VERSION "HNNBNNNYNNNNNNNNNNNNNNNNNNNNNNNNNNNNNNNNNN/4/%%%/4/'%**4NNN///"

NS_ :

BS_:

BU_: ecu_pri3_1 ecu_pri3_2 ecu_sec1_1 ecu_pri1_1 ecu_sec1_2 unused_8 unused_2 ecu_sec3_2 ecu_sec3_1 unused_1 unused_4 unused_9 unused_3 ecu_pri3_3 unused_6 unused_5 unused_7 measure

BO_ 3221225472 VECTOR__INDEPENDENT_SIG_MSG: 0 Vector__XXX
 SG_ signal5166 : 0|64@1+ (1,0) [0|1] "" Vector__XXX
 SG_ signal12359 : 0|64@1+ (1,0) [0|1] "" Vector__XXX
 SG_ signal12444 : 0|64@1+ (1,0) [0|1] "" Vector__XXX

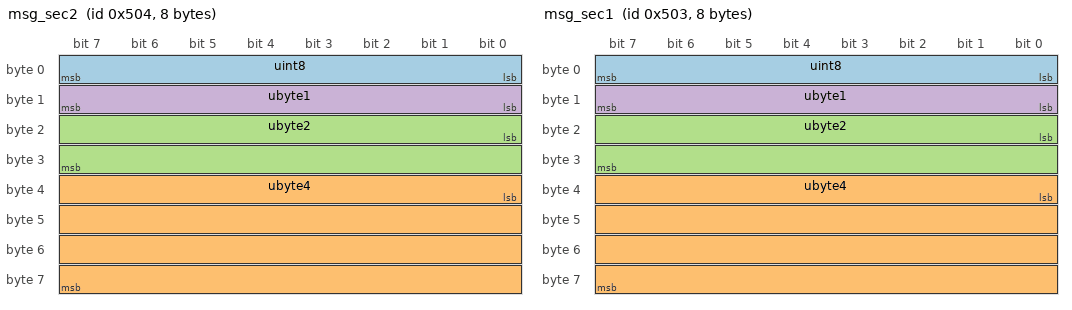
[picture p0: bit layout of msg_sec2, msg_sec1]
BO_ 1284 msg_sec2: 8 ecu_sec3_1
 SG_ uint8 : 0|8@1+ (1,0) [0|0] ""  unused_9,unused_8,unused_7,unused_6,unused_5,unused_4,unused_3,unused_2,unused_1,measure
 SG_ ubyte4 : 32|32@1+ (1,0) [0|0] ""  unused_9,unused_8,unused_7,unused_6,unused_5,unused_4,unused_3,unused_2,unused_1,measure
 SG_ ubyte2 : 16|16@1+ (1,0) [0|0] ""  unused_9,unused_8,unused_7,unused_6,unused_5,unused_4,unused_3,unused_2,unused_1,measure
 SG_ ubyte1 : 8|8@1+ (1,0) [0|0] ""  unused_9,unused_8,unused_7,unused_6,unused_5,unused_4,unused_3,unused_2,unused_1,measure

BO_ 1283 msg_sec1: 8 ecu_sec1_1
 SG_ uint8 : 0|8@1+ (1,0) [0|0] ""  unused_9,unused_8,unused_7,unused_6,unused_5,unused_4,unused_3,unused_2,unused_1,measure
 SG_ ubyte4 : 32|32@1+ (1,0) [0|0] ""  unused_9,unused_8,unused_7,unused_6,unused_5,unused_4,unused_3,unused_2,unused_1,measure
 SG_ ubyte2 : 16|16@1+ (1,0) [0|0] ""  unused_9,unused_8,unused_7,unused_6,unused_5,unused_4,unused_3,unused_2,unused_1,measure
 SG_ ubyte1 : 8|8@1+ (1,0) [0|0] ""  unused_9,unused_8,unused_7,unused_6,unused_5,unused_4,unused_3,unused_2,unused_1,measure

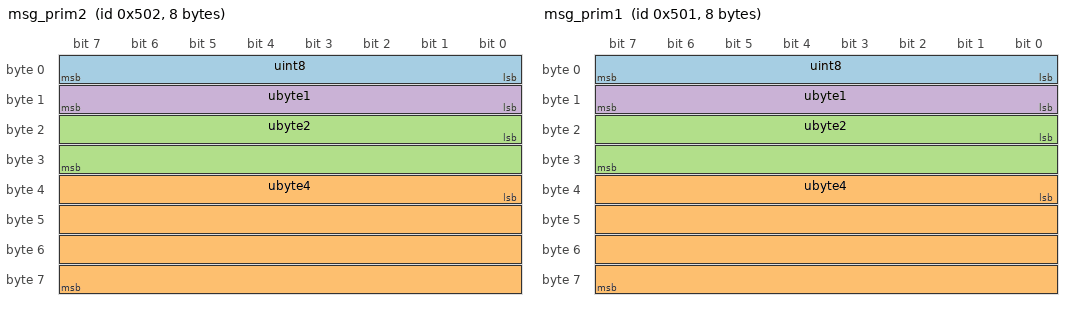
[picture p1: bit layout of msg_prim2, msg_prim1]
BO_ 1282 msg_prim2: 8 ecu_pri3_1
 SG_ uint8 : 0|8@1+ (1,0) [0|0] ""  unused_9,unused_8,unused_7,unused_6,unused_5,unused_4,unused_3,unused_2,unused_1,measure
 SG_ ubyte4 : 32|32@1+ (1,0) [0|0] ""  unused_9,unused_8,unused_7,unused_6,unused_5,unused_4,unused_3,unused_2,unused_1,measure
 SG_ ubyte2 : 16|16@1+ (1,0) [0|0] ""  unused_9,unused_8,unused_7,unused_6,unused_5,unused_4,unused_3,unused_2,unused_1,measure
 SG_ ubyte1 : 8|8@1+ (1,0) [0|0] ""  unused_9,unused_8,unused_7,unused_6,unused_5,unused_4,unused_3,unused_2,unused_1,measure

BO_ 1281 msg_prim1: 8 ecu_pri1_1
 SG_ uint8 : 0|8@1+ (1,0) [0|0] ""  unused_9,unused_8,unused_7,unused_6,unused_5,unused_4,unused_3,unused_2,unused_1,measure
 SG_ ubyte4 : 32|32@1+ (1,0) [0|0] ""  unused_9,unused_8,unused_7,unused_6,unused_5,unused_4,unused_3,unused_2,unused_1,measure
 SG_ ubyte2 : 16|16@1+ (1,0) [0|0] ""  unused_9,unused_8,unused_7,unused_6,unused_5,unused_4,unused_3,unused_2,unused_1,measure
 SG_ ubyte1 : 8|8@1+ (1,0) [0|0] ""  unused_9,unused_8,unused_7,unused_6,unused_5,unused_4,unused_3,unused_2,unused_1,measure

BO_ 64 msg_1027: 8 ecu_pri3_1
 SG_ signal1032 : 0|8@1+ (1,0) [0|255] ""  ecu_pri3_2,ecu_pri1_1,ecu_sec3_1,unused_1,unused_4,measure
 SG_ signal1027_BZ : 8|4@1+ (1,0) [0|15] ""  ecu_pri3_2,ecu_pri1_1,ecu_sec3_1,unused_1,unused_4,measure
 SG_ signal1062 : 16|1@1+ (1,0) [0|1] ""  ecu_pri1_1,measure
 SG_ signal1073 : 17|1@1+ (1,0) [0|1] ""  ecu_pri1_1,measure
 SG_ signal1084 : 18|1@1+ (1,0) [0|1] ""  ecu_pri1_1,measure
 SG_ signal1095 : 19|1@1+ (1,0) [0|1] ""  ecu_pri1_1,measure
 SG_ signal1106 : 20|1@1+ (1,0) [0|1] ""  ecu_pri1_1,measure
 SG_ signal1117 : 21|3@1+ (1,0) [0|7] ""  ecu_pri1_1,ecu_sec3_1,unused_1,unused_4,unused_6,measure
 SG_ signal1132 : 24|1@1+ (1,0) [0|1] ""  ecu_pri1_1,measure
 SG_ signal1143 : 25|1@1+ (1,0) [0|1] ""  ecu_pri1_1,measure
 SG_ signal1154 : 26|1@1+ (1,0) [0|1] ""  ecu_pri1_1,measure
 SG_ signal1165 : 27|1@1+ (1,0) [0|1] ""  ecu_pri1_1,measure
 SG_ signal1176 : 28|1@1+ (1,0) [0|1] ""  ecu_pri1_1,measure
 SG_ signal1187 : 29|1@1+ (1,0) [0|1] ""  ecu_pri1_1,ecu_sec3_1,unused_1,unused_4,unused_6,measure
 SG_ signal1202 : 30|2@1+ (1,0) [0|3] ""  ecu_pri1_1,measure
 SG_ signal1213 : 32|1@1+ (1,0) [0|1] ""  ecu_pri3_2,ecu_pri1_1,measure
 SG_ signal1225 : 33|1@1+ (1,0) [0|1] ""  ecu_pri1_1,measure
 SG_ signal1236 : 34|2@1+ (1,0) [0|3] ""  ecu_pri1_1,measure
 SG_ signal1247 : 40|8@1+ (1,0) [0|255] ""  ecu_pri1_1,measure
 SG_ signal1258 : 48|8@1+ (1,0) [0|255] ""  ecu_pri1_1,measure
 SG_ signal1269 : 56|7@1+ (1,0) [0|127] ""  ecu_pri1_1,measure
 SG_ signal1280 : 63|1@1+ (1,0) [0|1] ""  ecu_pri1_1,measure

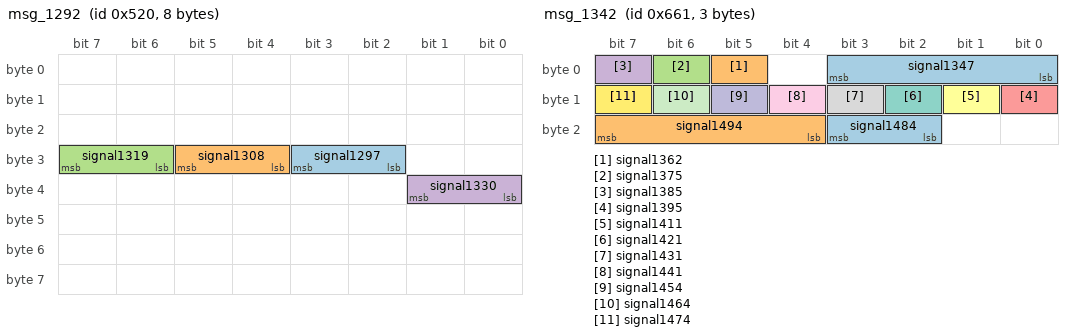
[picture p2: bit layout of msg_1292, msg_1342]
BO_ 1312 msg_1292: 8 ecu_pri3_1
 SG_ signal1297 : 26|2@1+ (1,0) [0|3] ""  ecu_pri1_1,measure
 SG_ signal1308 : 28|2@1+ (1,0) [0|3] ""  ecu_pri1_1,measure
 SG_ signal1319 : 30|2@1+ (1,0) [0|3] ""  ecu_pri1_1,measure
 SG_ signal1330 : 32|2@1+ (1,0) [0|3] ""  ecu_pri1_1,measure

BO_ 1633 msg_1342: 3 ecu_pri1_1
 SG_ signal1347 : 0|4@1+ (1,0) [0|15] ""  ecu_sec1_2,unused_8,ecu_sec3_1,unused_1,unused_4,measure
 SG_ signal1362 : 5|1@1+ (1,0) [0|1] ""  ecu_sec3_1,unused_1,unused_4,measure
 SG_ signal1375 : 6|1@1+ (1,0) [0|1] ""  unused_7,measure
 SG_ signal1385 : 7|1@1+ (1,0) [0|1] ""  unused_7,measure
 SG_ signal1395 : 8|1@1+ (1,0) [0|1] ""  ecu_sec1_2,unused_8,unused_2,ecu_sec3_1,unused_1,unused_4,measure
 SG_ signal1411 : 9|1@1+ (1,0) [0|1] ""  unused_7,measure
 SG_ signal1421 : 10|1@1+ (1,0) [0|1] ""  unused_7,measure
 SG_ signal1431 : 11|1@1+ (1,0) [0|1] ""  unused_7,measure
 SG_ signal1441 : 12|1@1+ (1,0) [0|1] ""  ecu_sec3_1,unused_1,unused_4,measure
 SG_ signal1454 : 13|1@1+ (1,0) [0|1] ""  unused_7,measure
 SG_ signal1464 : 14|1@1+ (1,0) [0|1] ""  unused_7,measure
 SG_ signal1474 : 15|1@1+ (1,0) [0|1] ""  unused_7,measure
 SG_ signal1484 : 18|2@1+ (1,0) [0|3] ""  unused_7,measure
 SG_ signal1494 : 20|4@1+ (1,0) [0|15] ""  unused_7,measure

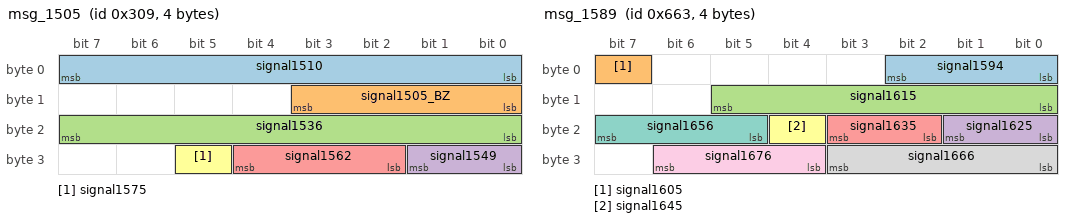
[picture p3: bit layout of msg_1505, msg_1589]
BO_ 777 msg_1505: 4 ecu_pri1_1
 SG_ signal1510 : 0|8@1+ (1,0) [0|255] ""  ecu_sec3_1,unused_1,unused_4,measure
 SG_ signal1505_BZ : 8|4@1+ (1,0) [0|15] ""  ecu_sec3_1,unused_1,unused_4,measure
 SG_ signal1536 : 16|8@1+ (50,0) [0|12700] "W"  ecu_sec3_1,unused_1,unused_4,measure
 SG_ signal1549 : 24|2@1+ (1,0) [0|3] ""  ecu_sec3_1,unused_1,unused_4,measure
 SG_ signal1562 : 26|3@1+ (1,0) [0|7] ""  ecu_sec3_1,unused_1,unused_4,measure
 SG_ signal1575 : 29|1@1+ (1,0) [0|1] ""  ecu_sec3_1,unused_1,unused_4,measure

BO_ 1635 msg_1589: 4 ecu_pri1_1
 SG_ signal1594 : 0|3@1+ (1,0) [0|7] ""  unused_6,measure
 SG_ signal1605 : 7|1@1+ (1,0) [0|1] ""  unused_7,measure
 SG_ signal1615 : 8|6@1+ (50,-1000) [-1000|1000] "W"  unused_7,measure
 SG_ signal1625 : 16|2@1+ (1,0) [0|3] ""  unused_7,measure
 SG_ signal1635 : 18|2@1+ (1,0) [0|3] ""  unused_7,measure
 SG_ signal1645 : 20|1@1+ (1,0) [0|1] ""  unused_6,measure
 SG_ signal1656 : 21|3@1+ (1,0) [0|7] ""  unused_7,measure
 SG_ signal1666 : 24|4@1+ (10,0) [0|100] "%"  unused_7,measure
 SG_ signal1676 : 28|3@1+ (1,0) [0|7] ""  unused_7,measure

BO_ 482 msg_1687: 8 ecu_pri1_1
 SG_ signal1692 : 0|64@1+ (1,0) [0|1] ""  ecu_sec1_2,unused_8,unused_2,measure

BO_ 490 msg_1706: 8 ecu_sec1_2
 SG_ signal1706_Data : 0|64@1+ (1,0) [0|1] ""  unused_7,measure

BO_ 480 msg_1722: 8 ecu_pri1_1
 SG_ signal1727 : 0|64@1+ (1,0) [0|1] ""  ecu_sec3_1,unused_1,unused_4,measure

BO_ 2616986624 msg_1741: 8 unused_7
 SG_ signal1746 : 0|64@1+ (1,0) [0|1] ""  ecu_sec3_1,unused_1,unused_4,measure

BO_ 488 msg_1760: 8 ecu_sec3_1
 SG_ signal1765 : 0|64@1+ (1,0) [0|1] ""  unused_7,measure

BO_ 2616986625 msg_1776: 8 unused_4
 SG_ signal1781 : 0|64@1+ (1,0) [0|1] ""  unused_7,measure

BO_ 481 msg_1792: 8 ecu_pri1_1
 SG_ signal1792_Data : 0|64@1+ (1,0) [0|1] ""  unused_9,measure

BO_ 2616986629 msg_1809: 8 unused_7
 SG_ signal1814 : 0|64@1+ (1,0) [0|1] ""  unused_9,measure

BO_ 489 msg_1826: 8 unused_9
 SG_ signal1831 : 0|64@1+ (1,0) [0|1] ""  unused_7,measure

BO_ 2616986630 msg_1842: 8 unused_9
 SG_ signal1842_Data : 0|64@1+ (1,0) [0|1] ""  unused_7,measure

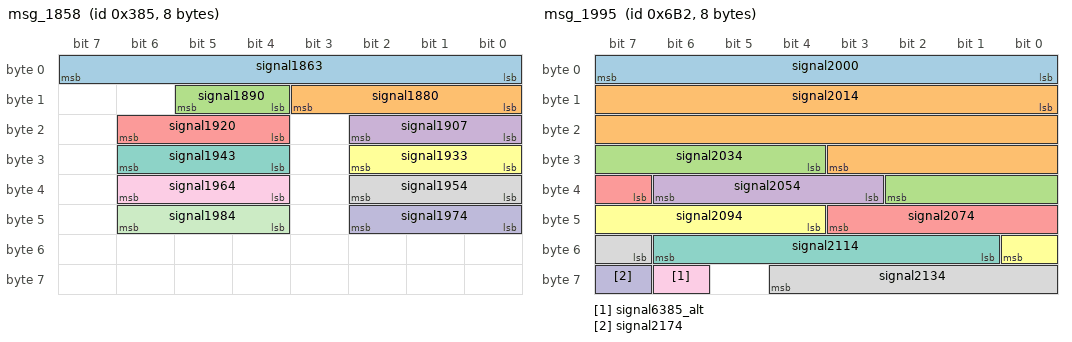
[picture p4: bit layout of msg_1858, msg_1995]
BO_ 901 msg_1858: 8 ecu_pri1_1
 SG_ signal1863 : 0|8@1+ (1,0) [0|255] ""  ecu_sec1_2,unused_8,unused_2,ecu_sec3_1,unused_1,unused_4,ecu_pri3_3,measure
 SG_ signal1880 : 8|4@1+ (1,0) [0|15] ""  unused_7,measure
 SG_ signal1890 : 12|2@1+ (1,0) [0|3] ""  ecu_sec1_2,unused_8,unused_2,ecu_sec3_1,unused_1,unused_4,ecu_pri3_3,measure
 SG_ signal1907 : 16|3@1+ (1,0) [0|7] ""  ecu_sec3_1,unused_1,unused_4,measure
 SG_ signal1920 : 20|3@1+ (1,0) [0|7] ""  ecu_sec1_2,unused_8,unused_2,measure
 SG_ signal1933 : 24|3@1+ (1,0) [0|7] ""  unused_7,measure
 SG_ signal1943 : 28|3@1+ (1,0) [0|7] ""  ecu_pri3_3,measure
 SG_ signal1954 : 32|3@1+ (1,0) [0|7] ""  unused_7,measure
 SG_ signal1964 : 36|3@1+ (1,0) [0|7] ""  unused_7,measure
 SG_ signal1974 : 40|3@1+ (1,0) [0|7] ""  unused_7,measure
 SG_ signal1984 : 44|3@1+ (1,0) [0|7] ""  unused_7,measure

BO_ 1714 msg_1995: 8 ecu_pri1_1
 SG_ signal2000 : 0|8@1+ (1,0) [0|254] ""  ecu_pri3_1,ecu_pri3_2,ecu_pri3_3,unused_6,measure
 SG_ signal2014 : 8|20@1+ (1,0) [0|1048573] "km"  ecu_pri3_1,ecu_pri3_2,ecu_sec1_2,unused_8,unused_2,ecu_sec3_1,unused_1,unused_4,ecu_pri3_3,unused_6,measure
 SG_ signal2034 : 28|7@1+ (1,2000) [2000|2127] ""  ecu_pri3_1,ecu_pri3_2,ecu_sec1_2,unused_8,unused_2,ecu_sec3_1,unused_1,unused_4,ecu_pri3_3,unused_6,measure
 SG_ signal2054 : 35|4@1+ (1,0) [1|12] "month"  ecu_pri3_1,ecu_pri3_2,ecu_sec1_2,unused_8,unused_2,ecu_sec3_1,unused_1,unused_4,ecu_pri3_3,unused_6,measure
 SG_ signal2074 : 39|5@1+ (1,0) [1|31] "d"  ecu_pri3_1,ecu_pri3_2,ecu_sec1_2,unused_8,unused_2,ecu_sec3_1,unused_1,unused_4,ecu_pri3_3,unused_6,measure
 SG_ signal2094 : 44|5@1+ (1,0) [0|23] "h"  ecu_pri3_1,ecu_pri3_2,ecu_sec1_2,unused_8,unused_2,ecu_sec3_1,unused_1,unused_4,ecu_pri3_3,unused_6,measure
 SG_ signal2114 : 49|6@1+ (1,0) [0|59] "min"  ecu_pri3_1,ecu_pri3_2,ecu_sec1_2,unused_8,unused_2,ecu_sec3_1,unused_1,unused_4,ecu_pri3_3,unused_6,measure
 SG_ signal2134 : 55|6@1+ (1,0) [0|59] "s"  ecu_pri3_1,ecu_pri3_2,ecu_sec1_2,unused_8,unused_2,ecu_sec3_1,unused_1,unused_4,ecu_pri3_3,unused_6,measure
 SG_ signal6385_alt : 62|1@1+ (1,0) [0|1] ""  ecu_pri3_1,ecu_pri3_2,ecu_sec1_2,unused_8,unused_2,ecu_sec3_1,unused_1,unused_4,ecu_pri3_3,unused_6,measure
 SG_ signal2174 : 63|1@1+ (1,0) [0|1] ""  ecu_pri3_1,ecu_pri3_2,ecu_sec1_2,unused_8,unused_2,ecu_sec3_1,unused_1,unused_4,ecu_pri3_3,unused_6,measure

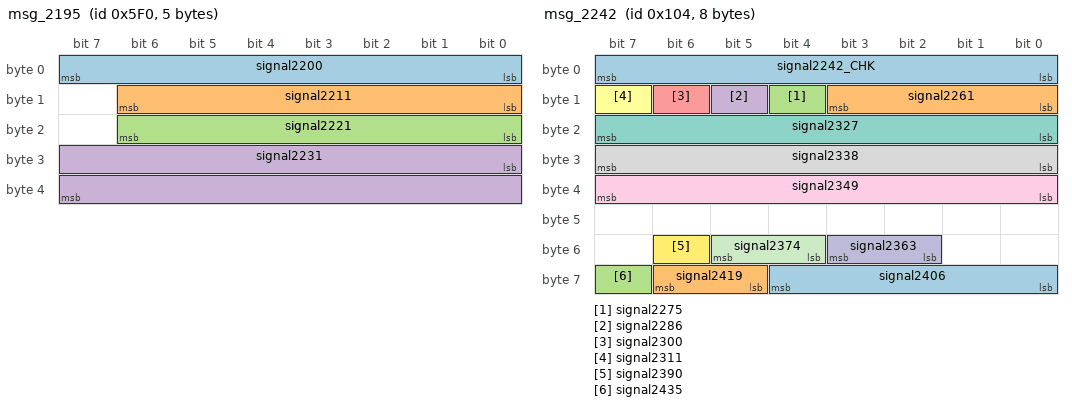
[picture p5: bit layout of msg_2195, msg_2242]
BO_ 1520 msg_2195: 5 ecu_pri1_1
 SG_ signal2200 : 0|8@1+ (1,0) [0|253] ""  ecu_pri3_1,measure
 SG_ signal2211 : 8|7@1+ (1,0) [0|100] "%"  unused_7,measure
 SG_ signal2221 : 16|7@1+ (1,0) [0|100] "%"  unused_7,measure
 SG_ signal2231 : 24|16@1+ (1,0) [0|65535] ""  unused_7,measure

BO_ 260 msg_2242: 8 ecu_pri3_2
 SG_ signal2242_CHK : 0|8@1+ (1,0) [0|255] ""  ecu_pri1_1,ecu_sec3_1,unused_1,unused_4,measure
 SG_ signal2261 : 8|4@1+ (1,0) [0|15] ""  ecu_pri1_1,ecu_sec3_1,unused_1,unused_4,measure
 SG_ signal2275 : 12|1@1+ (1,0) [0|1] ""  ecu_pri1_1,measure
 SG_ signal2286 : 13|1@1+ (1,0) [0|1] ""  ecu_pri1_1,ecu_sec3_1,unused_1,unused_4,measure
 SG_ signal2300 : 14|1@1+ (1,0) [0|1] ""  ecu_pri1_1,measure
 SG_ signal2311 : 15|1@1+ (1,0) [0|1] ""  ecu_pri1_1,ecu_sec1_2,unused_8,ecu_sec3_1,unused_1,unused_4,measure
 SG_ signal2327 : 16|8@1+ (0.048,-7.968) [-7.968|4.224] "signal5121"  ecu_pri1_1,measure
 SG_ signal2338 : 24|8@1+ (1,-128) [-128|126] "%g"  ecu_pri1_1,measure
 SG_ signal2349 : 32|8@1+ (0.4,0) [8|92] "%"  ecu_pri1_1,ecu_sec3_1,unused_1,unused_4,measure
 SG_ signal2363 : 50|2@1+ (1,0) [0|3] ""  ecu_pri1_1,measure
 SG_ signal2374 : 52|2@1+ (1,0) [0|3] ""  ecu_pri1_1,ecu_sec1_2,unused_8,ecu_sec3_1,unused_1,unused_4,measure
 SG_ signal2390 : 54|1@1+ (1,0) [0|1] ""  ecu_pri1_1,ecu_sec1_2,unused_8,ecu_sec3_1,unused_1,unused_4,measure
 SG_ signal2406 : 56|5@1+ (1,0) [0|29] "kN"  ecu_pri1_1,ecu_sec1_2,unused_8,measure
 SG_ signal2419 : 61|2@1+ (1,0) [0|3] ""  ecu_pri1_1,ecu_sec1_2,unused_8,ecu_sec3_1,unused_1,unused_4,measure
 SG_ signal2435 : 63|1@1+ (1,0) [0|1] ""  ecu_pri1_1,measure

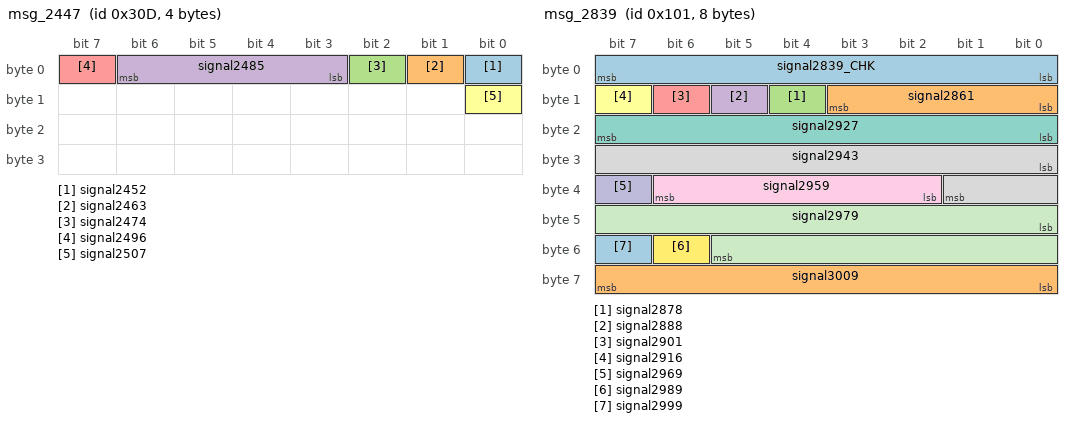
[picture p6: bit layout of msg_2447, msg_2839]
BO_ 781 msg_2447: 4 ecu_pri3_2
 SG_ signal2452 : 0|1@1+ (1,0) [0|1] ""  ecu_pri1_1,measure
 SG_ signal2463 : 1|1@1+ (1,0) [0|1] ""  ecu_pri1_1,measure
 SG_ signal2474 : 2|1@1+ (1,0) [0|1] ""  ecu_pri1_1,measure
 SG_ signal2485 : 3|4@1+ (1,0) [0|15] ""  ecu_pri1_1,measure
 SG_ signal2496 : 7|1@1+ (1,0) [0|1] ""  ecu_pri1_1,measure
 SG_ signal2507 : 8|1@1+ (1,0) [0|1] ""  ecu_pri1_1,measure

BO_ 256 msg_2519: 8 ecu_pri1_1
 SG_ signal2524 : 0|8@1+ (1,0) [0|255] ""  ecu_pri3_1,ecu_pri3_2,ecu_sec1_2,unused_8,unused_2,ecu_sec3_1,unused_1,unused_4,measure
 SG_ signal2519_BZ : 8|4@1+ (1,0) [0|15] ""  ecu_pri3_1,ecu_pri3_2,ecu_sec1_2,unused_8,unused_2,ecu_sec3_1,unused_1,unused_4,measure
 SG_ signal2560 : 12|10@1+ (1,0) [0|1021] ""  ecu_pri3_1,ecu_sec1_2,unused_8,ecu_sec3_1,unused_1,unused_4,measure
 SG_ signal2576 : 22|10@1+ (1,0) [0|1021] ""  ecu_pri3_1,ecu_sec1_2,unused_8,ecu_sec3_1,unused_1,unused_4,measure
 SG_ signal2592 : 32|16@1+ (0.01,0) [0|655.32] "km/h"  ecu_pri3_1,ecu_sec1_2,unused_8,ecu_sec3_1,unused_1,unused_4,measure
 SG_ signal2608 : 48|1@1+ (1,0) [0|1] ""  ecu_pri3_1,ecu_sec1_2,unused_8,unused_2,ecu_sec3_1,unused_1,unused_4,measure
 SG_ signal2625 : 49|1@1+ (1,0) [0|1] ""  ecu_pri3_1,ecu_sec1_2,unused_8,unused_2,ecu_sec3_1,unused_1,unused_4,measure
 SG_ signal2642 : 50|1@1+ (1,0) [0|1] ""  ecu_pri3_1,ecu_pri3_2,ecu_sec3_1,unused_1,unused_4,measure
 SG_ signal2657 : 51|2@1+ (1,0) [0|3] ""  ecu_pri3_1,ecu_sec1_2,unused_8,unused_2,measure
 SG_ signal2671 : 53|1@1+ (1,0) [0|1] ""  ecu_sec3_1,unused_1,unused_4,measure
 SG_ signal2684 : 54|1@1+ (1,0) [0|1] ""  ecu_sec3_1,unused_1,unused_4,measure
 SG_ signal2697 : 55|1@1+ (1,0) [0|1] ""  ecu_pri3_1,ecu_sec1_2,unused_8,ecu_sec3_1,unused_1,unused_4,measure
 SG_ signal2713 : 56|1@1+ (1,0) [0|1] ""  ecu_pri3_1,ecu_pri3_2,ecu_sec1_2,unused_8,unused_2,ecu_sec3_1,unused_1,unused_4,measure
 SG_ signal2731 : 57|1@1+ (1,0) [0|1] ""  ecu_pri3_1,ecu_pri3_2,ecu_sec1_2,unused_8,unused_2,ecu_sec3_1,unused_1,unused_4,measure
 SG_ signal2749 : 58|1@1+ (1,0) [0|1] ""  ecu_pri3_1,ecu_pri3_2,unused_2,ecu_sec3_1,unused_1,unused_4,measure
 SG_ signal2765 : 59|1@1+ (1,0) [0|1] ""  ecu_pri3_1,ecu_pri3_2,ecu_sec1_2,unused_8,ecu_sec3_1,unused_1,unused_4,measure
 SG_ signal2782 : 60|1@1+ (1,0) [0|1] ""  ecu_pri3_1,unused_2,ecu_sec3_1,unused_1,unused_4,measure
 SG_ signal2797 : 61|1@1+ (1,0) [0|1] ""  ecu_pri3_1,ecu_pri3_2,ecu_sec1_2,unused_8,unused_2,ecu_sec3_1,unused_1,unused_4,measure
 SG_ signal2815 : 62|1@1+ (1,0) [0|1] ""  ecu_sec3_1,unused_1,unused_4,measure
 SG_ signal2828 : 63|1@1+ (1,0) [0|1] ""  unused_7,measure

BO_ 257 msg_2839: 8 ecu_pri1_1
 SG_ signal2839_CHK : 0|8@1+ (1,0) [0|255] ""  ecu_pri3_2,ecu_sec1_2,unused_8,unused_2,ecu_sec3_1,unused_1,unused_4,measure
 SG_ signal2861 : 8|4@1+ (1,0) [0|15] ""  ecu_pri3_2,ecu_sec1_2,unused_8,unused_2,ecu_sec3_1,unused_1,unused_4,measure
 SG_ signal2878 : 12|1@1+ (1,0) [0|1] ""  unused_7,measure
 SG_ signal2888 : 13|1@1+ (1,0) [0|1] ""  ecu_sec3_1,unused_1,unused_4,measure
 SG_ signal2901 : 14|1@1+ (1,0) [0|1] ""  ecu_sec1_2,unused_8,ecu_sec3_1,unused_1,unused_4,measure
 SG_ signal2916 : 15|1@1+ (1,0) [0|1] ""  ecu_pri3_2,measure
 SG_ signal2927 : 16|8@1+ (0.01,-1.27) [-1.27001|1.26999] "g"  ecu_sec1_2,unused_8,unused_2,ecu_sec3_1,unused_1,unused_4,measure
 SG_ signal2943 : 24|10@1+ (0.03125,-16) [-16|15.90625] ""  ecu_sec1_2,unused_8,unused_2,ecu_sec3_1,unused_1,unused_4,measure
 SG_ signal2959 : 34|5@1+ (0.1,-1) [-1|1] ""  unused_7,measure
 SG_ signal2969 : 39|1@1+ (1,0) [0|1] ""  unused_7,measure
 SG_ signal2979 : 40|14@1+ (0.01,0) [0|163.82] "Deg/s"  unused_7,measure
 SG_ signal2989 : 54|1@1+ (1,0) [0|1] ""  unused_7,measure
 SG_ signal2999 : 55|1@1+ (1,0) [0|1] ""  unused_7,measure
 SG_ signal3009 : 56|8@1+ (1,0) [0|255] ""  unused_7,measure

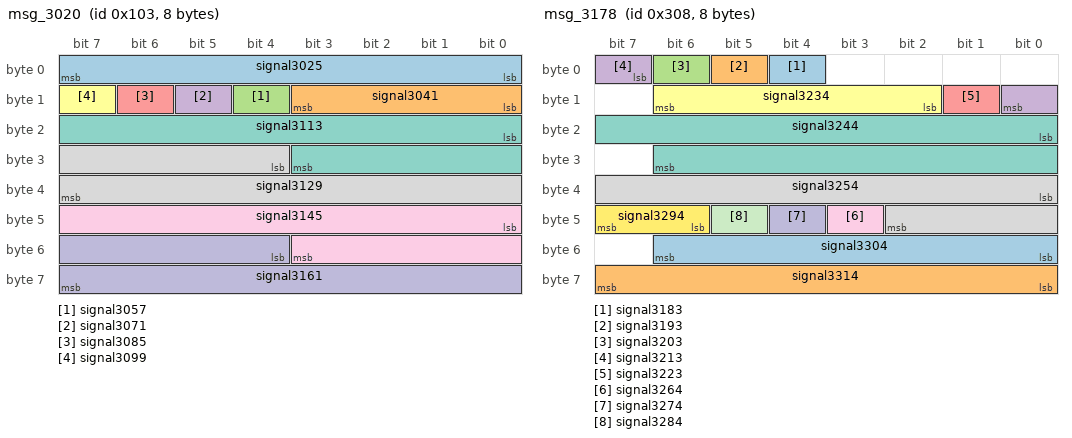
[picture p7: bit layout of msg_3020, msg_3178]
BO_ 259 msg_3020: 8 ecu_pri1_1
 SG_ signal3025 : 0|8@1+ (1,0) [0|255] ""  ecu_pri3_2,ecu_sec1_2,unused_8,unused_2,ecu_sec3_2,ecu_pri3_3,measure
 SG_ signal3041 : 8|4@1+ (1,0) [0|15] ""  ecu_pri3_2,ecu_sec1_2,unused_8,unused_2,ecu_sec3_2,ecu_pri3_3,measure
 SG_ signal3057 : 12|1@1+ (1,0) [0|1] ""  ecu_pri3_2,ecu_sec1_2,unused_8,ecu_pri3_3,measure
 SG_ signal3071 : 13|1@1+ (1,0) [0|1] ""  ecu_pri3_2,ecu_sec1_2,unused_8,ecu_pri3_3,measure
 SG_ signal3085 : 14|1@1+ (1,0) [0|1] ""  ecu_pri3_2,ecu_sec1_2,unused_8,ecu_pri3_3,measure
 SG_ signal3099 : 15|1@1+ (1,0) [0|1] ""  ecu_pri3_2,ecu_sec1_2,unused_8,ecu_pri3_3,measure
 SG_ signal3113 : 16|12@1+ (0.1,0) [0|409.2] "km/h"  ecu_pri3_2,ecu_sec1_2,unused_8,unused_2,ecu_sec3_2,ecu_pri3_3,measure
 SG_ signal3129 : 28|12@1+ (0.1,0) [0|409.2] "km/h"  ecu_pri3_2,ecu_sec1_2,unused_8,unused_2,ecu_sec3_2,ecu_pri3_3,measure
 SG_ signal3145 : 40|12@1+ (0.1,0) [0|409.2] "km/h"  ecu_pri3_2,ecu_sec1_2,unused_8,unused_2,ecu_sec3_2,ecu_pri3_3,measure
 SG_ signal3161 : 52|12@1+ (0.1,0) [0|409.2] "km/h"  ecu_pri3_2,ecu_sec1_2,unused_8,unused_2,ecu_sec3_2,ecu_pri3_3,measure

BO_ 776 msg_3178: 8 ecu_pri1_1
 SG_ signal3183 : 4|1@1+ (1,0) [0|1] ""  unused_7,measure
 SG_ signal3193 : 5|1@1+ (1,0) [0|1] ""  unused_7,measure
 SG_ signal3203 : 6|1@1+ (1,0) [0|1] ""  unused_7,measure
 SG_ signal3213 : 7|2@1+ (1,0) [0|3] ""  unused_7,measure
 SG_ signal3223 : 9|1@1+ (1,0) [0|1] ""  ecu_pri3_3,measure
 SG_ signal3234 : 10|5@1+ (1,0) [0|31] ""  unused_7,measure
 SG_ signal3244 : 16|15@1+ (0.002,0) [0|65.278] "1/s"  unused_7,measure
 SG_ signal3254 : 32|11@1+ (1,0) [0|2047] ""  unused_7,measure
 SG_ signal3264 : 43|1@1+ (1,0) [0|1] ""  unused_7,measure
 SG_ signal3274 : 44|1@1+ (1,0) [0|1] ""  unused_7,measure
 SG_ signal3284 : 45|1@1+ (1,0) [0|1] ""  unused_7,measure
 SG_ signal3294 : 46|2@1+ (1,0) [0|3] ""  unused_7,measure
 SG_ signal3304 : 48|7@1+ (0.32,0) [0|39.68] "km/h"  unused_7,measure
 SG_ signal3314 : 56|8@1+ (1,0) [0|255] ""  unused_7,measure

BO_ 262 msg_3325: 8 ecu_pri1_1
 SG_ signal3330 : 0|8@1+ (1,0) [0|255] ""  ecu_pri3_2,ecu_sec1_2,unused_8,unused_2,ecu_sec3_1,unused_1,unused_4,ecu_pri3_3,measure
 SG_ signal3348 : 8|4@1+ (1,0) [0|15] ""  ecu_pri3_2,ecu_sec1_2,unused_8,unused_2,ecu_sec3_1,unused_1,unused_4,ecu_pri3_3,measure
 SG_ signal3366 : 12|1@1+ (1,0) [0|1] ""  ecu_pri3_2,ecu_sec1_2,unused_8,ecu_sec3_1,unused_1,unused_4,measure
 SG_ signal3382 : 13|1@1+ (1,0) [0|1] ""  ecu_sec3_1,unused_1,unused_4,measure
 SG_ signal3395 : 14|2@1+ (1,0) [0|3] ""  unused_7,measure
 SG_ signal3405 : 16|10@1+ (0.3,-30) [-30|276.58978] "bar"  ecu_pri3_2,ecu_sec1_2,unused_8,ecu_sec3_1,unused_1,unused_4,measure
 SG_ signal3421 : 26|1@1+ (1,0) [0|1] ""  ecu_sec3_1,unused_1,unused_4,measure
 SG_ signal3434 : 27|1@1+ (1,0) [0|1] ""  ecu_sec1_2,unused_8,ecu_sec3_1,unused_1,unused_4,measure
 SG_ signal3449 : 28|1@1+ (1,0) [0|1] ""  ecu_pri3_3,measure
 SG_ signal3460 : 29|1@1+ (1,0) [0|1] ""  ecu_sec3_1,unused_1,unused_4,measure
 SG_ signal3473 : 30|1@1+ (1,0) [0|1] ""  unused_7,measure
 SG_ signal3483 : 31|1@1+ (1,0) [0|1] ""  unused_7,measure
 SG_ signal3493 : 32|1@1+ (1,0) [0|1] ""  ecu_sec3_1,unused_1,unused_4,measure
 SG_ signal3506 : 33|1@1+ (1,0) [0|1] ""  ecu_sec3_1,unused_1,unused_4,measure
 SG_ signal3519 : 34|1@1+ (1,0) [0|1] ""  ecu_sec3_1,unused_1,unused_4,measure
 SG_ signal3532 : 35|1@1+ (1,0) [0|1] ""  ecu_pri3_2,measure
 SG_ signal3543 : 36|1@1+ (1,0) [0|1] ""  ecu_sec3_1,unused_1,unused_4,measure
 SG_ signal3556 : 44|1@1+ (1,0) [0|1] ""  unused_7,measure
 SG_ signal3566 : 45|1@1+ (1,0) [0|1] ""  unused_7,measure
 SG_ signal3576 : 46|1@1+ (1,0) [0|1] ""  unused_7,measure
 SG_ signal3586 : 47|1@1+ (1,0) [0|1] ""  unused_7,measure
 SG_ signal3596 : 48|8@1+ (4,0) [0|256] "mbar"  unused_7,measure
 SG_ signal3606 : 56|1@1+ (1,0) [0|1] ""  ecu_pri3_2,unused_2,measure
 SG_ signal3618 : 57|1@1+ (1,0) [0|1] ""  ecu_pri3_2,measure
 SG_ signal3629 : 58|1@1+ (1,0) [0|1] ""  ecu_pri3_2,ecu_sec1_2,unused_8,measure
 SG_ signal3642 : 59|1@1+ (1,0) [0|1] ""  ecu_sec3_1,unused_1,unused_4,measure
 SG_ signal3655 : 60|1@1+ (1,0) [0|1] ""  ecu_pri3_2,measure
 SG_ signal3666 : 61|1@1+ (1,0) [0|1] ""  ecu_pri3_2,ecu_sec3_1,unused_1,unused_4,measure
 SG_ signal3680 : 62|2@1+ (1,0) [0|3] ""  ecu_pri3_2,measure

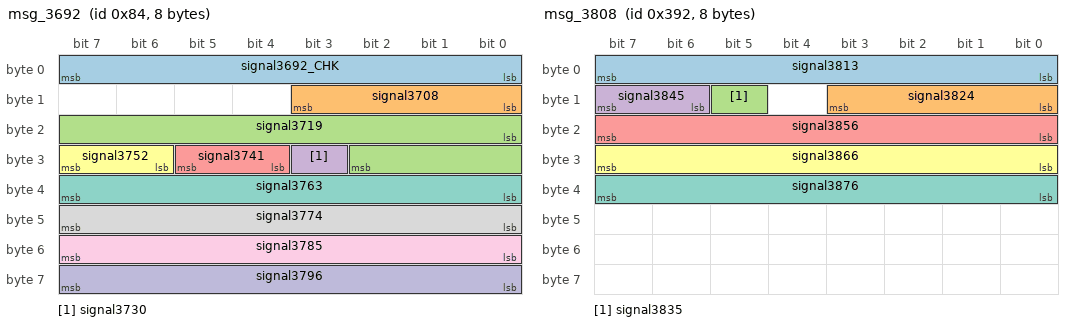
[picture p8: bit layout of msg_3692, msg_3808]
BO_ 132 msg_3692: 8 ecu_sec1_1
 SG_ signal3692_CHK : 0|8@1+ (1,0) [0|255] ""  ecu_pri3_3,measure
 SG_ signal3708 : 8|4@1+ (1,0) [0|15] ""  ecu_pri3_3,measure
 SG_ signal3719 : 16|11@1+ (0.1,0) [0|204.7] "Degr"  ecu_pri3_3,measure
 SG_ signal3730 : 27|1@1+ (1,0) [0|1] ""  ecu_pri3_3,measure
 SG_ signal3741 : 28|2@1+ (1,0) [0|3] ""  ecu_pri3_3,measure
 SG_ signal3752 : 30|2@1+ (1,0) [0|3] ""  ecu_pri3_3,measure
 SG_ signal3763 : 32|8@1+ (1,0) [0|255] ""  ecu_pri3_3,measure
 SG_ signal3774 : 40|8@1+ (1,0) [0|255] ""  ecu_pri3_3,measure
 SG_ signal3785 : 48|8@1+ (1,0) [0|255] ""  ecu_pri3_3,measure
 SG_ signal3796 : 56|8@1+ (1,0) [0|255] ""  ecu_pri3_3,measure

BO_ 914 msg_3808: 8 ecu_pri1_1
 SG_ signal3813 : 0|8@1+ (1,0) [0|255] ""  ecu_sec3_2,measure
 SG_ signal3824 : 8|4@1+ (1,0) [0|15] ""  ecu_sec3_2,measure
 SG_ signal3835 : 13|1@1+ (1,0) [0|1] ""  unused_7,measure
 SG_ signal3845 : 14|2@1+ (1,0) [0|3] ""  ecu_sec3_2,measure
 SG_ signal3856 : 16|8@1+ (0.048828125,-6.20117) [-6.20118|6.15028] "%"  unused_7,measure
 SG_ signal3866 : 24|8@1+ (0.048828125,-6.20117) [-6.20118|6.15028] "%"  unused_7,measure
 SG_ signal3876 : 32|8@1+ (0.048828125,-6.20117) [-6.20118|6.15028] "%"  unused_7,measure

BO_ 924 msg_3887: 8 ecu_pri1_1
 SG_ signal3892 : 0|1@1+ (1,0) [0|1] ""  ecu_pri3_2,ecu_sec3_1,unused_1,unused_4,measure
 SG_ signal3906 : 1|1@1+ (1,0) [0|1] ""  ecu_sec3_1,measure
 SG_ signal3917 : 2|1@1+ (1,0) [0|1] ""  unused_6,measure
 SG_ signal3928 : 3|1@1+ (1,0) [0|1] ""  ecu_pri3_2,ecu_sec3_1,unused_1,unused_4,measure
 SG_ signal3942 : 4|1@1+ (1,0) [0|1] ""  ecu_sec3_1,unused_1,unused_4,measure
 SG_ signal3955 : 5|1@1+ (1,0) [0|1] ""  unused_7,measure
 SG_ signal3965 : 6|1@1+ (1,0) [0|1] ""  unused_7,measure
 SG_ signal3975 : 7|1@1+ (1,0) [0|1] ""  unused_7,measure
 SG_ signal3985 : 8|1@1+ (1,0) [0|1] ""  unused_7,measure
 SG_ signal3995 : 9|1@1+ (1,0) [0|1] ""  ecu_sec3_1,unused_1,unused_4,measure
 SG_ signal4008 : 10|1@1+ (1,0) [0|1] ""  ecu_sec3_1,unused_1,unused_4,measure
 SG_ signal7888_alt : 11|1@1+ (1,0) [0|1] ""  unused_6,measure
 SG_ signal4032 : 12|1@1+ (1,0) [0|1] ""  unused_7,measure
 SG_ signal4042 : 13|1@1+ (1,0) [0|1] ""  unused_7,measure
 SG_ signal4052 : 14|1@1+ (1,0) [0|1] ""  unused_7,measure
 SG_ signal4062 : 15|1@1+ (1,0) [0|1] ""  unused_7,measure
 SG_ signal4072 : 16|1@1+ (1,0) [0|1] ""  ecu_sec3_1,unused_1,unused_4,measure
 SG_ signal4085 : 17|1@1+ (1,0) [0|1] ""  ecu_sec3_1,measure
 SG_ signal4096 : 18|1@1+ (1,0) [0|1] ""  ecu_pri3_2,ecu_sec3_1,unused_1,unused_4,measure
 SG_ signal4110 : 20|1@1+ (1,0) [0|1] ""  unused_6,measure
 SG_ signal4121 : 21|1@1+ (1,0) [0|1] ""  ecu_pri3_2,measure
 SG_ signal3845 : 22|2@1+ (1,0) [0|3] ""  ecu_sec3_1,unused_1,unused_4,measure
 SG_ signal4145 : 32|1@1+ (1,0) [0|1] ""  unused_7,measure
 SG_ signal4155 : 33|1@1+ (1,0) [0|1] ""  ecu_sec3_1,unused_1,unused_4,measure
 SG_ signal4168 : 34|1@1+ (1,0) [0|1] ""  unused_6,measure
 SG_ signal4179 : 35|1@1+ (1,0) [0|1] ""  unused_7,measure
 SG_ signal4189 : 36|4@1+ (1,0) [0|15] ""  ecu_sec3_1,unused_1,unused_4,measure
 SG_ signal4202 : 40|8@1+ (0.5,-50) [-50|76] "Celsius"  ecu_sec3_1,unused_1,unused_4,measure
 SG_ signal4215 : 48|1@1+ (1,0) [0|1] ""  ecu_sec3_1,unused_1,unused_4,measure
 SG_ signal4228 : 49|1@1+ (1,0) [0|1] ""  unused_7,measure
 SG_ signal4238 : 50|1@1+ (1,0) [0|1] ""  unused_7,measure
 SG_ signal4248 : 51|1@1+ (1,0) [0|1] ""  unused_7,measure
 SG_ signal4258 : 52|1@1+ (1,0) [0|1] ""  unused_7,measure

BO_ 1604 msg_4269: 8 ecu_pri1_1
 SG_ signal4274 : 0|1@1+ (1,0) [0|1] ""  unused_7,measure
 SG_ signal4284 : 1|1@1+ (1,0) [0|1] ""  unused_7,measure
 SG_ signal3928 : 2|1@1+ (1,0) [0|1] ""  unused_7,measure
 SG_ signal3892 : 3|1@1+ (1,0) [0|1] ""  unused_7,measure
 SG_ signal4314 : 4|1@1+ (1,0) [0|1] ""  unused_2,measure
 SG_ signal4325 : 5|1@1+ (1,0) [0|1] ""  unused_7,measure
 SG_ signal4335 : 6|1@1+ (1,0) [0|1] ""  unused_7,measure
 SG_ signal4345 : 7|1@1+ (1,0) [0|1] ""  unused_7,measure
 SG_ signal4355 : 8|1@1+ (1,0) [0|1] ""  unused_7,measure
 SG_ signal4365 : 9|1@1+ (1,0) [0|1] ""  unused_7,measure
 SG_ signal4375 : 10|1@1+ (1,0) [0|1] ""  unused_7,measure
 SG_ signal4385 : 11|1@1+ (1,0) [0|1] ""  unused_7,measure
 SG_ signal4395 : 12|1@1+ (1,0) [0|1] ""  unused_7,measure
 SG_ signal4405 : 13|1@1+ (1,0) [0|1] ""  unused_7,measure
 SG_ signal4415 : 14|1@1+ (1,0) [0|1] ""  unused_7,measure
 SG_ signal4425 : 15|1@1+ (1,0) [0|1] ""  unused_7,measure
 SG_ signal4435 : 16|1@1+ (1,0) [0|1] ""  unused_7,measure
 SG_ signal4445 : 17|1@1+ (1,0) [0|1] ""  unused_7,measure
 SG_ signal4455 : 18|1@1+ (1,0) [0|1] ""  unused_7,measure
 SG_ signal4465 : 24|1@1+ (1,0) [0|1] ""  unused_7,measure
 SG_ signal4475 : 25|1@1+ (1,0) [0|1] ""  unused_7,measure
 SG_ signal4485 : 26|1@1+ (1,0) [0|1] ""  unused_7,measure
 SG_ signal4495 : 27|1@1+ (1,0) [0|1] ""  unused_7,measure
 SG_ signal4505 : 32|1@1+ (1,0) [0|1] ""  unused_2,measure

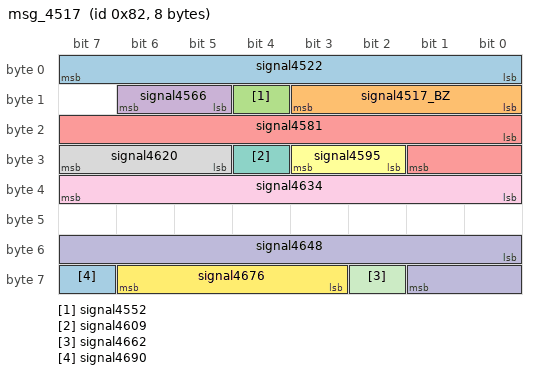
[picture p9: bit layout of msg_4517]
BO_ 130 msg_4517: 8 ecu_sec1_2
 SG_ signal4522 : 0|8@1+ (1,0) [0|255] ""  ecu_pri3_2,ecu_pri1_1,ecu_sec3_1,unused_1,unused_4,measure
 SG_ signal4517_BZ : 8|4@1+ (1,0) [0|15] ""  ecu_pri3_2,ecu_pri1_1,ecu_sec3_1,unused_1,unused_4,measure
 SG_ signal4552 : 12|1@1+ (1,0) [0|1] ""  ecu_pri1_1,ecu_sec3_1,unused_1,unused_4,measure
 SG_ signal4566 : 13|2@1+ (1,0) [0|3] ""  ecu_pri3_2,ecu_pri1_1,ecu_sec3_1,unused_1,unused_4,measure
 SG_ signal4581 : 16|10@1+ (1,0) [0|1021] ""  ecu_pri1_1,ecu_sec3_1,unused_1,unused_4,measure
 SG_ signal4595 : 26|2@1+ (1,0) [0|3] ""  ecu_pri1_1,ecu_sec3_1,unused_1,unused_4,measure
 SG_ signal4609 : 28|1@1+ (1,0) [0|1] ""  ecu_pri1_1,measure
 SG_ signal4620 : 29|3@1+ (1,0) [0|7] ""  ecu_pri1_1,ecu_sec3_1,unused_1,unused_4,measure
 SG_ signal4634 : 32|8@1+ (10,0) [0|2550] "ms"  ecu_pri1_1,ecu_sec3_1,unused_1,unused_4,measure
 SG_ signal4648 : 48|10@1+ (1,0) [0|1021] ""  ecu_pri1_1,ecu_sec3_1,unused_1,unused_4,measure
 SG_ signal4662 : 58|1@1+ (1,0) [0|1] ""  ecu_pri1_1,ecu_sec3_1,unused_1,unused_4,measure
 SG_ signal4676 : 59|4@1+ (1,0) [1|14] ""  ecu_pri1_1,ecu_sec3_1,unused_1,unused_4,measure
 SG_ signal4690 : 63|1@1+ (1,0) [0|1] ""  ecu_pri1_1,measure

BO_TX_BU_ 490 : ecu_sec1_2,unused_8,unused_2;
BO_TX_BU_ 488 : ecu_sec3_1,unused_1,unused_4;
BO_TX_BU_ 2616986625 : ecu_sec3_1,unused_1,unused_4;
BO_TX_BU_ 130 : ecu_sec1_2,unused_8,unused_2;

CM_ BO_ 3221225472 "This is a message for not used signals, created by Vector CANdb++ DBC OLE DB Provider.";
BA_DEF_  "GenNWMApBusSleep" STRING ;
BA_DEF_  "GenNWMApCanNormal" STRING ;
BA_DEF_  "GenNWMApCanOff" STRING ;
BA_DEF_  "GenNWMApCanOn" STRING ;
BA_DEF_  "GenNWMApCanSleep" STRING ;
BA_DEF_  "GenNWMApCanWakeUp" STRING ;
BA_DEF_  "signal14747" STRING ;
BA_DEF_  "signal14743" STRING ;
BA_DEF_  "GenNWMSleepTime" INT 0 1000000;
BA_DEF_  "GenNWMTalkNM" STRING ;
BA_DEF_  "Manufacturer" STRING ;
BA_DEF_  "NmBaseAddress" HEX 0 2047;
BA_DEF_  "NWM-BasisAdresse" HEX 0 2047;
BA_DEF_  "NmMessageCount" INT 1 255;
BA_DEF_  "NWMMessageCount" INT 1 64;
BA_DEF_  "NmType" STRING ;
BA_DEF_  "NWM-Typ" ENUM  "VAG-OSEK","None";
BA_DEF_  "signal14703" INT 0 255;
BA_DEF_  "signal14699" HEX 0 2047;
BA_DEF_  "VersionDay" INT 1 31;
BA_DEF_  "VersionMonth" INT 1 12;
BA_DEF_  "VersionNumber" INT -2147483648 2147483647;
BA_DEF_  "VersionWeek" INT 1 52;
BA_DEF_  "VersionYear" INT 0 99;
BA_DEF_  "NmhBaseAddress" INT 0 0;
BA_DEF_  "NmhMessageCount" INT 0 0;
BA_DEF_ BU_  "GenNodAutoGenDsp" ENUM  "No","Yes";
BA_DEF_ BU_  "GenNodAutoGenSnd" ENUM  "No","Yes";
BA_DEF_ BU_  "GenNodSleepTime" INT 0 1000000;
BA_DEF_ BU_  "ILUsed" ENUM  "No","Yes";
BA_DEF_ BU_  "NmCAN" INT 1 2;
BA_DEF_ BU_  "NmNode" ENUM  "No","Yes";
BA_DEF_ BU_  "NWM-Knoten" ENUM  "No","Yes";
BA_DEF_ BU_  "NodeLayerModules" STRING ;
BA_DEF_ BU_  "signal15687" HEX 0 127;
BA_DEF_ BU_  "Fehlerort" HEX 0 1000000;
BA_DEF_ BU_  "NmhStationAddress" HEX 0 0;
BA_DEF_ BU_  "NmhNode" ENUM  "No","Yes";
BA_DEF_ BO_  "GenMsgAutoGenDsp" ENUM  "No","Yes";
BA_DEF_ BO_  "GenMsgAutoGenSnd" ENUM  "No","Yes";
BA_DEF_ BO_  "GenMsgCycleTime" INT 0 65535;
BA_DEF_ BO_  "GenMsgCycleTimeFast" INT 0 65535;
BA_DEF_ BO_  "GenMsgDelayTime" INT 0 100000;
BA_DEF_ BO_  "GenMsgILSupport" ENUM  "No","Yes";
BA_DEF_ BO_  "GenMsgNrOfRepetition" INT 0 100;
BA_DEF_ BO_  "GenMsgSendType" ENUM  "cyclicX","spontanX","cyclicIfActiveX","spontanWithDelay","cyclicAndSpontanX","cyclicAndSpontanWithDelay","spontanWithRepetition","cyclicIfActiveAndSpontanWD","cyclicIfActiveFast","cyclicWithRepeatOnDemand";
BA_DEF_ BO_  "GenMsgStartDelayTime" INT 0 100000;
BA_DEF_ BO_  "NmMessage" ENUM  "No","Yes";
BA_DEF_ BO_  "NmhMessage" ENUM  "No","Yes";
BA_DEF_ BO_  "NWM-Botschaft" ENUM  "No","Yes";
BA_DEF_ BO_  "signal24915" HEX 0 255;
BA_DEF_ BO_  "signal24909" ENUM  "No","Yes";
BA_DEF_ BO_  "signal24903" ENUM  "No","Yes";
BA_DEF_ BO_  "signal24897" ENUM  "No","Yes";
BA_DEF_ BO_  "Timeoutzeit" INT 0 1000000;
BA_DEF_ BO_  "signal24891" ENUM  "No","Yes";
BA_DEF_ SG_  "GenSigAltSetting" STRING ;
BA_DEF_ SG_  "GenSigAssignSetting" STRING ;
BA_DEF_ SG_  "GenSigAutoGenDsp" ENUM  "No","Yes";
BA_DEF_ SG_  "GenSigAutoGenSnd" ENUM  "No","Yes";
BA_DEF_ SG_  "GenSigConditionalSend" STRING ;
BA_DEF_ SG_  "GenSigEnvVarType" ENUM  "int","float","undef";
BA_DEF_ SG_  "GenSigEVName" STRING ;
BA_DEF_ SG_  "GenSigInactiveValue" INT -2147483648 2147483647;
BA_DEF_ SG_  "GenSigPostIfSetting" STRING ;
BA_DEF_ SG_  "GenSigPostSetting" STRING ;
BA_DEF_ SG_  "GenSigPreIfSetting" STRING ;
BA_DEF_ SG_  "GenSigPreSetting" STRING ;
BA_DEF_ SG_  "GenSigSendType" ENUM  "Cyclic","OnWrite","OnWriteWithRepetition","OnChange","OnChangeWithRepetition","IfActive","IfActiveWithRepetition","NoSigSendType";
BA_DEF_ SG_  "GenSigStartValue" INT -2147483648 2147483647;
BA_DEF_ SG_  "NWM-WakeupAllowed" ENUM  "No","Yes";
BA_DEF_ SG_  "NMH-WakeupAllowed" ENUM  "No","Yes";
BA_DEF_ SG_  "GenSigTimeoutMsg_ecu12594" HEX 0 2047;
BA_DEF_ SG_  "GenSigTimeoutMsg_ecu13120" HEX 0 2047;
BA_DEF_ SG_  "signal133356" HEX 0 2047;
BA_DEF_ SG_  "signal136198" HEX 0 2047;
BA_DEF_ SG_  "signal131977" HEX 0 2047;
BA_DEF_ SG_  "signal131970" HEX 0 2047;
BA_DEF_ SG_  "GenSigTimeoutMsg_ecu11765" HEX 0 2047;
BA_DEF_ SG_  "GenSigTimeoutMsg_ecu13186" HEX 0 2047;
BA_DEF_ SG_  "GenSigTimeoutMsg_ecu12990" HEX 0 2047;
BA_DEF_ SG_  "GenSigTimeoutMsg_ecu8948" HEX 0 2047;
BA_DEF_ SG_  "signal142820" HEX 0 2047;
BA_DEF_ SG_  "signal142834" HEX 0 2047;
BA_DEF_ SG_  "signal142827" HEX 0 2047;
BA_DEF_ SG_  "GenSigTimeoutMsg_ecu5385" HEX 0 2047;
BA_DEF_ SG_  "GenSigTimeoutMsg_ecu9211" HEX 0 2047;
BA_DEF_ SG_  "GenSigTimeoutMsg_ecu11949" HEX 0 2047;
BA_DEF_DEF_  "GenNWMApBusSleep" "NMIndNetSDN()";
BA_DEF_DEF_  "GenNWMApCanNormal" "";
BA_DEF_DEF_  "GenNWMApCanOff" "NMIndNetOff()";
BA_DEF_DEF_  "GenNWMApCanOn" "NMIndNetOn()";
BA_DEF_DEF_  "GenNWMApCanSleep" "";
BA_DEF_DEF_  "GenNWMApCanWakeUp" "";
BA_DEF_DEF_  "signal14747" "signal14228";
BA_DEF_DEF_  "signal14743" "signal14218";
BA_DEF_DEF_  "GenNWMSleepTime" 0;
BA_DEF_DEF_  "GenNWMTalkNM" "signal14228";
BA_DEF_DEF_  "Manufacturer" "";
BA_DEF_DEF_  "NmBaseAddress" 0;
BA_DEF_DEF_  "NWM-BasisAdresse" 0;
BA_DEF_DEF_  "NmMessageCount" 64;
BA_DEF_DEF_  "NWMMessageCount" 64;
BA_DEF_DEF_  "NmType" "VAG-OSEK";
BA_DEF_DEF_  "NWM-Typ" "VAG-OSEK";
BA_DEF_DEF_  "signal14703" 128;
BA_DEF_DEF_  "signal14699" 0;
BA_DEF_DEF_  "VersionDay" 12;
BA_DEF_DEF_  "VersionMonth" 1;
BA_DEF_DEF_  "VersionNumber" 0;
BA_DEF_DEF_  "VersionWeek" 2;
BA_DEF_DEF_  "VersionYear" 7;
BA_DEF_DEF_  "NmhBaseAddress" 0;
BA_DEF_DEF_  "NmhMessageCount" 0;
BA_DEF_DEF_  "GenNodAutoGenDsp" "Yes";
BA_DEF_DEF_  "GenNodAutoGenSnd" "Yes";
BA_DEF_DEF_  "GenNodSleepTime" 0;
BA_DEF_DEF_  "ILUsed" "";
BA_DEF_DEF_  "NmCAN" 1;
BA_DEF_DEF_  "NmNode" "No";
BA_DEF_DEF_  "NWM-Knoten" "No";
BA_DEF_DEF_  "NodeLayerModules" "";
BA_DEF_DEF_  "signal15687" 0;
BA_DEF_DEF_  "Fehlerort" 0;
BA_DEF_DEF_  "NmhStationAddress" 0;
BA_DEF_DEF_  "NmhNode" "Yes";
BA_DEF_DEF_  "GenMsgAutoGenDsp" "Yes";
BA_DEF_DEF_  "GenMsgAutoGenSnd" "Yes";
BA_DEF_DEF_  "GenMsgCycleTime" 0;
BA_DEF_DEF_  "GenMsgCycleTimeFast" 0;
BA_DEF_DEF_  "GenMsgDelayTime" 0;
BA_DEF_DEF_  "GenMsgILSupport" "";
BA_DEF_DEF_  "GenMsgNrOfRepetition" 0;
BA_DEF_DEF_  "GenMsgSendType" "cyclicX";
BA_DEF_DEF_  "GenMsgStartDelayTime" 0;
BA_DEF_DEF_  "NmMessage" "No";
BA_DEF_DEF_  "NmhMessage" "No";
BA_DEF_DEF_  "NWM-Botschaft" "No";
BA_DEF_DEF_  "signal24915" 0;
BA_DEF_DEF_  "signal24909" "No";
BA_DEF_DEF_  "signal24903" "No";
BA_DEF_DEF_  "signal24897" "No";
BA_DEF_DEF_  "Timeoutzeit" 0;
BA_DEF_DEF_  "signal24891" "";
BA_DEF_DEF_  "GenSigAltSetting" "";
BA_DEF_DEF_  "GenSigAssignSetting" "";
BA_DEF_DEF_  "GenSigAutoGenDsp" "";
BA_DEF_DEF_  "GenSigAutoGenSnd" "";
BA_DEF_DEF_  "GenSigConditionalSend" "";
BA_DEF_DEF_  "GenSigEnvVarType" "undef";
BA_DEF_DEF_  "GenSigEVName" "";
BA_DEF_DEF_  "GenSigInactiveValue" 0;
BA_DEF_DEF_  "GenSigPostIfSetting" "";
BA_DEF_DEF_  "GenSigPostSetting" "";
BA_DEF_DEF_  "GenSigPreIfSetting" "";
BA_DEF_DEF_  "GenSigPreSetting" "";
BA_DEF_DEF_  "GenSigSendType" "Cyclic";
BA_DEF_DEF_  "GenSigStartValue" 0;
BA_DEF_DEF_  "NWM-WakeupAllowed" "";
BA_DEF_DEF_  "NMH-WakeupAllowed" "";
BA_DEF_DEF_  "GenSigTimeoutMsg_ecu12594" 0;
BA_DEF_DEF_  "GenSigTimeoutMsg_ecu13120" 0;
BA_DEF_DEF_  "signal133356" 0;
BA_DEF_DEF_  "signal136198" 0;
BA_DEF_DEF_  "signal131977" 0;
BA_DEF_DEF_  "signal131970" 0;
BA_DEF_DEF_  "GenSigTimeoutMsg_ecu11765" 0;
BA_DEF_DEF_  "GenSigTimeoutMsg_ecu13186" 0;
BA_DEF_DEF_  "GenSigTimeoutMsg_ecu12990" 0;
BA_DEF_DEF_  "GenSigTimeoutMsg_ecu8948" 0;
BA_DEF_DEF_  "signal142820" 0;
BA_DEF_DEF_  "signal142834" 0;
BA_DEF_DEF_  "signal142827" 0;
BA_DEF_DEF_  "GenSigTimeoutMsg_ecu5385" 0;
BA_DEF_DEF_  "GenSigTimeoutMsg_ecu9211" 0;
BA_DEF_DEF_  "GenSigTimeoutMsg_ecu11949" 0;
BA_ "NmhBaseAddress" 30;
BA_ "signal14699" 512;
BA_ "NWM-BasisAdresse" 1024;
BA_ "NmBaseAddress" 1024;
BA_ "Manufacturer" "VAG";
BA_ "GenNWMTalkNM" "talkNM()";
BA_ "GenNWMSleepTime" 30;
BA_ "signal14743" "signal14744";
BA_ "signal14747" "signal14748";
BA_ "GenNWMApCanWakeUp" "apCanWakeUp()";
BA_ "GenNWMApCanSleep" "apCanSleep()";
BA_ "GenNWMApCanOn" "apCanOn()";
BA_ "GenNWMApCanOff" "apCanOff()";
BA_ "GenNWMApCanNormal" "apCanNormal()";
BA_ "GenNWMApBusSleep" "apBusSleep()";
BA_ "NmhNode" BU_ ecu_pri3_1 0;
BA_ "Fehlerort" BU_ ecu_pri3_1 1321;
BA_ "ILUsed" BU_ ecu_pri3_1 0;
BA_ "NmhStationAddress" BU_ ecu_pri3_2 25;
BA_ "Fehlerort" BU_ ecu_pri3_2 473;
BA_ "signal15687" BU_ ecu_pri3_2 25;
BA_ "NodeLayerModules" BU_ ecu_pri3_2 "NMHigh.DLL";
BA_ "ILUsed" BU_ ecu_pri3_2 0;
BA_ "GenNodSleepTime" BU_ ecu_pri3_2 30000;
BA_ "NmhStationAddress" BU_ ecu_sec1_1 3;
BA_ "Fehlerort" BU_ ecu_sec1_1 1316;
BA_ "NodeLayerModules" BU_ ecu_sec1_1 "VAGNM01.DLL";
BA_ "ILUsed" BU_ ecu_sec1_1 0;
BA_ "GenNodSleepTime" BU_ ecu_sec1_1 30000;
BA_ "Fehlerort" BU_ ecu_pri1_1 1299;
BA_ "signal15687" BU_ ecu_pri1_1 31;
BA_ "NodeLayerModules" BU_ ecu_pri1_1 "NMHigh.DLL";
BA_ "ILUsed" BU_ ecu_pri1_1 0;
BA_ "GenNodSleepTime" BU_ ecu_pri1_1 30000;
BA_ "NmhStationAddress" BU_ ecu_sec1_2 2;
BA_ "Fehlerort" BU_ ecu_sec1_2 1315;
BA_ "NodeLayerModules" BU_ ecu_sec1_2 "NMHigh.DLL";
BA_ "ILUsed" BU_ ecu_sec1_2 0;
BA_ "GenNodSleepTime" BU_ ecu_sec1_2 30000;
BA_ "NmhStationAddress" BU_ unused_8 2;
BA_ "Fehlerort" BU_ unused_8 1315;
BA_ "NodeLayerModules" BU_ unused_8 "NMHigh.DLL";
BA_ "ILUsed" BU_ unused_8 0;
BA_ "GenNodSleepTime" BU_ unused_8 30000;
BA_ "NmhStationAddress" BU_ unused_2 2;
BA_ "Fehlerort" BU_ unused_2 1315;
BA_ "NodeLayerModules" BU_ unused_2 "NMHigh.DLL";
BA_ "ILUsed" BU_ unused_2 0;
BA_ "GenNodSleepTime" BU_ unused_2 30000;
BA_ "NmhNode" BU_ ecu_sec3_2 0;
BA_ "Fehlerort" BU_ ecu_sec3_2 778;
BA_ "ILUsed" BU_ ecu_sec3_2 0;
BA_ "GenNodSleepTime" BU_ ecu_sec3_2 30000;
BA_ "NmhStationAddress" BU_ ecu_sec3_1 1;
BA_ "Fehlerort" BU_ ecu_sec3_1 1314;
BA_ "NodeLayerModules" BU_ ecu_sec3_1 "NMHigh.DLL";
BA_ "ILUsed" BU_ ecu_sec3_1 0;
BA_ "GenNodSleepTime" BU_ ecu_sec3_1 30000;
BA_ "NmhStationAddress" BU_ unused_1 1;
BA_ "Fehlerort" BU_ unused_1 1314;
BA_ "NodeLayerModules" BU_ unused_1 "NMHigh.DLL";
BA_ "ILUsed" BU_ unused_1 0;
BA_ "GenNodSleepTime" BU_ unused_1 30000;
BA_ "NmhStationAddress" BU_ unused_4 1;
BA_ "Fehlerort" BU_ unused_4 1314;
BA_ "NodeLayerModules" BU_ unused_4 "NMHigh.DLL";
BA_ "ILUsed" BU_ unused_4 0;
BA_ "GenNodSleepTime" BU_ unused_4 30000;
BA_ "NmhNode" BU_ unused_9 0;
BA_ "Fehlerort" BU_ unused_9 1342;
BA_ "ILUsed" BU_ unused_9 0;
BA_ "GenNodSleepTime" BU_ unused_9 30000;
BA_ "NmhNode" BU_ unused_3 0;
BA_ "NodeLayerModules" BU_ unused_3 "VAGNM01.DLL";
BA_ "ILUsed" BU_ unused_3 0;
BA_ "GenNodSleepTime" BU_ unused_3 30000;
BA_ "NmhNode" BU_ ecu_pri3_3 0;
BA_ "Fehlerort" BU_ ecu_pri3_3 3110;
BA_ "signal15687" BU_ ecu_pri3_3 30;
BA_ "ILUsed" BU_ ecu_pri3_3 0;
BA_ "GenNodSleepTime" BU_ ecu_pri3_3 30000;
BA_ "NmhStationAddress" BU_ unused_6 16;
BA_ "Fehlerort" BU_ unused_6 1207;
BA_ "signal15687" BU_ unused_6 47;
BA_ "NodeLayerModules" BU_ unused_6 "NMHigh.DLL";
BA_ "ILUsed" BU_ unused_6 0;
BA_ "GenNodSleepTime" BU_ unused_6 30000;
BA_ "NmhNode" BU_ unused_5 0;
BA_ "NodeLayerModules" BU_ unused_5 "VAGNM01.DLL";
BA_ "ILUsed" BU_ unused_5 0;
BA_ "GenNodSleepTime" BU_ unused_5 30000;
BA_ "signal24891" BO_ 64 0;
BA_ "GenMsgSendType" BO_ 64 5;
BA_ "GenMsgILSupport" BO_ 64 1;
BA_ "GenMsgDelayTime" BO_ 64 10;
BA_ "GenMsgCycleTime" BO_ 64 50;
BA_ "signal24891" BO_ 1312 0;
BA_ "GenMsgILSupport" BO_ 1312 1;
BA_ "GenMsgCycleTime" BO_ 1312 200;
BA_ "signal24891" BO_ 1633 1;
BA_ "GenMsgILSupport" BO_ 1633 1;
BA_ "GenMsgCycleTime" BO_ 1633 100;
BA_ "signal24891" BO_ 777 1;
BA_ "GenMsgILSupport" BO_ 777 1;
BA_ "GenMsgCycleTime" BO_ 777 50;
BA_ "signal24891" BO_ 1635 1;
BA_ "GenMsgILSupport" BO_ 1635 1;
BA_ "GenMsgDelayTime" BO_ 1635 50;
BA_ "GenMsgCycleTime" BO_ 1635 100;
BA_ "signal24891" BO_ 482 1;
BA_ "GenMsgSendType" BO_ 482 7;
BA_ "GenMsgILSupport" BO_ 482 0;
BA_ "signal24891" BO_ 490 1;
BA_ "GenMsgSendType" BO_ 490 7;
BA_ "GenMsgILSupport" BO_ 490 0;
BA_ "signal24891" BO_ 480 1;
BA_ "GenMsgSendType" BO_ 480 7;
BA_ "GenMsgILSupport" BO_ 480 0;
BA_ "signal24891" BO_ 2616986624 1;
BA_ "GenMsgSendType" BO_ 2616986624 7;
BA_ "GenMsgILSupport" BO_ 2616986624 0;
BA_ "signal24891" BO_ 488 1;
BA_ "GenMsgSendType" BO_ 488 7;
BA_ "GenMsgILSupport" BO_ 488 0;
BA_ "signal24891" BO_ 2616986625 1;
BA_ "GenMsgSendType" BO_ 2616986625 7;
BA_ "GenMsgILSupport" BO_ 2616986625 0;
BA_ "signal24891" BO_ 481 1;
BA_ "GenMsgSendType" BO_ 481 7;
BA_ "GenMsgILSupport" BO_ 481 0;
BA_ "signal24891" BO_ 2616986629 1;
BA_ "GenMsgSendType" BO_ 2616986629 7;
BA_ "GenMsgILSupport" BO_ 2616986629 0;
BA_ "signal24891" BO_ 489 1;
BA_ "GenMsgSendType" BO_ 489 7;
BA_ "GenMsgILSupport" BO_ 489 0;
BA_ "signal24891" BO_ 2616986630 1;
BA_ "GenMsgSendType" BO_ 2616986630 7;
BA_ "GenMsgILSupport" BO_ 2616986630 0;
BA_ "signal24891" BO_ 901 1;
BA_ "GenMsgSendType" BO_ 901 2;
BA_ "GenMsgNrOfRepetition" BO_ 901 5;
BA_ "GenMsgILSupport" BO_ 901 1;
BA_ "GenMsgCycleTime" BO_ 901 100;
BA_ "signal24891" BO_ 1714 1;
BA_ "GenMsgILSupport" BO_ 1714 1;
BA_ "GenMsgCycleTime" BO_ 1714 1000;
BA_ "signal24891" BO_ 1520 1;
BA_ "GenMsgILSupport" BO_ 1520 1;
BA_ "GenMsgDelayTime" BO_ 1520 50;
BA_ "GenMsgCycleTime" BO_ 1520 200;
BA_ "signal24891" BO_ 260 1;
BA_ "GenMsgILSupport" BO_ 260 1;
BA_ "GenMsgCycleTime" BO_ 260 20;
BA_ "signal24891" BO_ 781 1;
BA_ "GenMsgSendType" BO_ 781 5;
BA_ "GenMsgILSupport" BO_ 781 1;
BA_ "GenMsgCycleTime" BO_ 781 50;
BA_ "signal24891" BO_ 256 1;
BA_ "GenMsgILSupport" BO_ 256 1;
BA_ "GenMsgCycleTime" BO_ 256 20;
BA_ "signal24891" BO_ 257 1;
BA_ "GenMsgILSupport" BO_ 257 1;
BA_ "GenMsgCycleTime" BO_ 257 20;
BA_ "signal24891" BO_ 259 1;
BA_ "GenMsgILSupport" BO_ 259 1;
BA_ "GenMsgCycleTime" BO_ 259 20;
BA_ "signal24891" BO_ 776 1;
BA_ "GenMsgILSupport" BO_ 776 1;
BA_ "GenMsgCycleTime" BO_ 776 50;
BA_ "signal24891" BO_ 262 1;
BA_ "GenMsgILSupport" BO_ 262 1;
BA_ "GenMsgCycleTime" BO_ 262 20;
BA_ "signal24891" BO_ 132 1;
BA_ "GenMsgILSupport" BO_ 132 1;
BA_ "GenMsgCycleTime" BO_ 132 10;
BA_ "signal24891" BO_ 914 1;
BA_ "GenMsgILSupport" BO_ 914 1;
BA_ "GenMsgCycleTime" BO_ 914 80;
BA_ "signal24891" BO_ 924 1;
BA_ "GenMsgILSupport" BO_ 924 1;
BA_ "GenMsgCycleTime" BO_ 924 100;
BA_ "signal24891" BO_ 1604 1;
BA_ "GenMsgSendType" BO_ 1604 5;
BA_ "GenMsgILSupport" BO_ 1604 1;
BA_ "GenMsgCycleTime" BO_ 1604 500;
BA_ "signal24891" BO_ 130 1;
BA_ "GenMsgILSupport" BO_ 130 1;
BA_ "GenMsgCycleTime" BO_ 130 10;
BA_ "GenSigTimeoutMsg_ecu13186" SG_ 3221225472 signal5166 1919;
BA_ "NMH-WakeupAllowed" SG_ 3221225472 signal5166 0;
BA_ "NWM-WakeupAllowed" SG_ 3221225472 signal5166 0;
BA_ "GenSigSendType" SG_ 3221225472 signal5166 7;
BA_ "GenSigEnvVarType" SG_ 3221225472 signal5166 0;
BA_ "GenSigAutoGenSnd" SG_ 3221225472 signal5166 0;
BA_ "GenSigAutoGenDsp" SG_ 3221225472 signal5166 0;
BA_ "GenSigTimeoutMsg_ecu12594" SG_ 3221225472 signal12359 1309;
BA_ "NMH-WakeupAllowed" SG_ 3221225472 signal12359 0;
BA_ "NWM-WakeupAllowed" SG_ 3221225472 signal12359 0;
BA_ "GenSigSendType" SG_ 3221225472 signal12359 7;
BA_ "GenSigEnvVarType" SG_ 3221225472 signal12359 0;
BA_ "GenSigAutoGenSnd" SG_ 3221225472 signal12359 0;
BA_ "GenSigAutoGenDsp" SG_ 3221225472 signal12359 0;
BA_ "GenSigTimeoutMsg_ecu12990" SG_ 3221225472 signal12444 1307;
BA_ "NMH-WakeupAllowed" SG_ 3221225472 signal12444 0;
BA_ "NWM-WakeupAllowed" SG_ 3221225472 signal12444 0;
BA_ "GenSigSendType" SG_ 3221225472 signal12444 7;
BA_ "GenSigEnvVarType" SG_ 3221225472 signal12444 0;
BA_ "GenSigAutoGenSnd" SG_ 3221225472 signal12444 0;
BA_ "GenSigAutoGenDsp" SG_ 3221225472 signal12444 0;
BA_ "signal136198" SG_ 64 signal1032 64;
BA_ "signal133356" SG_ 64 signal1032 64;
BA_ "GenSigTimeoutMsg_ecu13120" SG_ 64 signal1032 64;
BA_ "GenSigTimeoutMsg_ecu13186" SG_ 64 signal1032 64;
BA_ "GenSigTimeoutMsg_ecu12594" SG_ 64 signal1032 64;
BA_ "NMH-WakeupAllowed" SG_ 64 signal1032 0;
BA_ "NWM-WakeupAllowed" SG_ 64 signal1032 0;
BA_ "GenSigSendType" SG_ 64 signal1032 7;
BA_ "GenSigEnvVarType" SG_ 64 signal1032 0;
BA_ "GenSigAutoGenSnd" SG_ 64 signal1032 1;
BA_ "GenSigAutoGenDsp" SG_ 64 signal1032 1;
BA_ "signal136198" SG_ 64 signal1027_BZ 64;
BA_ "signal133356" SG_ 64 signal1027_BZ 64;
BA_ "GenSigTimeoutMsg_ecu13120" SG_ 64 signal1027_BZ 64;
BA_ "GenSigTimeoutMsg_ecu13186" SG_ 64 signal1027_BZ 64;
BA_ "GenSigTimeoutMsg_ecu12594" SG_ 64 signal1027_BZ 64;
BA_ "NMH-WakeupAllowed" SG_ 64 signal1027_BZ 0;
BA_ "NWM-WakeupAllowed" SG_ 64 signal1027_BZ 0;
BA_ "GenSigSendType" SG_ 64 signal1027_BZ 7;
BA_ "GenSigEnvVarType" SG_ 64 signal1027_BZ 0;
BA_ "GenSigAutoGenSnd" SG_ 64 signal1027_BZ 1;
BA_ "GenSigAutoGenDsp" SG_ 64 signal1027_BZ 1;
BA_ "GenSigTimeoutMsg_ecu13186" SG_ 64 signal1062 64;
BA_ "NMH-WakeupAllowed" SG_ 64 signal1062 0;
BA_ "NWM-WakeupAllowed" SG_ 64 signal1062 0;
BA_ "GenSigSendType" SG_ 64 signal1062 7;
BA_ "GenSigEnvVarType" SG_ 64 signal1062 0;
BA_ "GenSigAutoGenSnd" SG_ 64 signal1062 1;
BA_ "GenSigAutoGenDsp" SG_ 64 signal1062 1;
BA_ "GenSigTimeoutMsg_ecu13186" SG_ 64 signal1073 64;
BA_ "NMH-WakeupAllowed" SG_ 64 signal1073 0;
BA_ "NWM-WakeupAllowed" SG_ 64 signal1073 0;
BA_ "GenSigSendType" SG_ 64 signal1073 7;
BA_ "GenSigEnvVarType" SG_ 64 signal1073 0;
BA_ "GenSigAutoGenSnd" SG_ 64 signal1073 1;
BA_ "GenSigAutoGenDsp" SG_ 64 signal1073 1;
BA_ "GenSigTimeoutMsg_ecu13186" SG_ 64 signal1084 64;
BA_ "NMH-WakeupAllowed" SG_ 64 signal1084 0;
BA_ "NWM-WakeupAllowed" SG_ 64 signal1084 0;
BA_ "GenSigSendType" SG_ 64 signal1084 7;
BA_ "GenSigEnvVarType" SG_ 64 signal1084 0;
BA_ "GenSigAutoGenSnd" SG_ 64 signal1084 1;
BA_ "GenSigAutoGenDsp" SG_ 64 signal1084 1;
BA_ "GenSigTimeoutMsg_ecu13186" SG_ 64 signal1095 64;
BA_ "NMH-WakeupAllowed" SG_ 64 signal1095 0;
BA_ "NWM-WakeupAllowed" SG_ 64 signal1095 0;
BA_ "GenSigSendType" SG_ 64 signal1095 7;
BA_ "GenSigEnvVarType" SG_ 64 signal1095 0;
BA_ "GenSigAutoGenSnd" SG_ 64 signal1095 1;
BA_ "GenSigAutoGenDsp" SG_ 64 signal1095 1;
BA_ "GenSigTimeoutMsg_ecu13186" SG_ 64 signal1106 64;
BA_ "NMH-WakeupAllowed" SG_ 64 signal1106 0;
BA_ "NWM-WakeupAllowed" SG_ 64 signal1106 0;
BA_ "GenSigSendType" SG_ 64 signal1106 7;
BA_ "GenSigEnvVarType" SG_ 64 signal1106 0;
BA_ "GenSigAutoGenSnd" SG_ 64 signal1106 1;
BA_ "GenSigAutoGenDsp" SG_ 64 signal1106 1;
BA_ "GenSigTimeoutMsg_ecu12990" SG_ 64 signal1117 64;
BA_ "signal136198" SG_ 64 signal1117 64;
BA_ "signal133356" SG_ 64 signal1117 64;
BA_ "GenSigTimeoutMsg_ecu13120" SG_ 64 signal1117 64;
BA_ "GenSigTimeoutMsg_ecu13186" SG_ 64 signal1117 64;
BA_ "NMH-WakeupAllowed" SG_ 64 signal1117 0;
BA_ "NWM-WakeupAllowed" SG_ 64 signal1117 0;
BA_ "GenSigSendType" SG_ 64 signal1117 7;
BA_ "GenSigEnvVarType" SG_ 64 signal1117 0;
BA_ "GenSigAutoGenSnd" SG_ 64 signal1117 1;
BA_ "GenSigAutoGenDsp" SG_ 64 signal1117 1;
BA_ "GenSigTimeoutMsg_ecu13186" SG_ 64 signal1132 64;
BA_ "NMH-WakeupAllowed" SG_ 64 signal1132 0;
BA_ "NWM-WakeupAllowed" SG_ 64 signal1132 0;
BA_ "GenSigStartValue" SG_ 64 signal1132 1;
BA_ "GenSigSendType" SG_ 64 signal1132 7;
BA_ "GenSigEnvVarType" SG_ 64 signal1132 0;
BA_ "GenSigAutoGenSnd" SG_ 64 signal1132 1;
BA_ "GenSigAutoGenDsp" SG_ 64 signal1132 1;
BA_ "GenSigTimeoutMsg_ecu13186" SG_ 64 signal1143 64;
BA_ "NMH-WakeupAllowed" SG_ 64 signal1143 0;
BA_ "NWM-WakeupAllowed" SG_ 64 signal1143 0;
BA_ "GenSigSendType" SG_ 64 signal1143 7;
BA_ "GenSigEnvVarType" SG_ 64 signal1143 0;
BA_ "GenSigAutoGenSnd" SG_ 64 signal1143 1;
BA_ "GenSigAutoGenDsp" SG_ 64 signal1143 1;
BA_ "GenSigTimeoutMsg_ecu13186" SG_ 64 signal1154 64;
BA_ "NMH-WakeupAllowed" SG_ 64 signal1154 0;
BA_ "NWM-WakeupAllowed" SG_ 64 signal1154 0;
BA_ "GenSigStartValue" SG_ 64 signal1154 1;
BA_ "GenSigSendType" SG_ 64 signal1154 7;
BA_ "GenSigEnvVarType" SG_ 64 signal1154 0;
BA_ "GenSigAutoGenSnd" SG_ 64 signal1154 1;
BA_ "GenSigAutoGenDsp" SG_ 64 signal1154 1;
BA_ "GenSigTimeoutMsg_ecu13186" SG_ 64 signal1165 64;
BA_ "NMH-WakeupAllowed" SG_ 64 signal1165 0;
BA_ "NWM-WakeupAllowed" SG_ 64 signal1165 0;
BA_ "GenSigSendType" SG_ 64 signal1165 7;
BA_ "GenSigEnvVarType" SG_ 64 signal1165 0;
BA_ "GenSigAutoGenSnd" SG_ 64 signal1165 1;
BA_ "GenSigAutoGenDsp" SG_ 64 signal1165 1;
BA_ "GenSigTimeoutMsg_ecu13186" SG_ 64 signal1176 64;
BA_ "NMH-WakeupAllowed" SG_ 64 signal1176 0;
BA_ "NWM-WakeupAllowed" SG_ 64 signal1176 0;
BA_ "GenSigSendType" SG_ 64 signal1176 7;
BA_ "GenSigEnvVarType" SG_ 64 signal1176 0;
BA_ "GenSigAutoGenSnd" SG_ 64 signal1176 1;
BA_ "GenSigAutoGenDsp" SG_ 64 signal1176 1;
BA_ "GenSigTimeoutMsg_ecu12990" SG_ 64 signal1187 64;
BA_ "signal136198" SG_ 64 signal1187 64;
BA_ "signal133356" SG_ 64 signal1187 64;
BA_ "GenSigTimeoutMsg_ecu13120" SG_ 64 signal1187 64;
BA_ "GenSigTimeoutMsg_ecu13186" SG_ 64 signal1187 64;
BA_ "NMH-WakeupAllowed" SG_ 64 signal1187 0;
BA_ "NWM-WakeupAllowed" SG_ 64 signal1187 0;
BA_ "GenSigSendType" SG_ 64 signal1187 7;
BA_ "GenSigEnvVarType" SG_ 64 signal1187 0;
BA_ "GenSigAutoGenSnd" SG_ 64 signal1187 1;
BA_ "GenSigAutoGenDsp" SG_ 64 signal1187 1;
BA_ "GenSigTimeoutMsg_ecu13186" SG_ 64 signal1202 64;
BA_ "NMH-WakeupAllowed" SG_ 64 signal1202 0;
BA_ "NWM-WakeupAllowed" SG_ 64 signal1202 0;
BA_ "GenSigSendType" SG_ 64 signal1202 7;
BA_ "GenSigEnvVarType" SG_ 64 signal1202 0;
BA_ "GenSigAutoGenSnd" SG_ 64 signal1202 1;
BA_ "GenSigAutoGenDsp" SG_ 64 signal1202 1;
BA_ "GenSigTimeoutMsg_ecu13186" SG_ 64 signal1213 64;
BA_ "GenSigTimeoutMsg_ecu12594" SG_ 64 signal1213 64;
BA_ "NMH-WakeupAllowed" SG_ 64 signal1213 0;
BA_ "NWM-WakeupAllowed" SG_ 64 signal1213 0;
BA_ "GenSigSendType" SG_ 64 signal1213 7;
BA_ "GenSigEnvVarType" SG_ 64 signal1213 0;
BA_ "GenSigAutoGenSnd" SG_ 64 signal1213 1;
BA_ "GenSigAutoGenDsp" SG_ 64 signal1213 1;
BA_ "GenSigTimeoutMsg_ecu13186" SG_ 64 signal1225 64;
BA_ "NMH-WakeupAllowed" SG_ 64 signal1225 0;
BA_ "NWM-WakeupAllowed" SG_ 64 signal1225 0;
BA_ "GenSigSendType" SG_ 64 signal1225 7;
BA_ "GenSigEnvVarType" SG_ 64 signal1225 0;
BA_ "GenSigAutoGenSnd" SG_ 64 signal1225 1;
BA_ "GenSigAutoGenDsp" SG_ 64 signal1225 1;
BA_ "GenSigTimeoutMsg_ecu13186" SG_ 64 signal1236 64;
BA_ "NMH-WakeupAllowed" SG_ 64 signal1236 0;
BA_ "NWM-WakeupAllowed" SG_ 64 signal1236 0;
BA_ "GenSigSendType" SG_ 64 signal1236 7;
BA_ "GenSigEnvVarType" SG_ 64 signal1236 0;
BA_ "GenSigAutoGenSnd" SG_ 64 signal1236 1;
BA_ "GenSigAutoGenDsp" SG_ 64 signal1236 1;
BA_ "GenSigTimeoutMsg_ecu13186" SG_ 64 signal1247 64;
BA_ "NMH-WakeupAllowed" SG_ 64 signal1247 0;
BA_ "NWM-WakeupAllowed" SG_ 64 signal1247 0;
BA_ "GenSigSendType" SG_ 64 signal1247 7;
BA_ "GenSigEnvVarType" SG_ 64 signal1247 0;
BA_ "GenSigAutoGenSnd" SG_ 64 signal1247 1;
BA_ "GenSigAutoGenDsp" SG_ 64 signal1247 1;
BA_ "GenSigTimeoutMsg_ecu13186" SG_ 64 signal1258 64;
BA_ "NMH-WakeupAllowed" SG_ 64 signal1258 0;
BA_ "NWM-WakeupAllowed" SG_ 64 signal1258 0;
BA_ "GenSigSendType" SG_ 64 signal1258 7;
BA_ "GenSigEnvVarType" SG_ 64 signal1258 0;
BA_ "GenSigAutoGenSnd" SG_ 64 signal1258 1;
BA_ "GenSigAutoGenDsp" SG_ 64 signal1258 1;
BA_ "GenSigTimeoutMsg_ecu13186" SG_ 64 signal1269 64;
BA_ "NMH-WakeupAllowed" SG_ 64 signal1269 0;
BA_ "NWM-WakeupAllowed" SG_ 64 signal1269 0;
BA_ "GenSigSendType" SG_ 64 signal1269 7;
BA_ "GenSigEnvVarType" SG_ 64 signal1269 0;
BA_ "GenSigAutoGenSnd" SG_ 64 signal1269 1;
BA_ "GenSigAutoGenDsp" SG_ 64 signal1269 1;
BA_ "GenSigTimeoutMsg_ecu13186" SG_ 64 signal1280 64;
BA_ "NMH-WakeupAllowed" SG_ 64 signal1280 0;
BA_ "NWM-WakeupAllowed" SG_ 64 signal1280 0;
BA_ "GenSigSendType" SG_ 64 signal1280 7;
BA_ "GenSigEnvVarType" SG_ 64 signal1280 0;
BA_ "GenSigAutoGenSnd" SG_ 64 signal1280 1;
BA_ "GenSigAutoGenDsp" SG_ 64 signal1280 1;
BA_ "GenSigTimeoutMsg_ecu13186" SG_ 1312 signal1297 1312;
BA_ "NMH-WakeupAllowed" SG_ 1312 signal1297 0;
BA_ "NWM-WakeupAllowed" SG_ 1312 signal1297 0;
BA_ "GenSigSendType" SG_ 1312 signal1297 7;
BA_ "GenSigEnvVarType" SG_ 1312 signal1297 0;
BA_ "GenSigAutoGenSnd" SG_ 1312 signal1297 1;
BA_ "GenSigAutoGenDsp" SG_ 1312 signal1297 1;
BA_ "GenSigTimeoutMsg_ecu13186" SG_ 1312 signal1308 1312;
BA_ "NMH-WakeupAllowed" SG_ 1312 signal1308 0;
BA_ "NWM-WakeupAllowed" SG_ 1312 signal1308 0;
BA_ "GenSigSendType" SG_ 1312 signal1308 7;
BA_ "GenSigEnvVarType" SG_ 1312 signal1308 0;
BA_ "GenSigAutoGenSnd" SG_ 1312 signal1308 1;
BA_ "GenSigAutoGenDsp" SG_ 1312 signal1308 1;
BA_ "GenSigTimeoutMsg_ecu13186" SG_ 1312 signal1319 1312;
BA_ "NMH-WakeupAllowed" SG_ 1312 signal1319 0;
BA_ "NWM-WakeupAllowed" SG_ 1312 signal1319 0;
BA_ "GenSigSendType" SG_ 1312 signal1319 7;
BA_ "GenSigEnvVarType" SG_ 1312 signal1319 0;
BA_ "GenSigAutoGenSnd" SG_ 1312 signal1319 1;
BA_ "GenSigAutoGenDsp" SG_ 1312 signal1319 1;
BA_ "GenSigTimeoutMsg_ecu13186" SG_ 1312 signal1330 1312;
BA_ "NMH-WakeupAllowed" SG_ 1312 signal1330 0;
BA_ "NWM-WakeupAllowed" SG_ 1312 signal1330 0;
BA_ "GenSigSendType" SG_ 1312 signal1330 7;
BA_ "GenSigEnvVarType" SG_ 1312 signal1330 0;
BA_ "GenSigAutoGenSnd" SG_ 1312 signal1330 1;
BA_ "GenSigAutoGenDsp" SG_ 1312 signal1330 1;
BA_ "signal136198" SG_ 1633 signal1347 1633;
BA_ "signal133356" SG_ 1633 signal1347 1633;
BA_ "GenSigTimeoutMsg_ecu13120" SG_ 1633 signal1347 1633;
BA_ "signal131970" SG_ 1633 signal1347 1633;
BA_ "signal131977" SG_ 1633 signal1347 1633;
BA_ "NMH-WakeupAllowed" SG_ 1633 signal1347 0;
BA_ "NWM-WakeupAllowed" SG_ 1633 signal1347 0;
BA_ "GenSigSendType" SG_ 1633 signal1347 7;
BA_ "GenSigEnvVarType" SG_ 1633 signal1347 0;
BA_ "GenSigAutoGenSnd" SG_ 1633 signal1347 1;
BA_ "GenSigAutoGenDsp" SG_ 1633 signal1347 1;
BA_ "signal136198" SG_ 1633 signal1362 1633;
BA_ "signal133356" SG_ 1633 signal1362 1633;
BA_ "GenSigTimeoutMsg_ecu13120" SG_ 1633 signal1362 1633;
BA_ "NMH-WakeupAllowed" SG_ 1633 signal1362 0;
BA_ "NWM-WakeupAllowed" SG_ 1633 signal1362 0;
BA_ "GenSigSendType" SG_ 1633 signal1362 7;
BA_ "GenSigEnvVarType" SG_ 1633 signal1362 0;
BA_ "GenSigAutoGenSnd" SG_ 1633 signal1362 1;
BA_ "GenSigAutoGenDsp" SG_ 1633 signal1362 1;
BA_ "NMH-WakeupAllowed" SG_ 1633 signal1375 0;
BA_ "NWM-WakeupAllowed" SG_ 1633 signal1375 0;
BA_ "GenSigSendType" SG_ 1633 signal1375 7;
BA_ "GenSigEnvVarType" SG_ 1633 signal1375 0;
BA_ "GenSigAutoGenSnd" SG_ 1633 signal1375 1;
BA_ "GenSigAutoGenDsp" SG_ 1633 signal1375 1;
BA_ "NMH-WakeupAllowed" SG_ 1633 signal1385 0;
BA_ "NWM-WakeupAllowed" SG_ 1633 signal1385 0;
BA_ "GenSigSendType" SG_ 1633 signal1385 7;
BA_ "GenSigEnvVarType" SG_ 1633 signal1385 0;
BA_ "GenSigAutoGenSnd" SG_ 1633 signal1385 1;
BA_ "GenSigAutoGenDsp" SG_ 1633 signal1385 1;
BA_ "signal136198" SG_ 1633 signal1395 1633;
BA_ "signal133356" SG_ 1633 signal1395 1633;
BA_ "GenSigTimeoutMsg_ecu13120" SG_ 1633 signal1395 1633;
BA_ "GenSigTimeoutMsg_ecu11765" SG_ 1633 signal1395 1633;
BA_ "signal131970" SG_ 1633 signal1395 1633;
BA_ "signal131977" SG_ 1633 signal1395 1633;
BA_ "NMH-WakeupAllowed" SG_ 1633 signal1395 0;
BA_ "NWM-WakeupAllowed" SG_ 1633 signal1395 0;
BA_ "GenSigSendType" SG_ 1633 signal1395 7;
BA_ "GenSigEnvVarType" SG_ 1633 signal1395 0;
BA_ "GenSigAutoGenSnd" SG_ 1633 signal1395 1;
BA_ "GenSigAutoGenDsp" SG_ 1633 signal1395 1;
BA_ "NMH-WakeupAllowed" SG_ 1633 signal1411 0;
BA_ "NWM-WakeupAllowed" SG_ 1633 signal1411 0;
BA_ "GenSigSendType" SG_ 1633 signal1411 7;
BA_ "GenSigEnvVarType" SG_ 1633 signal1411 0;
BA_ "GenSigAutoGenSnd" SG_ 1633 signal1411 1;
BA_ "GenSigAutoGenDsp" SG_ 1633 signal1411 1;
BA_ "NMH-WakeupAllowed" SG_ 1633 signal1421 0;
BA_ "NWM-WakeupAllowed" SG_ 1633 signal1421 0;
BA_ "GenSigSendType" SG_ 1633 signal1421 7;
BA_ "GenSigEnvVarType" SG_ 1633 signal1421 0;
BA_ "GenSigAutoGenSnd" SG_ 1633 signal1421 1;
BA_ "GenSigAutoGenDsp" SG_ 1633 signal1421 1;
BA_ "NMH-WakeupAllowed" SG_ 1633 signal1431 0;
BA_ "NWM-WakeupAllowed" SG_ 1633 signal1431 0;
BA_ "GenSigSendType" SG_ 1633 signal1431 7;
BA_ "GenSigEnvVarType" SG_ 1633 signal1431 0;
BA_ "GenSigAutoGenSnd" SG_ 1633 signal1431 1;
BA_ "GenSigAutoGenDsp" SG_ 1633 signal1431 1;
BA_ "signal136198" SG_ 1633 signal1441 1633;
BA_ "signal133356" SG_ 1633 signal1441 1633;
BA_ "GenSigTimeoutMsg_ecu13120" SG_ 1633 signal1441 1633;
BA_ "NMH-WakeupAllowed" SG_ 1633 signal1441 0;
BA_ "NWM-WakeupAllowed" SG_ 1633 signal1441 0;
BA_ "GenSigSendType" SG_ 1633 signal1441 7;
BA_ "GenSigEnvVarType" SG_ 1633 signal1441 0;
BA_ "GenSigAutoGenSnd" SG_ 1633 signal1441 1;
BA_ "GenSigAutoGenDsp" SG_ 1633 signal1441 1;
BA_ "NMH-WakeupAllowed" SG_ 1633 signal1454 0;
BA_ "NWM-WakeupAllowed" SG_ 1633 signal1454 0;
BA_ "GenSigSendType" SG_ 1633 signal1454 7;
BA_ "GenSigEnvVarType" SG_ 1633 signal1454 0;
BA_ "GenSigAutoGenSnd" SG_ 1633 signal1454 1;
BA_ "GenSigAutoGenDsp" SG_ 1633 signal1454 1;
BA_ "NMH-WakeupAllowed" SG_ 1633 signal1464 0;
BA_ "NWM-WakeupAllowed" SG_ 1633 signal1464 0;
BA_ "GenSigSendType" SG_ 1633 signal1464 7;
BA_ "GenSigEnvVarType" SG_ 1633 signal1464 0;
BA_ "GenSigAutoGenSnd" SG_ 1633 signal1464 1;
BA_ "GenSigAutoGenDsp" SG_ 1633 signal1464 1;
BA_ "NMH-WakeupAllowed" SG_ 1633 signal1474 0;
BA_ "NWM-WakeupAllowed" SG_ 1633 signal1474 0;
BA_ "GenSigSendType" SG_ 1633 signal1474 7;
BA_ "GenSigEnvVarType" SG_ 1633 signal1474 0;
BA_ "GenSigAutoGenSnd" SG_ 1633 signal1474 1;
BA_ "GenSigAutoGenDsp" SG_ 1633 signal1474 1;
BA_ "NMH-WakeupAllowed" SG_ 1633 signal1484 0;
BA_ "NWM-WakeupAllowed" SG_ 1633 signal1484 0;
BA_ "GenSigSendType" SG_ 1633 signal1484 7;
BA_ "GenSigEnvVarType" SG_ 1633 signal1484 0;
BA_ "GenSigAutoGenSnd" SG_ 1633 signal1484 1;
BA_ "GenSigAutoGenDsp" SG_ 1633 signal1484 1;
BA_ "NMH-WakeupAllowed" SG_ 1633 signal1494 0;
BA_ "NWM-WakeupAllowed" SG_ 1633 signal1494 0;
BA_ "GenSigSendType" SG_ 1633 signal1494 7;
BA_ "GenSigEnvVarType" SG_ 1633 signal1494 0;
BA_ "GenSigAutoGenSnd" SG_ 1633 signal1494 1;
BA_ "GenSigAutoGenDsp" SG_ 1633 signal1494 1;
BA_ "signal136198" SG_ 777 signal1510 777;
BA_ "signal133356" SG_ 777 signal1510 777;
BA_ "GenSigTimeoutMsg_ecu13120" SG_ 777 signal1510 777;
BA_ "NMH-WakeupAllowed" SG_ 777 signal1510 0;
BA_ "NWM-WakeupAllowed" SG_ 777 signal1510 0;
BA_ "GenSigSendType" SG_ 777 signal1510 7;
BA_ "GenSigEnvVarType" SG_ 777 signal1510 0;
BA_ "GenSigAutoGenSnd" SG_ 777 signal1510 1;
BA_ "GenSigAutoGenDsp" SG_ 777 signal1510 1;
BA_ "signal136198" SG_ 777 signal1505_BZ 777;
BA_ "signal133356" SG_ 777 signal1505_BZ 777;
BA_ "GenSigTimeoutMsg_ecu13120" SG_ 777 signal1505_BZ 777;
BA_ "NMH-WakeupAllowed" SG_ 777 signal1505_BZ 0;
BA_ "NWM-WakeupAllowed" SG_ 777 signal1505_BZ 0;
BA_ "GenSigSendType" SG_ 777 signal1505_BZ 7;
BA_ "GenSigEnvVarType" SG_ 777 signal1505_BZ 0;
BA_ "GenSigAutoGenSnd" SG_ 777 signal1505_BZ 1;
BA_ "GenSigAutoGenDsp" SG_ 777 signal1505_BZ 1;
BA_ "signal136198" SG_ 777 signal1536 777;
BA_ "signal133356" SG_ 777 signal1536 777;
BA_ "GenSigTimeoutMsg_ecu13120" SG_ 777 signal1536 777;
BA_ "NMH-WakeupAllowed" SG_ 777 signal1536 0;
BA_ "NWM-WakeupAllowed" SG_ 777 signal1536 0;
BA_ "GenSigSendType" SG_ 777 signal1536 7;
BA_ "GenSigEnvVarType" SG_ 777 signal1536 0;
BA_ "GenSigAutoGenSnd" SG_ 777 signal1536 1;
BA_ "GenSigAutoGenDsp" SG_ 777 signal1536 1;
BA_ "signal136198" SG_ 777 signal1549 777;
BA_ "signal133356" SG_ 777 signal1549 777;
BA_ "GenSigTimeoutMsg_ecu13120" SG_ 777 signal1549 777;
BA_ "NMH-WakeupAllowed" SG_ 777 signal1549 0;
BA_ "NWM-WakeupAllowed" SG_ 777 signal1549 0;
BA_ "GenSigSendType" SG_ 777 signal1549 7;
BA_ "GenSigEnvVarType" SG_ 777 signal1549 0;
BA_ "GenSigAutoGenSnd" SG_ 777 signal1549 1;
BA_ "GenSigAutoGenDsp" SG_ 777 signal1549 1;
BA_ "signal136198" SG_ 777 signal1562 777;
BA_ "signal133356" SG_ 777 signal1562 777;
BA_ "GenSigTimeoutMsg_ecu13120" SG_ 777 signal1562 777;
BA_ "NMH-WakeupAllowed" SG_ 777 signal1562 0;
BA_ "NWM-WakeupAllowed" SG_ 777 signal1562 0;
BA_ "GenSigSendType" SG_ 777 signal1562 7;
BA_ "GenSigEnvVarType" SG_ 777 signal1562 0;
BA_ "GenSigAutoGenSnd" SG_ 777 signal1562 1;
BA_ "GenSigAutoGenDsp" SG_ 777 signal1562 1;
BA_ "signal136198" SG_ 777 signal1575 777;
BA_ "signal133356" SG_ 777 signal1575 777;
BA_ "GenSigTimeoutMsg_ecu13120" SG_ 777 signal1575 777;
BA_ "NMH-WakeupAllowed" SG_ 777 signal1575 0;
BA_ "NWM-WakeupAllowed" SG_ 777 signal1575 0;
BA_ "GenSigSendType" SG_ 777 signal1575 7;
BA_ "GenSigEnvVarType" SG_ 777 signal1575 0;
BA_ "GenSigAutoGenSnd" SG_ 777 signal1575 1;
BA_ "GenSigAutoGenDsp" SG_ 777 signal1575 1;
BA_ "GenSigTimeoutMsg_ecu12990" SG_ 1635 signal1594 1635;
BA_ "NMH-WakeupAllowed" SG_ 1635 signal1594 0;
BA_ "NWM-WakeupAllowed" SG_ 1635 signal1594 0;
BA_ "GenSigSendType" SG_ 1635 signal1594 7;
BA_ "GenSigEnvVarType" SG_ 1635 signal1594 0;
BA_ "GenSigAutoGenSnd" SG_ 1635 signal1594 1;
BA_ "GenSigAutoGenDsp" SG_ 1635 signal1594 1;
BA_ "NMH-WakeupAllowed" SG_ 1635 signal1605 0;
BA_ "NWM-WakeupAllowed" SG_ 1635 signal1605 0;
BA_ "GenSigSendType" SG_ 1635 signal1605 7;
BA_ "GenSigEnvVarType" SG_ 1635 signal1605 0;
BA_ "GenSigAutoGenSnd" SG_ 1635 signal1605 1;
BA_ "GenSigAutoGenDsp" SG_ 1635 signal1605 1;
BA_ "NMH-WakeupAllowed" SG_ 1635 signal1615 0;
BA_ "NWM-WakeupAllowed" SG_ 1635 signal1615 0;
BA_ "GenSigSendType" SG_ 1635 signal1615 7;
BA_ "GenSigEnvVarType" SG_ 1635 signal1615 0;
BA_ "GenSigAutoGenSnd" SG_ 1635 signal1615 1;
BA_ "GenSigAutoGenDsp" SG_ 1635 signal1615 1;
BA_ "NMH-WakeupAllowed" SG_ 1635 signal1625 0;
BA_ "NWM-WakeupAllowed" SG_ 1635 signal1625 0;
BA_ "GenSigSendType" SG_ 1635 signal1625 7;
BA_ "GenSigEnvVarType" SG_ 1635 signal1625 0;
BA_ "GenSigAutoGenSnd" SG_ 1635 signal1625 1;
BA_ "GenSigAutoGenDsp" SG_ 1635 signal1625 1;
BA_ "NMH-WakeupAllowed" SG_ 1635 signal1635 0;
BA_ "NWM-WakeupAllowed" SG_ 1635 signal1635 0;
BA_ "GenSigSendType" SG_ 1635 signal1635 7;
BA_ "GenSigEnvVarType" SG_ 1635 signal1635 0;
BA_ "GenSigAutoGenSnd" SG_ 1635 signal1635 1;
BA_ "GenSigAutoGenDsp" SG_ 1635 signal1635 1;
BA_ "GenSigTimeoutMsg_ecu12990" SG_ 1635 signal1645 1635;
BA_ "NMH-WakeupAllowed" SG_ 1635 signal1645 0;
BA_ "NWM-WakeupAllowed" SG_ 1635 signal1645 0;
BA_ "GenSigSendType" SG_ 1635 signal1645 7;
BA_ "GenSigEnvVarType" SG_ 1635 signal1645 0;
BA_ "GenSigAutoGenSnd" SG_ 1635 signal1645 1;
BA_ "GenSigAutoGenDsp" SG_ 1635 signal1645 1;
BA_ "NMH-WakeupAllowed" SG_ 1635 signal1656 0;
BA_ "NWM-WakeupAllowed" SG_ 1635 signal1656 0;
BA_ "GenSigSendType" SG_ 1635 signal1656 7;
BA_ "GenSigEnvVarType" SG_ 1635 signal1656 0;
BA_ "GenSigAutoGenSnd" SG_ 1635 signal1656 1;
BA_ "GenSigAutoGenDsp" SG_ 1635 signal1656 1;
BA_ "NMH-WakeupAllowed" SG_ 1635 signal1666 0;
BA_ "NWM-WakeupAllowed" SG_ 1635 signal1666 0;
BA_ "GenSigStartValue" SG_ 1635 signal1666 14;
BA_ "GenSigSendType" SG_ 1635 signal1666 7;
BA_ "GenSigEnvVarType" SG_ 1635 signal1666 0;
BA_ "GenSigAutoGenSnd" SG_ 1635 signal1666 1;
BA_ "GenSigAutoGenDsp" SG_ 1635 signal1666 1;
BA_ "NMH-WakeupAllowed" SG_ 1635 signal1676 0;
BA_ "NWM-WakeupAllowed" SG_ 1635 signal1676 0;
BA_ "GenSigSendType" SG_ 1635 signal1676 7;
BA_ "GenSigEnvVarType" SG_ 1635 signal1676 0;
BA_ "GenSigAutoGenSnd" SG_ 1635 signal1676 1;
BA_ "GenSigAutoGenDsp" SG_ 1635 signal1676 1;
BA_ "GenSigTimeoutMsg_ecu11765" SG_ 482 signal1692 482;
BA_ "signal131970" SG_ 482 signal1692 482;
BA_ "signal131977" SG_ 482 signal1692 482;
BA_ "NMH-WakeupAllowed" SG_ 482 signal1692 0;
BA_ "NWM-WakeupAllowed" SG_ 482 signal1692 0;
BA_ "GenSigSendType" SG_ 482 signal1692 7;
BA_ "GenSigEnvVarType" SG_ 482 signal1692 0;
BA_ "GenSigAutoGenSnd" SG_ 482 signal1692 1;
BA_ "GenSigAutoGenDsp" SG_ 482 signal1692 1;
BA_ "NMH-WakeupAllowed" SG_ 490 signal1706_Data 0;
BA_ "NWM-WakeupAllowed" SG_ 490 signal1706_Data 0;
BA_ "GenSigSendType" SG_ 490 signal1706_Data 7;
BA_ "GenSigEnvVarType" SG_ 490 signal1706_Data 0;
BA_ "GenSigAutoGenSnd" SG_ 490 signal1706_Data 1;
BA_ "GenSigAutoGenDsp" SG_ 490 signal1706_Data 1;
BA_ "signal136198" SG_ 480 signal1727 480;
BA_ "signal133356" SG_ 480 signal1727 480;
BA_ "GenSigTimeoutMsg_ecu13120" SG_ 480 signal1727 480;
BA_ "NMH-WakeupAllowed" SG_ 480 signal1727 0;
BA_ "NWM-WakeupAllowed" SG_ 480 signal1727 0;
BA_ "GenSigSendType" SG_ 480 signal1727 7;
BA_ "GenSigEnvVarType" SG_ 480 signal1727 0;
BA_ "GenSigAutoGenSnd" SG_ 480 signal1727 1;
BA_ "GenSigAutoGenDsp" SG_ 480 signal1727 1;
BA_ "signal136198" SG_ 2616986624 signal1746 469502976;
BA_ "signal133356" SG_ 2616986624 signal1746 469502976;
BA_ "GenSigTimeoutMsg_ecu13120" SG_ 2616986624 signal1746 469502976;
BA_ "NMH-WakeupAllowed" SG_ 2616986624 signal1746 0;
BA_ "NWM-WakeupAllowed" SG_ 2616986624 signal1746 0;
BA_ "GenSigSendType" SG_ 2616986624 signal1746 7;
BA_ "GenSigEnvVarType" SG_ 2616986624 signal1746 0;
BA_ "GenSigAutoGenSnd" SG_ 2616986624 signal1746 1;
BA_ "GenSigAutoGenDsp" SG_ 2616986624 signal1746 1;
BA_ "NMH-WakeupAllowed" SG_ 488 signal1765 0;
BA_ "NWM-WakeupAllowed" SG_ 488 signal1765 0;
BA_ "GenSigSendType" SG_ 488 signal1765 7;
BA_ "GenSigEnvVarType" SG_ 488 signal1765 0;
BA_ "GenSigAutoGenSnd" SG_ 488 signal1765 1;
BA_ "GenSigAutoGenDsp" SG_ 488 signal1765 1;
BA_ "NMH-WakeupAllowed" SG_ 2616986625 signal1781 0;
BA_ "NWM-WakeupAllowed" SG_ 2616986625 signal1781 0;
BA_ "GenSigSendType" SG_ 2616986625 signal1781 7;
BA_ "GenSigEnvVarType" SG_ 2616986625 signal1781 0;
BA_ "GenSigAutoGenSnd" SG_ 2616986625 signal1781 1;
BA_ "GenSigAutoGenDsp" SG_ 2616986625 signal1781 1;
BA_ "GenSigTimeoutMsg_ecu8948" SG_ 481 signal1792_Data 481;
BA_ "NMH-WakeupAllowed" SG_ 481 signal1792_Data 0;
BA_ "NWM-WakeupAllowed" SG_ 481 signal1792_Data 0;
BA_ "GenSigSendType" SG_ 481 signal1792_Data 7;
BA_ "GenSigEnvVarType" SG_ 481 signal1792_Data 0;
BA_ "GenSigAutoGenSnd" SG_ 481 signal1792_Data 1;
BA_ "GenSigAutoGenDsp" SG_ 481 signal1792_Data 1;
BA_ "GenSigTimeoutMsg_ecu8948" SG_ 2616986629 signal1814 469502981;
BA_ "NMH-WakeupAllowed" SG_ 2616986629 signal1814 0;
BA_ "NWM-WakeupAllowed" SG_ 2616986629 signal1814 0;
BA_ "GenSigSendType" SG_ 2616986629 signal1814 7;
BA_ "GenSigEnvVarType" SG_ 2616986629 signal1814 0;
BA_ "GenSigAutoGenSnd" SG_ 2616986629 signal1814 1;
BA_ "GenSigAutoGenDsp" SG_ 2616986629 signal1814 1;
BA_ "NMH-WakeupAllowed" SG_ 489 signal1831 0;
BA_ "NWM-WakeupAllowed" SG_ 489 signal1831 0;
BA_ "GenSigSendType" SG_ 489 signal1831 7;
BA_ "GenSigEnvVarType" SG_ 489 signal1831 0;
BA_ "GenSigAutoGenSnd" SG_ 489 signal1831 1;
BA_ "GenSigAutoGenDsp" SG_ 489 signal1831 1;
BA_ "NMH-WakeupAllowed" SG_ 2616986630 signal1842_Data 0;
BA_ "NWM-WakeupAllowed" SG_ 2616986630 signal1842_Data 0;
BA_ "GenSigSendType" SG_ 2616986630 signal1842_Data 7;
BA_ "GenSigEnvVarType" SG_ 2616986630 signal1842_Data 0;
BA_ "GenSigAutoGenSnd" SG_ 2616986630 signal1842_Data 1;
BA_ "GenSigAutoGenDsp" SG_ 2616986630 signal1842_Data 1;
BA_ "signal142820" SG_ 901 signal1863 901;
BA_ "signal136198" SG_ 901 signal1863 901;
BA_ "signal133356" SG_ 901 signal1863 901;
BA_ "GenSigTimeoutMsg_ecu13120" SG_ 901 signal1863 901;
BA_ "GenSigTimeoutMsg_ecu11765" SG_ 901 signal1863 901;
BA_ "signal131970" SG_ 901 signal1863 901;
BA_ "signal131977" SG_ 901 signal1863 901;
BA_ "NMH-WakeupAllowed" SG_ 901 signal1863 0;
BA_ "NWM-WakeupAllowed" SG_ 901 signal1863 0;
BA_ "GenSigSendType" SG_ 901 signal1863 7;
BA_ "GenSigEnvVarType" SG_ 901 signal1863 0;
BA_ "GenSigAutoGenSnd" SG_ 901 signal1863 1;
BA_ "GenSigAutoGenDsp" SG_ 901 signal1863 1;
BA_ "NMH-WakeupAllowed" SG_ 901 signal1880 0;
BA_ "NWM-WakeupAllowed" SG_ 901 signal1880 0;
BA_ "GenSigSendType" SG_ 901 signal1880 7;
BA_ "GenSigEnvVarType" SG_ 901 signal1880 0;
BA_ "GenSigAutoGenSnd" SG_ 901 signal1880 1;
BA_ "GenSigAutoGenDsp" SG_ 901 signal1880 1;
BA_ "signal142820" SG_ 901 signal1890 901;
BA_ "signal136198" SG_ 901 signal1890 901;
BA_ "signal133356" SG_ 901 signal1890 901;
BA_ "GenSigTimeoutMsg_ecu13120" SG_ 901 signal1890 901;
BA_ "GenSigTimeoutMsg_ecu11765" SG_ 901 signal1890 901;
BA_ "signal131970" SG_ 901 signal1890 901;
BA_ "signal131977" SG_ 901 signal1890 901;
BA_ "NMH-WakeupAllowed" SG_ 901 signal1890 0;
BA_ "NWM-WakeupAllowed" SG_ 901 signal1890 0;
BA_ "GenSigSendType" SG_ 901 signal1890 7;
BA_ "GenSigEnvVarType" SG_ 901 signal1890 0;
BA_ "GenSigAutoGenSnd" SG_ 901 signal1890 1;
BA_ "GenSigAutoGenDsp" SG_ 901 signal1890 1;
BA_ "signal136198" SG_ 901 signal1907 901;
BA_ "signal133356" SG_ 901 signal1907 901;
BA_ "GenSigTimeoutMsg_ecu13120" SG_ 901 signal1907 901;
BA_ "NMH-WakeupAllowed" SG_ 901 signal1907 0;
BA_ "NWM-WakeupAllowed" SG_ 901 signal1907 0;
BA_ "GenSigSendType" SG_ 901 signal1907 7;
BA_ "GenSigEnvVarType" SG_ 901 signal1907 0;
BA_ "GenSigAutoGenSnd" SG_ 901 signal1907 1;
BA_ "GenSigAutoGenDsp" SG_ 901 signal1907 1;
BA_ "GenSigTimeoutMsg_ecu11765" SG_ 901 signal1920 901;
BA_ "signal131970" SG_ 901 signal1920 901;
BA_ "signal131977" SG_ 901 signal1920 901;
BA_ "NMH-WakeupAllowed" SG_ 901 signal1920 0;
BA_ "NWM-WakeupAllowed" SG_ 901 signal1920 0;
BA_ "GenSigSendType" SG_ 901 signal1920 7;
BA_ "GenSigEnvVarType" SG_ 901 signal1920 0;
BA_ "GenSigAutoGenSnd" SG_ 901 signal1920 1;
BA_ "GenSigAutoGenDsp" SG_ 901 signal1920 1;
BA_ "NMH-WakeupAllowed" SG_ 901 signal1933 0;
BA_ "NWM-WakeupAllowed" SG_ 901 signal1933 0;
BA_ "GenSigSendType" SG_ 901 signal1933 7;
BA_ "GenSigEnvVarType" SG_ 901 signal1933 0;
BA_ "GenSigAutoGenSnd" SG_ 901 signal1933 1;
BA_ "GenSigAutoGenDsp" SG_ 901 signal1933 1;
BA_ "signal142820" SG_ 901 signal1943 901;
BA_ "NMH-WakeupAllowed" SG_ 901 signal1943 0;
BA_ "NWM-WakeupAllowed" SG_ 901 signal1943 0;
BA_ "GenSigSendType" SG_ 901 signal1943 7;
BA_ "GenSigEnvVarType" SG_ 901 signal1943 0;
BA_ "GenSigAutoGenSnd" SG_ 901 signal1943 1;
BA_ "GenSigAutoGenDsp" SG_ 901 signal1943 1;
BA_ "NMH-WakeupAllowed" SG_ 901 signal1954 0;
BA_ "NWM-WakeupAllowed" SG_ 901 signal1954 0;
BA_ "GenSigSendType" SG_ 901 signal1954 7;
BA_ "GenSigEnvVarType" SG_ 901 signal1954 0;
BA_ "GenSigAutoGenSnd" SG_ 901 signal1954 1;
BA_ "GenSigAutoGenDsp" SG_ 901 signal1954 1;
BA_ "NMH-WakeupAllowed" SG_ 901 signal1964 0;
BA_ "NWM-WakeupAllowed" SG_ 901 signal1964 0;
BA_ "GenSigSendType" SG_ 901 signal1964 7;
BA_ "GenSigEnvVarType" SG_ 901 signal1964 0;
BA_ "GenSigAutoGenSnd" SG_ 901 signal1964 1;
BA_ "GenSigAutoGenDsp" SG_ 901 signal1964 1;
BA_ "NMH-WakeupAllowed" SG_ 901 signal1974 0;
BA_ "NWM-WakeupAllowed" SG_ 901 signal1974 0;
BA_ "GenSigSendType" SG_ 901 signal1974 7;
BA_ "GenSigEnvVarType" SG_ 901 signal1974 0;
BA_ "GenSigAutoGenSnd" SG_ 901 signal1974 1;
BA_ "GenSigAutoGenDsp" SG_ 901 signal1974 1;
BA_ "NMH-WakeupAllowed" SG_ 901 signal1984 0;
BA_ "NWM-WakeupAllowed" SG_ 901 signal1984 0;
BA_ "GenSigSendType" SG_ 901 signal1984 7;
BA_ "GenSigEnvVarType" SG_ 901 signal1984 0;
BA_ "GenSigAutoGenSnd" SG_ 901 signal1984 1;
BA_ "GenSigAutoGenDsp" SG_ 901 signal1984 1;
BA_ "GenSigTimeoutMsg_ecu12990" SG_ 1714 signal2000 1714;
BA_ "signal142820" SG_ 1714 signal2000 1714;
BA_ "GenSigTimeoutMsg_ecu12594" SG_ 1714 signal2000 1714;
BA_ "signal142834" SG_ 1714 signal2000 1714;
BA_ "NMH-WakeupAllowed" SG_ 1714 signal2000 0;
BA_ "NWM-WakeupAllowed" SG_ 1714 signal2000 0;
BA_ "GenSigSendType" SG_ 1714 signal2000 7;
BA_ "GenSigEnvVarType" SG_ 1714 signal2000 0;
BA_ "GenSigAutoGenSnd" SG_ 1714 signal2000 1;
BA_ "GenSigAutoGenDsp" SG_ 1714 signal2000 1;
BA_ "GenSigTimeoutMsg_ecu12990" SG_ 1714 signal2014 1714;
BA_ "signal142820" SG_ 1714 signal2014 1714;
BA_ "signal136198" SG_ 1714 signal2014 1714;
BA_ "signal133356" SG_ 1714 signal2014 1714;
BA_ "GenSigTimeoutMsg_ecu13120" SG_ 1714 signal2014 1714;
BA_ "GenSigTimeoutMsg_ecu11765" SG_ 1714 signal2014 1714;
BA_ "signal131970" SG_ 1714 signal2014 1714;
BA_ "signal131977" SG_ 1714 signal2014 1714;
BA_ "GenSigTimeoutMsg_ecu12594" SG_ 1714 signal2014 1714;
BA_ "signal142834" SG_ 1714 signal2014 1714;
BA_ "NMH-WakeupAllowed" SG_ 1714 signal2014 0;
BA_ "NWM-WakeupAllowed" SG_ 1714 signal2014 0;
BA_ "GenSigStartValue" SG_ 1714 signal2014 1048574;
BA_ "GenSigSendType" SG_ 1714 signal2014 7;
BA_ "GenSigEnvVarType" SG_ 1714 signal2014 0;
BA_ "GenSigAutoGenSnd" SG_ 1714 signal2014 1;
BA_ "GenSigAutoGenDsp" SG_ 1714 signal2014 1;
BA_ "GenSigTimeoutMsg_ecu12990" SG_ 1714 signal2034 1714;
BA_ "signal142820" SG_ 1714 signal2034 1714;
BA_ "signal136198" SG_ 1714 signal2034 1714;
BA_ "signal133356" SG_ 1714 signal2034 1714;
BA_ "GenSigTimeoutMsg_ecu13120" SG_ 1714 signal2034 1714;
BA_ "GenSigTimeoutMsg_ecu11765" SG_ 1714 signal2034 1714;
BA_ "signal131970" SG_ 1714 signal2034 1714;
BA_ "signal131977" SG_ 1714 signal2034 1714;
BA_ "GenSigTimeoutMsg_ecu12594" SG_ 1714 signal2034 1714;
BA_ "signal142834" SG_ 1714 signal2034 1714;
BA_ "NMH-WakeupAllowed" SG_ 1714 signal2034 0;
BA_ "NWM-WakeupAllowed" SG_ 1714 signal2034 0;
BA_ "GenSigSendType" SG_ 1714 signal2034 7;
BA_ "GenSigEnvVarType" SG_ 1714 signal2034 0;
BA_ "GenSigAutoGenSnd" SG_ 1714 signal2034 1;
BA_ "GenSigAutoGenDsp" SG_ 1714 signal2034 1;
BA_ "GenSigTimeoutMsg_ecu12990" SG_ 1714 signal2054 1714;
BA_ "signal142820" SG_ 1714 signal2054 1714;
BA_ "signal136198" SG_ 1714 signal2054 1714;
BA_ "signal133356" SG_ 1714 signal2054 1714;
BA_ "GenSigTimeoutMsg_ecu13120" SG_ 1714 signal2054 1714;
BA_ "GenSigTimeoutMsg_ecu11765" SG_ 1714 signal2054 1714;
BA_ "signal131970" SG_ 1714 signal2054 1714;
BA_ "signal131977" SG_ 1714 signal2054 1714;
BA_ "GenSigTimeoutMsg_ecu12594" SG_ 1714 signal2054 1714;
BA_ "signal142834" SG_ 1714 signal2054 1714;
BA_ "NMH-WakeupAllowed" SG_ 1714 signal2054 0;
BA_ "NWM-WakeupAllowed" SG_ 1714 signal2054 0;
BA_ "GenSigSendType" SG_ 1714 signal2054 7;
BA_ "GenSigEnvVarType" SG_ 1714 signal2054 0;
BA_ "GenSigAutoGenSnd" SG_ 1714 signal2054 1;
BA_ "GenSigAutoGenDsp" SG_ 1714 signal2054 1;
BA_ "GenSigTimeoutMsg_ecu12990" SG_ 1714 signal2074 1714;
BA_ "signal142820" SG_ 1714 signal2074 1714;
BA_ "signal136198" SG_ 1714 signal2074 1714;
BA_ "signal133356" SG_ 1714 signal2074 1714;
BA_ "GenSigTimeoutMsg_ecu13120" SG_ 1714 signal2074 1714;
BA_ "GenSigTimeoutMsg_ecu11765" SG_ 1714 signal2074 1714;
BA_ "signal131970" SG_ 1714 signal2074 1714;
BA_ "signal131977" SG_ 1714 signal2074 1714;
BA_ "GenSigTimeoutMsg_ecu12594" SG_ 1714 signal2074 1714;
BA_ "signal142834" SG_ 1714 signal2074 1714;
BA_ "NMH-WakeupAllowed" SG_ 1714 signal2074 0;
BA_ "NWM-WakeupAllowed" SG_ 1714 signal2074 0;
BA_ "GenSigSendType" SG_ 1714 signal2074 7;
BA_ "GenSigEnvVarType" SG_ 1714 signal2074 0;
BA_ "GenSigAutoGenSnd" SG_ 1714 signal2074 1;
BA_ "GenSigAutoGenDsp" SG_ 1714 signal2074 1;
BA_ "GenSigTimeoutMsg_ecu12990" SG_ 1714 signal2094 1714;
BA_ "signal142820" SG_ 1714 signal2094 1714;
BA_ "signal136198" SG_ 1714 signal2094 1714;
BA_ "signal133356" SG_ 1714 signal2094 1714;
BA_ "GenSigTimeoutMsg_ecu13120" SG_ 1714 signal2094 1714;
BA_ "GenSigTimeoutMsg_ecu11765" SG_ 1714 signal2094 1714;
BA_ "signal131970" SG_ 1714 signal2094 1714;
BA_ "signal131977" SG_ 1714 signal2094 1714;
BA_ "GenSigTimeoutMsg_ecu12594" SG_ 1714 signal2094 1714;
BA_ "signal142834" SG_ 1714 signal2094 1714;
BA_ "NMH-WakeupAllowed" SG_ 1714 signal2094 0;
BA_ "NWM-WakeupAllowed" SG_ 1714 signal2094 0;
BA_ "GenSigSendType" SG_ 1714 signal2094 7;
BA_ "GenSigEnvVarType" SG_ 1714 signal2094 0;
BA_ "GenSigAutoGenSnd" SG_ 1714 signal2094 1;
BA_ "GenSigAutoGenDsp" SG_ 1714 signal2094 1;
BA_ "GenSigTimeoutMsg_ecu12990" SG_ 1714 signal2114 1714;
BA_ "signal142820" SG_ 1714 signal2114 1714;
BA_ "signal136198" SG_ 1714 signal2114 1714;
BA_ "signal133356" SG_ 1714 signal2114 1714;
BA_ "GenSigTimeoutMsg_ecu13120" SG_ 1714 signal2114 1714;
BA_ "GenSigTimeoutMsg_ecu11765" SG_ 1714 signal2114 1714;
BA_ "signal131970" SG_ 1714 signal2114 1714;
BA_ "signal131977" SG_ 1714 signal2114 1714;
BA_ "GenSigTimeoutMsg_ecu12594" SG_ 1714 signal2114 1714;
BA_ "signal142834" SG_ 1714 signal2114 1714;
BA_ "NMH-WakeupAllowed" SG_ 1714 signal2114 0;
BA_ "NWM-WakeupAllowed" SG_ 1714 signal2114 0;
BA_ "GenSigSendType" SG_ 1714 signal2114 7;
BA_ "GenSigEnvVarType" SG_ 1714 signal2114 0;
BA_ "GenSigAutoGenSnd" SG_ 1714 signal2114 1;
BA_ "GenSigAutoGenDsp" SG_ 1714 signal2114 1;
BA_ "GenSigTimeoutMsg_ecu12990" SG_ 1714 signal2134 1714;
BA_ "signal142820" SG_ 1714 signal2134 1714;
BA_ "signal136198" SG_ 1714 signal2134 1714;
BA_ "signal133356" SG_ 1714 signal2134 1714;
BA_ "GenSigTimeoutMsg_ecu13120" SG_ 1714 signal2134 1714;
BA_ "GenSigTimeoutMsg_ecu11765" SG_ 1714 signal2134 1714;
BA_ "signal131970" SG_ 1714 signal2134 1714;
BA_ "signal131977" SG_ 1714 signal2134 1714;
BA_ "GenSigTimeoutMsg_ecu12594" SG_ 1714 signal2134 1714;
BA_ "signal142834" SG_ 1714 signal2134 1714;
BA_ "NMH-WakeupAllowed" SG_ 1714 signal2134 0;
BA_ "NWM-WakeupAllowed" SG_ 1714 signal2134 0;
BA_ "GenSigSendType" SG_ 1714 signal2134 7;
BA_ "GenSigEnvVarType" SG_ 1714 signal2134 0;
BA_ "GenSigAutoGenSnd" SG_ 1714 signal2134 1;
BA_ "GenSigAutoGenDsp" SG_ 1714 signal2134 1;
BA_ "GenSigTimeoutMsg_ecu12990" SG_ 1714 signal6385_alt 1714;
BA_ "signal142820" SG_ 1714 signal6385_alt 1714;
BA_ "signal136198" SG_ 1714 signal6385_alt 1714;
BA_ "signal133356" SG_ 1714 signal6385_alt 1714;
BA_ "GenSigTimeoutMsg_ecu13120" SG_ 1714 signal6385_alt 1714;
BA_ "GenSigTimeoutMsg_ecu11765" SG_ 1714 signal6385_alt 1714;
BA_ "signal131970" SG_ 1714 signal6385_alt 1714;
BA_ "signal131977" SG_ 1714 signal6385_alt 1714;
BA_ "GenSigTimeoutMsg_ecu12594" SG_ 1714 signal6385_alt 1714;
BA_ "signal142834" SG_ 1714 signal6385_alt 1714;
BA_ "NMH-WakeupAllowed" SG_ 1714 signal6385_alt 0;
BA_ "NWM-WakeupAllowed" SG_ 1714 signal6385_alt 0;
BA_ "GenSigStartValue" SG_ 1714 signal6385_alt 1;
BA_ "GenSigSendType" SG_ 1714 signal6385_alt 7;
BA_ "GenSigEnvVarType" SG_ 1714 signal6385_alt 0;
BA_ "GenSigAutoGenSnd" SG_ 1714 signal6385_alt 1;
BA_ "GenSigAutoGenDsp" SG_ 1714 signal6385_alt 1;
BA_ "GenSigTimeoutMsg_ecu12990" SG_ 1714 signal2174 1714;
BA_ "signal142820" SG_ 1714 signal2174 1714;
BA_ "signal136198" SG_ 1714 signal2174 1714;
BA_ "signal133356" SG_ 1714 signal2174 1714;
BA_ "GenSigTimeoutMsg_ecu13120" SG_ 1714 signal2174 1714;
BA_ "GenSigTimeoutMsg_ecu11765" SG_ 1714 signal2174 1714;
BA_ "signal131970" SG_ 1714 signal2174 1714;
BA_ "signal131977" SG_ 1714 signal2174 1714;
BA_ "GenSigTimeoutMsg_ecu12594" SG_ 1714 signal2174 1714;
BA_ "signal142834" SG_ 1714 signal2174 1714;
BA_ "NMH-WakeupAllowed" SG_ 1714 signal2174 0;
BA_ "NWM-WakeupAllowed" SG_ 1714 signal2174 0;
BA_ "GenSigStartValue" SG_ 1714 signal2174 1;
BA_ "GenSigSendType" SG_ 1714 signal2174 7;
BA_ "GenSigEnvVarType" SG_ 1714 signal2174 0;
BA_ "GenSigAutoGenSnd" SG_ 1714 signal2174 1;
BA_ "GenSigAutoGenDsp" SG_ 1714 signal2174 1;
BA_ "signal142834" SG_ 1520 signal2200 1520;
BA_ "NMH-WakeupAllowed" SG_ 1520 signal2200 0;
BA_ "NWM-WakeupAllowed" SG_ 1520 signal2200 0;
BA_ "GenSigStartValue" SG_ 1520 signal2200 254;
BA_ "GenSigSendType" SG_ 1520 signal2200 7;
BA_ "GenSigEnvVarType" SG_ 1520 signal2200 0;
BA_ "GenSigAutoGenSnd" SG_ 1520 signal2200 1;
BA_ "GenSigAutoGenDsp" SG_ 1520 signal2200 1;
BA_ "NMH-WakeupAllowed" SG_ 1520 signal2211 0;
BA_ "NWM-WakeupAllowed" SG_ 1520 signal2211 0;
BA_ "GenSigStartValue" SG_ 1520 signal2211 126;
BA_ "GenSigSendType" SG_ 1520 signal2211 7;
BA_ "GenSigEnvVarType" SG_ 1520 signal2211 0;
BA_ "GenSigAutoGenSnd" SG_ 1520 signal2211 1;
BA_ "GenSigAutoGenDsp" SG_ 1520 signal2211 1;
BA_ "NMH-WakeupAllowed" SG_ 1520 signal2221 0;
BA_ "NWM-WakeupAllowed" SG_ 1520 signal2221 0;
BA_ "GenSigStartValue" SG_ 1520 signal2221 126;
BA_ "GenSigSendType" SG_ 1520 signal2221 7;
BA_ "GenSigEnvVarType" SG_ 1520 signal2221 0;
BA_ "GenSigAutoGenSnd" SG_ 1520 signal2221 1;
BA_ "GenSigAutoGenDsp" SG_ 1520 signal2221 1;
BA_ "NMH-WakeupAllowed" SG_ 1520 signal2231 0;
BA_ "NWM-WakeupAllowed" SG_ 1520 signal2231 0;
BA_ "GenSigSendType" SG_ 1520 signal2231 7;
BA_ "GenSigEnvVarType" SG_ 1520 signal2231 0;
BA_ "GenSigAutoGenSnd" SG_ 1520 signal2231 1;
BA_ "GenSigAutoGenDsp" SG_ 1520 signal2231 1;
BA_ "signal136198" SG_ 260 signal2242_CHK 260;
BA_ "signal133356" SG_ 260 signal2242_CHK 260;
BA_ "GenSigTimeoutMsg_ecu13120" SG_ 260 signal2242_CHK 260;
BA_ "GenSigTimeoutMsg_ecu13186" SG_ 260 signal2242_CHK 260;
BA_ "NMH-WakeupAllowed" SG_ 260 signal2242_CHK 0;
BA_ "NWM-WakeupAllowed" SG_ 260 signal2242_CHK 0;
BA_ "GenSigSendType" SG_ 260 signal2242_CHK 7;
BA_ "GenSigEnvVarType" SG_ 260 signal2242_CHK 0;
BA_ "GenSigAutoGenSnd" SG_ 260 signal2242_CHK 1;
BA_ "GenSigAutoGenDsp" SG_ 260 signal2242_CHK 1;
BA_ "signal136198" SG_ 260 signal2261 260;
BA_ "signal133356" SG_ 260 signal2261 260;
BA_ "GenSigTimeoutMsg_ecu13120" SG_ 260 signal2261 260;
BA_ "GenSigTimeoutMsg_ecu13186" SG_ 260 signal2261 260;
BA_ "NMH-WakeupAllowed" SG_ 260 signal2261 0;
BA_ "NWM-WakeupAllowed" SG_ 260 signal2261 0;
BA_ "GenSigSendType" SG_ 260 signal2261 7;
BA_ "GenSigEnvVarType" SG_ 260 signal2261 0;
BA_ "GenSigAutoGenSnd" SG_ 260 signal2261 1;
BA_ "GenSigAutoGenDsp" SG_ 260 signal2261 1;
BA_ "GenSigTimeoutMsg_ecu13186" SG_ 260 signal2275 260;
BA_ "NMH-WakeupAllowed" SG_ 260 signal2275 0;
BA_ "NWM-WakeupAllowed" SG_ 260 signal2275 0;
BA_ "GenSigStartValue" SG_ 260 signal2275 1;
BA_ "GenSigSendType" SG_ 260 signal2275 7;
BA_ "GenSigEnvVarType" SG_ 260 signal2275 0;
BA_ "GenSigAutoGenSnd" SG_ 260 signal2275 1;
BA_ "GenSigAutoGenDsp" SG_ 260 signal2275 1;
BA_ "signal136198" SG_ 260 signal2286 260;
BA_ "signal133356" SG_ 260 signal2286 260;
BA_ "GenSigTimeoutMsg_ecu13120" SG_ 260 signal2286 260;
BA_ "GenSigTimeoutMsg_ecu13186" SG_ 260 signal2286 260;
BA_ "NMH-WakeupAllowed" SG_ 260 signal2286 0;
BA_ "NWM-WakeupAllowed" SG_ 260 signal2286 0;
BA_ "GenSigStartValue" SG_ 260 signal2286 1;
BA_ "GenSigSendType" SG_ 260 signal2286 7;
BA_ "GenSigEnvVarType" SG_ 260 signal2286 0;
BA_ "GenSigAutoGenSnd" SG_ 260 signal2286 1;
BA_ "GenSigAutoGenDsp" SG_ 260 signal2286 1;
BA_ "GenSigTimeoutMsg_ecu13186" SG_ 260 signal2300 260;
BA_ "NMH-WakeupAllowed" SG_ 260 signal2300 0;
BA_ "NWM-WakeupAllowed" SG_ 260 signal2300 0;
BA_ "GenSigSendType" SG_ 260 signal2300 7;
BA_ "GenSigEnvVarType" SG_ 260 signal2300 0;
BA_ "GenSigAutoGenSnd" SG_ 260 signal2300 1;
BA_ "GenSigAutoGenDsp" SG_ 260 signal2300 1;
BA_ "signal136198" SG_ 260 signal2311 260;
BA_ "signal133356" SG_ 260 signal2311 260;
BA_ "GenSigTimeoutMsg_ecu13120" SG_ 260 signal2311 260;
BA_ "signal131970" SG_ 260 signal2311 260;
BA_ "signal131977" SG_ 260 signal2311 260;
BA_ "GenSigTimeoutMsg_ecu13186" SG_ 260 signal2311 260;
BA_ "NMH-WakeupAllowed" SG_ 260 signal2311 0;
BA_ "NWM-WakeupAllowed" SG_ 260 signal2311 0;
BA_ "GenSigSendType" SG_ 260 signal2311 7;
BA_ "GenSigEnvVarType" SG_ 260 signal2311 0;
BA_ "GenSigAutoGenSnd" SG_ 260 signal2311 1;
BA_ "GenSigAutoGenDsp" SG_ 260 signal2311 1;
BA_ "GenSigTimeoutMsg_ecu13186" SG_ 260 signal2327 260;
BA_ "NMH-WakeupAllowed" SG_ 260 signal2327 0;
BA_ "NWM-WakeupAllowed" SG_ 260 signal2327 0;
BA_ "GenSigStartValue" SG_ 260 signal2327 166;
BA_ "GenSigSendType" SG_ 260 signal2327 7;
BA_ "GenSigEnvVarType" SG_ 260 signal2327 1;
BA_ "GenSigAutoGenSnd" SG_ 260 signal2327 1;
BA_ "GenSigAutoGenDsp" SG_ 260 signal2327 1;
BA_ "GenSigTimeoutMsg_ecu13186" SG_ 260 signal2338 260;
BA_ "NMH-WakeupAllowed" SG_ 260 signal2338 0;
BA_ "NWM-WakeupAllowed" SG_ 260 signal2338 0;
BA_ "GenSigSendType" SG_ 260 signal2338 7;
BA_ "GenSigEnvVarType" SG_ 260 signal2338 0;
BA_ "GenSigAutoGenSnd" SG_ 260 signal2338 1;
BA_ "GenSigAutoGenDsp" SG_ 260 signal2338 1;
BA_ "signal136198" SG_ 260 signal2349 260;
BA_ "signal133356" SG_ 260 signal2349 260;
BA_ "GenSigTimeoutMsg_ecu13120" SG_ 260 signal2349 260;
BA_ "GenSigTimeoutMsg_ecu13186" SG_ 260 signal2349 260;
BA_ "NMH-WakeupAllowed" SG_ 260 signal2349 0;
BA_ "NWM-WakeupAllowed" SG_ 260 signal2349 0;
BA_ "GenSigSendType" SG_ 260 signal2349 7;
BA_ "GenSigEnvVarType" SG_ 260 signal2349 1;
BA_ "GenSigAutoGenSnd" SG_ 260 signal2349 1;
BA_ "GenSigAutoGenDsp" SG_ 260 signal2349 1;
BA_ "GenSigTimeoutMsg_ecu13186" SG_ 260 signal2363 260;
BA_ "NMH-WakeupAllowed" SG_ 260 signal2363 0;
BA_ "NWM-WakeupAllowed" SG_ 260 signal2363 0;
BA_ "GenSigSendType" SG_ 260 signal2363 7;
BA_ "GenSigEnvVarType" SG_ 260 signal2363 0;
BA_ "GenSigAutoGenSnd" SG_ 260 signal2363 1;
BA_ "GenSigAutoGenDsp" SG_ 260 signal2363 1;
BA_ "signal136198" SG_ 260 signal2374 260;
BA_ "signal133356" SG_ 260 signal2374 260;
BA_ "GenSigTimeoutMsg_ecu13120" SG_ 260 signal2374 260;
BA_ "signal131970" SG_ 260 signal2374 260;
BA_ "signal131977" SG_ 260 signal2374 260;
BA_ "GenSigTimeoutMsg_ecu13186" SG_ 260 signal2374 260;
BA_ "NMH-WakeupAllowed" SG_ 260 signal2374 0;
BA_ "NWM-WakeupAllowed" SG_ 260 signal2374 0;
BA_ "GenSigSendType" SG_ 260 signal2374 7;
BA_ "GenSigEnvVarType" SG_ 260 signal2374 0;
BA_ "GenSigAutoGenSnd" SG_ 260 signal2374 1;
BA_ "GenSigAutoGenDsp" SG_ 260 signal2374 1;
BA_ "signal136198" SG_ 260 signal2390 260;
BA_ "signal133356" SG_ 260 signal2390 260;
BA_ "GenSigTimeoutMsg_ecu13120" SG_ 260 signal2390 260;
BA_ "signal131970" SG_ 260 signal2390 260;
BA_ "signal131977" SG_ 260 signal2390 260;
BA_ "GenSigTimeoutMsg_ecu13186" SG_ 260 signal2390 260;
BA_ "NMH-WakeupAllowed" SG_ 260 signal2390 0;
BA_ "NWM-WakeupAllowed" SG_ 260 signal2390 0;
BA_ "GenSigStartValue" SG_ 260 signal2390 1;
BA_ "GenSigSendType" SG_ 260 signal2390 7;
BA_ "GenSigEnvVarType" SG_ 260 signal2390 0;
BA_ "GenSigAutoGenSnd" SG_ 260 signal2390 1;
BA_ "GenSigAutoGenDsp" SG_ 260 signal2390 1;
BA_ "signal131970" SG_ 260 signal2406 260;
BA_ "signal131977" SG_ 260 signal2406 260;
BA_ "GenSigTimeoutMsg_ecu13186" SG_ 260 signal2406 260;
BA_ "NMH-WakeupAllowed" SG_ 260 signal2406 0;
BA_ "NWM-WakeupAllowed" SG_ 260 signal2406 0;
BA_ "GenSigStartValue" SG_ 260 signal2406 30;
BA_ "GenSigSendType" SG_ 260 signal2406 7;
BA_ "GenSigEnvVarType" SG_ 260 signal2406 0;
BA_ "GenSigAutoGenSnd" SG_ 260 signal2406 1;
BA_ "GenSigAutoGenDsp" SG_ 260 signal2406 1;
BA_ "signal136198" SG_ 260 signal2419 260;
BA_ "signal133356" SG_ 260 signal2419 260;
BA_ "GenSigTimeoutMsg_ecu13120" SG_ 260 signal2419 260;
BA_ "signal131970" SG_ 260 signal2419 260;
BA_ "signal131977" SG_ 260 signal2419 260;
BA_ "GenSigTimeoutMsg_ecu13186" SG_ 260 signal2419 260;
BA_ "NMH-WakeupAllowed" SG_ 260 signal2419 0;
BA_ "NWM-WakeupAllowed" SG_ 260 signal2419 0;
BA_ "GenSigSendType" SG_ 260 signal2419 7;
BA_ "GenSigEnvVarType" SG_ 260 signal2419 0;
BA_ "GenSigAutoGenSnd" SG_ 260 signal2419 1;
BA_ "GenSigAutoGenDsp" SG_ 260 signal2419 1;
BA_ "GenSigTimeoutMsg_ecu13186" SG_ 260 signal2435 260;
BA_ "NMH-WakeupAllowed" SG_ 260 signal2435 0;
BA_ "NWM-WakeupAllowed" SG_ 260 signal2435 0;
BA_ "GenSigSendType" SG_ 260 signal2435 7;
BA_ "GenSigEnvVarType" SG_ 260 signal2435 0;
BA_ "GenSigAutoGenSnd" SG_ 260 signal2435 1;
BA_ "GenSigAutoGenDsp" SG_ 260 signal2435 1;
BA_ "GenSigTimeoutMsg_ecu13186" SG_ 781 signal2452 781;
BA_ "NMH-WakeupAllowed" SG_ 781 signal2452 0;
BA_ "NWM-WakeupAllowed" SG_ 781 signal2452 0;
BA_ "GenSigSendType" SG_ 781 signal2452 7;
BA_ "GenSigEnvVarType" SG_ 781 signal2452 0;
BA_ "GenSigAutoGenSnd" SG_ 781 signal2452 1;
BA_ "GenSigAutoGenDsp" SG_ 781 signal2452 1;
BA_ "GenSigTimeoutMsg_ecu13186" SG_ 781 signal2463 781;
BA_ "NMH-WakeupAllowed" SG_ 781 signal2463 0;
BA_ "NWM-WakeupAllowed" SG_ 781 signal2463 0;
BA_ "GenSigSendType" SG_ 781 signal2463 7;
BA_ "GenSigEnvVarType" SG_ 781 signal2463 0;
BA_ "GenSigAutoGenSnd" SG_ 781 signal2463 1;
BA_ "GenSigAutoGenDsp" SG_ 781 signal2463 1;
BA_ "GenSigTimeoutMsg_ecu13186" SG_ 781 signal2474 781;
BA_ "NMH-WakeupAllowed" SG_ 781 signal2474 0;
BA_ "NWM-WakeupAllowed" SG_ 781 signal2474 0;
BA_ "GenSigSendType" SG_ 781 signal2474 7;
BA_ "GenSigEnvVarType" SG_ 781 signal2474 0;
BA_ "GenSigAutoGenSnd" SG_ 781 signal2474 1;
BA_ "GenSigAutoGenDsp" SG_ 781 signal2474 1;
BA_ "GenSigTimeoutMsg_ecu13186" SG_ 781 signal2485 781;
BA_ "NMH-WakeupAllowed" SG_ 781 signal2485 0;
BA_ "NWM-WakeupAllowed" SG_ 781 signal2485 0;
BA_ "GenSigSendType" SG_ 781 signal2485 7;
BA_ "GenSigEnvVarType" SG_ 781 signal2485 0;
BA_ "GenSigAutoGenSnd" SG_ 781 signal2485 1;
BA_ "GenSigAutoGenDsp" SG_ 781 signal2485 1;
BA_ "GenSigTimeoutMsg_ecu13186" SG_ 781 signal2496 781;
BA_ "NMH-WakeupAllowed" SG_ 781 signal2496 0;
BA_ "NWM-WakeupAllowed" SG_ 781 signal2496 0;
BA_ "GenSigSendType" SG_ 781 signal2496 7;
BA_ "GenSigEnvVarType" SG_ 781 signal2496 0;
BA_ "GenSigAutoGenSnd" SG_ 781 signal2496 1;
BA_ "GenSigAutoGenDsp" SG_ 781 signal2496 1;
BA_ "GenSigTimeoutMsg_ecu13186" SG_ 781 signal2507 781;
BA_ "NMH-WakeupAllowed" SG_ 781 signal2507 0;
BA_ "NWM-WakeupAllowed" SG_ 781 signal2507 0;
BA_ "GenSigSendType" SG_ 781 signal2507 7;
BA_ "GenSigEnvVarType" SG_ 781 signal2507 0;
BA_ "GenSigAutoGenSnd" SG_ 781 signal2507 1;
BA_ "GenSigAutoGenDsp" SG_ 781 signal2507 1;
BA_ "signal136198" SG_ 256 signal2524 256;
BA_ "signal133356" SG_ 256 signal2524 256;
BA_ "GenSigTimeoutMsg_ecu13120" SG_ 256 signal2524 256;
BA_ "GenSigTimeoutMsg_ecu11765" SG_ 256 signal2524 256;
BA_ "signal131970" SG_ 256 signal2524 256;
BA_ "signal131977" SG_ 256 signal2524 256;
BA_ "GenSigTimeoutMsg_ecu12594" SG_ 256 signal2524 256;
BA_ "signal142834" SG_ 256 signal2524 256;
BA_ "NMH-WakeupAllowed" SG_ 256 signal2524 0;
BA_ "NWM-WakeupAllowed" SG_ 256 signal2524 0;
BA_ "GenSigSendType" SG_ 256 signal2524 7;
BA_ "GenSigEnvVarType" SG_ 256 signal2524 0;
BA_ "GenSigAutoGenSnd" SG_ 256 signal2524 1;
BA_ "GenSigAutoGenDsp" SG_ 256 signal2524 1;
BA_ "signal136198" SG_ 256 signal2519_BZ 256;
BA_ "signal133356" SG_ 256 signal2519_BZ 256;
BA_ "GenSigTimeoutMsg_ecu13120" SG_ 256 signal2519_BZ 256;
BA_ "GenSigTimeoutMsg_ecu11765" SG_ 256 signal2519_BZ 256;
BA_ "signal131970" SG_ 256 signal2519_BZ 256;
BA_ "signal131977" SG_ 256 signal2519_BZ 256;
BA_ "GenSigTimeoutMsg_ecu12594" SG_ 256 signal2519_BZ 256;
BA_ "signal142834" SG_ 256 signal2519_BZ 256;
BA_ "NMH-WakeupAllowed" SG_ 256 signal2519_BZ 0;
BA_ "NWM-WakeupAllowed" SG_ 256 signal2519_BZ 0;
BA_ "GenSigSendType" SG_ 256 signal2519_BZ 7;
BA_ "GenSigEnvVarType" SG_ 256 signal2519_BZ 0;
BA_ "GenSigAutoGenSnd" SG_ 256 signal2519_BZ 1;
BA_ "GenSigAutoGenDsp" SG_ 256 signal2519_BZ 1;
BA_ "signal136198" SG_ 256 signal2560 256;
BA_ "signal133356" SG_ 256 signal2560 256;
BA_ "GenSigTimeoutMsg_ecu13120" SG_ 256 signal2560 256;
BA_ "signal131970" SG_ 256 signal2560 256;
BA_ "signal131977" SG_ 256 signal2560 256;
BA_ "signal142834" SG_ 256 signal2560 256;
BA_ "NMH-WakeupAllowed" SG_ 256 signal2560 0;
BA_ "NWM-WakeupAllowed" SG_ 256 signal2560 0;
BA_ "GenSigStartValue" SG_ 256 signal2560 1022;
BA_ "GenSigSendType" SG_ 256 signal2560 7;
BA_ "GenSigEnvVarType" SG_ 256 signal2560 0;
BA_ "GenSigAutoGenSnd" SG_ 256 signal2560 1;
BA_ "GenSigAutoGenDsp" SG_ 256 signal2560 1;
BA_ "signal136198" SG_ 256 signal2576 256;
BA_ "signal133356" SG_ 256 signal2576 256;
BA_ "GenSigTimeoutMsg_ecu13120" SG_ 256 signal2576 256;
BA_ "signal131970" SG_ 256 signal2576 256;
BA_ "signal131977" SG_ 256 signal2576 256;
BA_ "signal142834" SG_ 256 signal2576 256;
BA_ "NMH-WakeupAllowed" SG_ 256 signal2576 0;
BA_ "NWM-WakeupAllowed" SG_ 256 signal2576 0;
BA_ "GenSigStartValue" SG_ 256 signal2576 1022;
BA_ "GenSigSendType" SG_ 256 signal2576 7;
BA_ "GenSigEnvVarType" SG_ 256 signal2576 0;
BA_ "GenSigAutoGenSnd" SG_ 256 signal2576 1;
BA_ "GenSigAutoGenDsp" SG_ 256 signal2576 1;
BA_ "signal136198" SG_ 256 signal2592 256;
BA_ "signal133356" SG_ 256 signal2592 256;
BA_ "GenSigTimeoutMsg_ecu13120" SG_ 256 signal2592 256;
BA_ "signal131970" SG_ 256 signal2592 256;
BA_ "signal131977" SG_ 256 signal2592 256;
BA_ "signal142834" SG_ 256 signal2592 256;
BA_ "NMH-WakeupAllowed" SG_ 256 signal2592 0;
BA_ "NWM-WakeupAllowed" SG_ 256 signal2592 0;
BA_ "GenSigStartValue" SG_ 256 signal2592 65534;
BA_ "GenSigSendType" SG_ 256 signal2592 7;
BA_ "GenSigEnvVarType" SG_ 256 signal2592 1;
BA_ "GenSigAutoGenSnd" SG_ 256 signal2592 1;
BA_ "GenSigAutoGenDsp" SG_ 256 signal2592 1;
BA_ "signal136198" SG_ 256 signal2608 256;
BA_ "signal133356" SG_ 256 signal2608 256;
BA_ "GenSigTimeoutMsg_ecu13120" SG_ 256 signal2608 256;
BA_ "GenSigTimeoutMsg_ecu11765" SG_ 256 signal2608 256;
BA_ "signal131970" SG_ 256 signal2608 256;
BA_ "signal131977" SG_ 256 signal2608 256;
BA_ "signal142834" SG_ 256 signal2608 256;
BA_ "NMH-WakeupAllowed" SG_ 256 signal2608 0;
BA_ "NWM-WakeupAllowed" SG_ 256 signal2608 0;
BA_ "GenSigSendType" SG_ 256 signal2608 7;
BA_ "GenSigEnvVarType" SG_ 256 signal2608 0;
BA_ "GenSigAutoGenSnd" SG_ 256 signal2608 1;
BA_ "GenSigAutoGenDsp" SG_ 256 signal2608 1;
BA_ "signal136198" SG_ 256 signal2625 256;
BA_ "signal133356" SG_ 256 signal2625 256;
BA_ "GenSigTimeoutMsg_ecu13120" SG_ 256 signal2625 256;
BA_ "GenSigTimeoutMsg_ecu11765" SG_ 256 signal2625 256;
BA_ "signal131970" SG_ 256 signal2625 256;
BA_ "signal131977" SG_ 256 signal2625 256;
BA_ "signal142834" SG_ 256 signal2625 256;
BA_ "NMH-WakeupAllowed" SG_ 256 signal2625 0;
BA_ "NWM-WakeupAllowed" SG_ 256 signal2625 0;
BA_ "GenSigSendType" SG_ 256 signal2625 7;
BA_ "GenSigEnvVarType" SG_ 256 signal2625 0;
BA_ "GenSigAutoGenSnd" SG_ 256 signal2625 1;
BA_ "GenSigAutoGenDsp" SG_ 256 signal2625 1;
BA_ "signal136198" SG_ 256 signal2642 256;
BA_ "signal133356" SG_ 256 signal2642 256;
BA_ "GenSigTimeoutMsg_ecu13120" SG_ 256 signal2642 256;
BA_ "GenSigTimeoutMsg_ecu12594" SG_ 256 signal2642 256;
BA_ "signal142834" SG_ 256 signal2642 256;
BA_ "NMH-WakeupAllowed" SG_ 256 signal2642 0;
BA_ "NWM-WakeupAllowed" SG_ 256 signal2642 0;
BA_ "GenSigSendType" SG_ 256 signal2642 7;
BA_ "GenSigEnvVarType" SG_ 256 signal2642 0;
BA_ "GenSigAutoGenSnd" SG_ 256 signal2642 1;
BA_ "GenSigAutoGenDsp" SG_ 256 signal2642 1;
BA_ "GenSigTimeoutMsg_ecu11765" SG_ 256 signal2657 256;
BA_ "signal131970" SG_ 256 signal2657 256;
BA_ "signal131977" SG_ 256 signal2657 256;
BA_ "signal142834" SG_ 256 signal2657 256;
BA_ "NMH-WakeupAllowed" SG_ 256 signal2657 0;
BA_ "NWM-WakeupAllowed" SG_ 256 signal2657 0;
BA_ "GenSigSendType" SG_ 256 signal2657 7;
BA_ "GenSigEnvVarType" SG_ 256 signal2657 0;
BA_ "GenSigAutoGenSnd" SG_ 256 signal2657 1;
BA_ "GenSigAutoGenDsp" SG_ 256 signal2657 1;
BA_ "signal136198" SG_ 256 signal2671 256;
BA_ "signal133356" SG_ 256 signal2671 256;
BA_ "GenSigTimeoutMsg_ecu13120" SG_ 256 signal2671 256;
BA_ "NMH-WakeupAllowed" SG_ 256 signal2671 0;
BA_ "NWM-WakeupAllowed" SG_ 256 signal2671 0;
BA_ "GenSigSendType" SG_ 256 signal2671 7;
BA_ "GenSigEnvVarType" SG_ 256 signal2671 0;
BA_ "GenSigAutoGenSnd" SG_ 256 signal2671 1;
BA_ "GenSigAutoGenDsp" SG_ 256 signal2671 1;
BA_ "signal136198" SG_ 256 signal2684 256;
BA_ "signal133356" SG_ 256 signal2684 256;
BA_ "GenSigTimeoutMsg_ecu13120" SG_ 256 signal2684 256;
BA_ "NMH-WakeupAllowed" SG_ 256 signal2684 0;
BA_ "NWM-WakeupAllowed" SG_ 256 signal2684 0;
BA_ "GenSigStartValue" SG_ 256 signal2684 1;
BA_ "GenSigSendType" SG_ 256 signal2684 7;
BA_ "GenSigEnvVarType" SG_ 256 signal2684 0;
BA_ "GenSigAutoGenSnd" SG_ 256 signal2684 1;
BA_ "GenSigAutoGenDsp" SG_ 256 signal2684 1;
BA_ "signal136198" SG_ 256 signal2697 256;
BA_ "signal133356" SG_ 256 signal2697 256;
BA_ "GenSigTimeoutMsg_ecu13120" SG_ 256 signal2697 256;
BA_ "signal131970" SG_ 256 signal2697 256;
BA_ "signal131977" SG_ 256 signal2697 256;
BA_ "signal142834" SG_ 256 signal2697 256;
BA_ "NMH-WakeupAllowed" SG_ 256 signal2697 0;
BA_ "NWM-WakeupAllowed" SG_ 256 signal2697 0;
BA_ "GenSigStartValue" SG_ 256 signal2697 1;
BA_ "GenSigSendType" SG_ 256 signal2697 7;
BA_ "GenSigEnvVarType" SG_ 256 signal2697 0;
BA_ "GenSigAutoGenSnd" SG_ 256 signal2697 1;
BA_ "GenSigAutoGenDsp" SG_ 256 signal2697 1;
BA_ "signal136198" SG_ 256 signal2713 256;
BA_ "signal133356" SG_ 256 signal2713 256;
BA_ "GenSigTimeoutMsg_ecu13120" SG_ 256 signal2713 256;
BA_ "GenSigTimeoutMsg_ecu11765" SG_ 256 signal2713 256;
BA_ "signal131970" SG_ 256 signal2713 256;
BA_ "signal131977" SG_ 256 signal2713 256;
BA_ "GenSigTimeoutMsg_ecu12594" SG_ 256 signal2713 256;
BA_ "signal142834" SG_ 256 signal2713 256;
BA_ "NMH-WakeupAllowed" SG_ 256 signal2713 0;
BA_ "NWM-WakeupAllowed" SG_ 256 signal2713 0;
BA_ "GenSigSendType" SG_ 256 signal2713 7;
BA_ "GenSigEnvVarType" SG_ 256 signal2713 0;
BA_ "GenSigAutoGenSnd" SG_ 256 signal2713 1;
BA_ "GenSigAutoGenDsp" SG_ 256 signal2713 1;
BA_ "signal136198" SG_ 256 signal2731 256;
BA_ "signal133356" SG_ 256 signal2731 256;
BA_ "GenSigTimeoutMsg_ecu13120" SG_ 256 signal2731 256;
BA_ "GenSigTimeoutMsg_ecu11765" SG_ 256 signal2731 256;
BA_ "signal131970" SG_ 256 signal2731 256;
BA_ "signal131977" SG_ 256 signal2731 256;
BA_ "GenSigTimeoutMsg_ecu12594" SG_ 256 signal2731 256;
BA_ "signal142834" SG_ 256 signal2731 256;
BA_ "NMH-WakeupAllowed" SG_ 256 signal2731 0;
BA_ "NWM-WakeupAllowed" SG_ 256 signal2731 0;
BA_ "GenSigSendType" SG_ 256 signal2731 7;
BA_ "GenSigEnvVarType" SG_ 256 signal2731 0;
BA_ "GenSigAutoGenSnd" SG_ 256 signal2731 1;
BA_ "GenSigAutoGenDsp" SG_ 256 signal2731 1;
BA_ "signal136198" SG_ 256 signal2749 256;
BA_ "signal133356" SG_ 256 signal2749 256;
BA_ "GenSigTimeoutMsg_ecu13120" SG_ 256 signal2749 256;
BA_ "GenSigTimeoutMsg_ecu11765" SG_ 256 signal2749 256;
BA_ "GenSigTimeoutMsg_ecu12594" SG_ 256 signal2749 256;
BA_ "signal142834" SG_ 256 signal2749 256;
BA_ "NMH-WakeupAllowed" SG_ 256 signal2749 0;
BA_ "NWM-WakeupAllowed" SG_ 256 signal2749 0;
BA_ "GenSigSendType" SG_ 256 signal2749 7;
BA_ "GenSigEnvVarType" SG_ 256 signal2749 0;
BA_ "GenSigAutoGenSnd" SG_ 256 signal2749 1;
BA_ "GenSigAutoGenDsp" SG_ 256 signal2749 1;
BA_ "signal136198" SG_ 256 signal2765 256;
BA_ "signal133356" SG_ 256 signal2765 256;
BA_ "GenSigTimeoutMsg_ecu13120" SG_ 256 signal2765 256;
BA_ "signal131970" SG_ 256 signal2765 256;
BA_ "signal131977" SG_ 256 signal2765 256;
BA_ "GenSigTimeoutMsg_ecu12594" SG_ 256 signal2765 256;
BA_ "signal142834" SG_ 256 signal2765 256;
BA_ "NMH-WakeupAllowed" SG_ 256 signal2765 0;
BA_ "NWM-WakeupAllowed" SG_ 256 signal2765 0;
BA_ "GenSigSendType" SG_ 256 signal2765 7;
BA_ "GenSigEnvVarType" SG_ 256 signal2765 0;
BA_ "GenSigAutoGenSnd" SG_ 256 signal2765 1;
BA_ "GenSigAutoGenDsp" SG_ 256 signal2765 1;
BA_ "signal136198" SG_ 256 signal2782 256;
BA_ "signal133356" SG_ 256 signal2782 256;
BA_ "GenSigTimeoutMsg_ecu13120" SG_ 256 signal2782 256;
BA_ "GenSigTimeoutMsg_ecu11765" SG_ 256 signal2782 256;
BA_ "signal142834" SG_ 256 signal2782 256;
BA_ "NMH-WakeupAllowed" SG_ 256 signal2782 0;
BA_ "NWM-WakeupAllowed" SG_ 256 signal2782 0;
BA_ "GenSigSendType" SG_ 256 signal2782 7;
BA_ "GenSigEnvVarType" SG_ 256 signal2782 0;
BA_ "GenSigAutoGenSnd" SG_ 256 signal2782 1;
BA_ "GenSigAutoGenDsp" SG_ 256 signal2782 1;
BA_ "signal136198" SG_ 256 signal2797 256;
BA_ "signal133356" SG_ 256 signal2797 256;
BA_ "GenSigTimeoutMsg_ecu13120" SG_ 256 signal2797 256;
BA_ "GenSigTimeoutMsg_ecu11765" SG_ 256 signal2797 256;
BA_ "signal131970" SG_ 256 signal2797 256;
BA_ "signal131977" SG_ 256 signal2797 256;
BA_ "GenSigTimeoutMsg_ecu12594" SG_ 256 signal2797 256;
BA_ "signal142834" SG_ 256 signal2797 256;
BA_ "NMH-WakeupAllowed" SG_ 256 signal2797 0;
BA_ "NWM-WakeupAllowed" SG_ 256 signal2797 0;
BA_ "GenSigSendType" SG_ 256 signal2797 7;
BA_ "GenSigEnvVarType" SG_ 256 signal2797 0;
BA_ "GenSigAutoGenSnd" SG_ 256 signal2797 1;
BA_ "GenSigAutoGenDsp" SG_ 256 signal2797 1;
BA_ "signal136198" SG_ 256 signal2815 256;
BA_ "signal133356" SG_ 256 signal2815 256;
BA_ "GenSigTimeoutMsg_ecu13120" SG_ 256 signal2815 256;
BA_ "NMH-WakeupAllowed" SG_ 256 signal2815 0;
BA_ "NWM-WakeupAllowed" SG_ 256 signal2815 0;
BA_ "GenSigSendType" SG_ 256 signal2815 7;
BA_ "GenSigEnvVarType" SG_ 256 signal2815 0;
BA_ "GenSigAutoGenSnd" SG_ 256 signal2815 1;
BA_ "GenSigAutoGenDsp" SG_ 256 signal2815 1;
BA_ "NMH-WakeupAllowed" SG_ 256 signal2828 0;
BA_ "NWM-WakeupAllowed" SG_ 256 signal2828 0;
BA_ "GenSigSendType" SG_ 256 signal2828 7;
BA_ "GenSigEnvVarType" SG_ 256 signal2828 0;
BA_ "GenSigAutoGenSnd" SG_ 256 signal2828 1;
BA_ "GenSigAutoGenDsp" SG_ 256 signal2828 1;
BA_ "signal136198" SG_ 257 signal2839_CHK 257;
BA_ "signal133356" SG_ 257 signal2839_CHK 257;
BA_ "GenSigTimeoutMsg_ecu13120" SG_ 257 signal2839_CHK 257;
BA_ "GenSigTimeoutMsg_ecu11765" SG_ 257 signal2839_CHK 257;
BA_ "signal131970" SG_ 257 signal2839_CHK 257;
BA_ "signal131977" SG_ 257 signal2839_CHK 257;
BA_ "GenSigTimeoutMsg_ecu12594" SG_ 257 signal2839_CHK 257;
BA_ "NMH-WakeupAllowed" SG_ 257 signal2839_CHK 0;
BA_ "NWM-WakeupAllowed" SG_ 257 signal2839_CHK 0;
BA_ "GenSigSendType" SG_ 257 signal2839_CHK 7;
BA_ "GenSigEnvVarType" SG_ 257 signal2839_CHK 0;
BA_ "GenSigAutoGenSnd" SG_ 257 signal2839_CHK 1;
BA_ "GenSigAutoGenDsp" SG_ 257 signal2839_CHK 1;
BA_ "signal136198" SG_ 257 signal2861 257;
BA_ "signal133356" SG_ 257 signal2861 257;
BA_ "GenSigTimeoutMsg_ecu13120" SG_ 257 signal2861 257;
BA_ "GenSigTimeoutMsg_ecu11765" SG_ 257 signal2861 257;
BA_ "signal131970" SG_ 257 signal2861 257;
BA_ "signal131977" SG_ 257 signal2861 257;
BA_ "GenSigTimeoutMsg_ecu12594" SG_ 257 signal2861 257;
BA_ "NMH-WakeupAllowed" SG_ 257 signal2861 0;
BA_ "NWM-WakeupAllowed" SG_ 257 signal2861 0;
BA_ "GenSigSendType" SG_ 257 signal2861 7;
BA_ "GenSigEnvVarType" SG_ 257 signal2861 0;
BA_ "GenSigAutoGenSnd" SG_ 257 signal2861 1;
BA_ "GenSigAutoGenDsp" SG_ 257 signal2861 1;
BA_ "NMH-WakeupAllowed" SG_ 257 signal2878 0;
BA_ "NWM-WakeupAllowed" SG_ 257 signal2878 0;
BA_ "GenSigStartValue" SG_ 257 signal2878 1;
BA_ "GenSigSendType" SG_ 257 signal2878 7;
BA_ "GenSigEnvVarType" SG_ 257 signal2878 0;
BA_ "GenSigAutoGenSnd" SG_ 257 signal2878 1;
BA_ "GenSigAutoGenDsp" SG_ 257 signal2878 1;
BA_ "signal136198" SG_ 257 signal2888 257;
BA_ "signal133356" SG_ 257 signal2888 257;
BA_ "GenSigTimeoutMsg_ecu13120" SG_ 257 signal2888 257;
BA_ "NMH-WakeupAllowed" SG_ 257 signal2888 0;
BA_ "NWM-WakeupAllowed" SG_ 257 signal2888 0;
BA_ "GenSigStartValue" SG_ 257 signal2888 1;
BA_ "GenSigSendType" SG_ 257 signal2888 7;
BA_ "GenSigEnvVarType" SG_ 257 signal2888 0;
BA_ "GenSigAutoGenSnd" SG_ 257 signal2888 1;
BA_ "GenSigAutoGenDsp" SG_ 257 signal2888 1;
BA_ "signal136198" SG_ 257 signal2901 257;
BA_ "signal133356" SG_ 257 signal2901 257;
BA_ "GenSigTimeoutMsg_ecu13120" SG_ 257 signal2901 257;
BA_ "signal131970" SG_ 257 signal2901 257;
BA_ "signal131977" SG_ 257 signal2901 257;
BA_ "NMH-WakeupAllowed" SG_ 257 signal2901 0;
BA_ "NWM-WakeupAllowed" SG_ 257 signal2901 0;
BA_ "GenSigStartValue" SG_ 257 signal2901 1;
BA_ "GenSigSendType" SG_ 257 signal2901 7;
BA_ "GenSigEnvVarType" SG_ 257 signal2901 0;
BA_ "GenSigAutoGenSnd" SG_ 257 signal2901 1;
BA_ "GenSigAutoGenDsp" SG_ 257 signal2901 1;
BA_ "GenSigTimeoutMsg_ecu12594" SG_ 257 signal2916 257;
BA_ "NMH-WakeupAllowed" SG_ 257 signal2916 0;
BA_ "NWM-WakeupAllowed" SG_ 257 signal2916 0;
BA_ "GenSigSendType" SG_ 257 signal2916 7;
BA_ "GenSigEnvVarType" SG_ 257 signal2916 0;
BA_ "GenSigAutoGenSnd" SG_ 257 signal2916 1;
BA_ "GenSigAutoGenDsp" SG_ 257 signal2916 1;
BA_ "signal136198" SG_ 257 signal2927 257;
BA_ "signal133356" SG_ 257 signal2927 257;
BA_ "GenSigTimeoutMsg_ecu13120" SG_ 257 signal2927 257;
BA_ "GenSigTimeoutMsg_ecu11765" SG_ 257 signal2927 257;
BA_ "signal131970" SG_ 257 signal2927 257;
BA_ "signal131977" SG_ 257 signal2927 257;
BA_ "NMH-WakeupAllowed" SG_ 257 signal2927 0;
BA_ "NWM-WakeupAllowed" SG_ 257 signal2927 0;
BA_ "GenSigStartValue" SG_ 257 signal2927 127;
BA_ "GenSigSendType" SG_ 257 signal2927 7;
BA_ "GenSigEnvVarType" SG_ 257 signal2927 1;
BA_ "GenSigAutoGenSnd" SG_ 257 signal2927 1;
BA_ "GenSigAutoGenDsp" SG_ 257 signal2927 1;
BA_ "signal136198" SG_ 257 signal2943 257;
BA_ "signal133356" SG_ 257 signal2943 257;
BA_ "GenSigTimeoutMsg_ecu13120" SG_ 257 signal2943 257;
BA_ "GenSigTimeoutMsg_ecu11765" SG_ 257 signal2943 257;
BA_ "signal131970" SG_ 257 signal2943 257;
BA_ "signal131977" SG_ 257 signal2943 257;
BA_ "NMH-WakeupAllowed" SG_ 257 signal2943 0;
BA_ "NWM-WakeupAllowed" SG_ 257 signal2943 0;
BA_ "GenSigStartValue" SG_ 257 signal2943 512;
BA_ "GenSigSendType" SG_ 257 signal2943 7;
BA_ "GenSigEnvVarType" SG_ 257 signal2943 1;
BA_ "GenSigAutoGenSnd" SG_ 257 signal2943 1;
BA_ "GenSigAutoGenDsp" SG_ 257 signal2943 1;
BA_ "NMH-WakeupAllowed" SG_ 257 signal2959 0;
BA_ "NWM-WakeupAllowed" SG_ 257 signal2959 0;
BA_ "GenSigStartValue" SG_ 257 signal2959 30;
BA_ "GenSigSendType" SG_ 257 signal2959 7;
BA_ "GenSigEnvVarType" SG_ 257 signal2959 1;
BA_ "GenSigAutoGenSnd" SG_ 257 signal2959 1;
BA_ "GenSigAutoGenDsp" SG_ 257 signal2959 1;
BA_ "NMH-WakeupAllowed" SG_ 257 signal2969 0;
BA_ "NWM-WakeupAllowed" SG_ 257 signal2969 0;
BA_ "GenSigStartValue" SG_ 257 signal2969 1;
BA_ "GenSigSendType" SG_ 257 signal2969 7;
BA_ "GenSigEnvVarType" SG_ 257 signal2969 0;
BA_ "GenSigAutoGenSnd" SG_ 257 signal2969 1;
BA_ "GenSigAutoGenDsp" SG_ 257 signal2969 1;
BA_ "NMH-WakeupAllowed" SG_ 257 signal2979 0;
BA_ "NWM-WakeupAllowed" SG_ 257 signal2979 0;
BA_ "GenSigSendType" SG_ 257 signal2979 7;
BA_ "GenSigEnvVarType" SG_ 257 signal2979 1;
BA_ "GenSigAutoGenSnd" SG_ 257 signal2979 1;
BA_ "GenSigAutoGenDsp" SG_ 257 signal2979 1;
BA_ "NMH-WakeupAllowed" SG_ 257 signal2989 0;
BA_ "NWM-WakeupAllowed" SG_ 257 signal2989 0;
BA_ "GenSigSendType" SG_ 257 signal2989 7;
BA_ "GenSigEnvVarType" SG_ 257 signal2989 0;
BA_ "GenSigAutoGenSnd" SG_ 257 signal2989 1;
BA_ "GenSigAutoGenDsp" SG_ 257 signal2989 1;
BA_ "NMH-WakeupAllowed" SG_ 257 signal2999 0;
BA_ "NWM-WakeupAllowed" SG_ 257 signal2999 0;
BA_ "GenSigSendType" SG_ 257 signal2999 7;
BA_ "GenSigEnvVarType" SG_ 257 signal2999 0;
BA_ "GenSigAutoGenSnd" SG_ 257 signal2999 1;
BA_ "GenSigAutoGenDsp" SG_ 257 signal2999 1;
BA_ "NMH-WakeupAllowed" SG_ 257 signal3009 0;
BA_ "NWM-WakeupAllowed" SG_ 257 signal3009 0;
BA_ "GenSigSendType" SG_ 257 signal3009 7;
BA_ "GenSigEnvVarType" SG_ 257 signal3009 0;
BA_ "GenSigAutoGenSnd" SG_ 257 signal3009 1;
BA_ "GenSigAutoGenDsp" SG_ 257 signal3009 1;
BA_ "signal142820" SG_ 259 signal3025 259;
BA_ "signal142827" SG_ 259 signal3025 259;
BA_ "GenSigTimeoutMsg_ecu11765" SG_ 259 signal3025 259;
BA_ "signal131970" SG_ 259 signal3025 259;
BA_ "signal131977" SG_ 259 signal3025 259;
BA_ "GenSigTimeoutMsg_ecu12594" SG_ 259 signal3025 259;
BA_ "NMH-WakeupAllowed" SG_ 259 signal3025 0;
BA_ "NWM-WakeupAllowed" SG_ 259 signal3025 0;
BA_ "GenSigSendType" SG_ 259 signal3025 7;
BA_ "GenSigEnvVarType" SG_ 259 signal3025 0;
BA_ "GenSigAutoGenSnd" SG_ 259 signal3025 1;
BA_ "GenSigAutoGenDsp" SG_ 259 signal3025 1;
BA_ "signal142820" SG_ 259 signal3041 259;
BA_ "signal142827" SG_ 259 signal3041 259;
BA_ "GenSigTimeoutMsg_ecu11765" SG_ 259 signal3041 259;
BA_ "signal131970" SG_ 259 signal3041 259;
BA_ "signal131977" SG_ 259 signal3041 259;
BA_ "GenSigTimeoutMsg_ecu12594" SG_ 259 signal3041 259;
BA_ "NMH-WakeupAllowed" SG_ 259 signal3041 0;
BA_ "NWM-WakeupAllowed" SG_ 259 signal3041 0;
BA_ "GenSigSendType" SG_ 259 signal3041 7;
BA_ "GenSigEnvVarType" SG_ 259 signal3041 0;
BA_ "GenSigAutoGenSnd" SG_ 259 signal3041 1;
BA_ "GenSigAutoGenDsp" SG_ 259 signal3041 1;
BA_ "signal142820" SG_ 259 signal3057 259;
BA_ "signal131970" SG_ 259 signal3057 259;
BA_ "signal131977" SG_ 259 signal3057 259;
BA_ "GenSigTimeoutMsg_ecu12594" SG_ 259 signal3057 259;
BA_ "NMH-WakeupAllowed" SG_ 259 signal3057 0;
BA_ "NWM-WakeupAllowed" SG_ 259 signal3057 0;
BA_ "GenSigSendType" SG_ 259 signal3057 7;
BA_ "GenSigEnvVarType" SG_ 259 signal3057 0;
BA_ "GenSigAutoGenSnd" SG_ 259 signal3057 1;
BA_ "GenSigAutoGenDsp" SG_ 259 signal3057 1;
BA_ "signal142820" SG_ 259 signal3071 259;
BA_ "signal131970" SG_ 259 signal3071 259;
BA_ "signal131977" SG_ 259 signal3071 259;
BA_ "GenSigTimeoutMsg_ecu12594" SG_ 259 signal3071 259;
BA_ "NMH-WakeupAllowed" SG_ 259 signal3071 0;
BA_ "NWM-WakeupAllowed" SG_ 259 signal3071 0;
BA_ "GenSigSendType" SG_ 259 signal3071 7;
BA_ "GenSigEnvVarType" SG_ 259 signal3071 0;
BA_ "GenSigAutoGenSnd" SG_ 259 signal3071 1;
BA_ "GenSigAutoGenDsp" SG_ 259 signal3071 1;
BA_ "signal142820" SG_ 259 signal3085 259;
BA_ "signal131970" SG_ 259 signal3085 259;
BA_ "signal131977" SG_ 259 signal3085 259;
BA_ "GenSigTimeoutMsg_ecu12594" SG_ 259 signal3085 259;
BA_ "NMH-WakeupAllowed" SG_ 259 signal3085 0;
BA_ "NWM-WakeupAllowed" SG_ 259 signal3085 0;
BA_ "GenSigSendType" SG_ 259 signal3085 7;
BA_ "GenSigEnvVarType" SG_ 259 signal3085 0;
BA_ "GenSigAutoGenSnd" SG_ 259 signal3085 1;
BA_ "GenSigAutoGenDsp" SG_ 259 signal3085 1;
BA_ "signal142820" SG_ 259 signal3099 259;
BA_ "signal131970" SG_ 259 signal3099 259;
BA_ "signal131977" SG_ 259 signal3099 259;
BA_ "GenSigTimeoutMsg_ecu12594" SG_ 259 signal3099 259;
BA_ "NMH-WakeupAllowed" SG_ 259 signal3099 0;
BA_ "NWM-WakeupAllowed" SG_ 259 signal3099 0;
BA_ "GenSigSendType" SG_ 259 signal3099 7;
BA_ "GenSigEnvVarType" SG_ 259 signal3099 0;
BA_ "GenSigAutoGenSnd" SG_ 259 signal3099 1;
BA_ "GenSigAutoGenDsp" SG_ 259 signal3099 1;
BA_ "signal142820" SG_ 259 signal3113 259;
BA_ "signal142827" SG_ 259 signal3113 259;
BA_ "GenSigTimeoutMsg_ecu11765" SG_ 259 signal3113 259;
BA_ "signal131970" SG_ 259 signal3113 259;
BA_ "signal131977" SG_ 259 signal3113 259;
BA_ "GenSigTimeoutMsg_ecu12594" SG_ 259 signal3113 259;
BA_ "NMH-WakeupAllowed" SG_ 259 signal3113 0;
BA_ "NWM-WakeupAllowed" SG_ 259 signal3113 0;
BA_ "GenSigStartValue" SG_ 259 signal3113 4094;
BA_ "GenSigSendType" SG_ 259 signal3113 7;
BA_ "GenSigEnvVarType" SG_ 259 signal3113 1;
BA_ "GenSigAutoGenSnd" SG_ 259 signal3113 1;
BA_ "GenSigAutoGenDsp" SG_ 259 signal3113 1;
BA_ "signal142820" SG_ 259 signal3129 259;
BA_ "signal142827" SG_ 259 signal3129 259;
BA_ "GenSigTimeoutMsg_ecu11765" SG_ 259 signal3129 259;
BA_ "signal131970" SG_ 259 signal3129 259;
BA_ "signal131977" SG_ 259 signal3129 259;
BA_ "GenSigTimeoutMsg_ecu12594" SG_ 259 signal3129 259;
BA_ "NMH-WakeupAllowed" SG_ 259 signal3129 0;
BA_ "NWM-WakeupAllowed" SG_ 259 signal3129 0;
BA_ "GenSigStartValue" SG_ 259 signal3129 4094;
BA_ "GenSigSendType" SG_ 259 signal3129 7;
BA_ "GenSigEnvVarType" SG_ 259 signal3129 1;
BA_ "GenSigAutoGenSnd" SG_ 259 signal3129 1;
BA_ "GenSigAutoGenDsp" SG_ 259 signal3129 1;
BA_ "signal142820" SG_ 259 signal3145 259;
BA_ "signal142827" SG_ 259 signal3145 259;
BA_ "GenSigTimeoutMsg_ecu11765" SG_ 259 signal3145 259;
BA_ "signal131970" SG_ 259 signal3145 259;
BA_ "signal131977" SG_ 259 signal3145 259;
BA_ "GenSigTimeoutMsg_ecu12594" SG_ 259 signal3145 259;
BA_ "NMH-WakeupAllowed" SG_ 259 signal3145 0;
BA_ "NWM-WakeupAllowed" SG_ 259 signal3145 0;
BA_ "GenSigStartValue" SG_ 259 signal3145 4094;
BA_ "GenSigSendType" SG_ 259 signal3145 7;
BA_ "GenSigEnvVarType" SG_ 259 signal3145 1;
BA_ "GenSigAutoGenSnd" SG_ 259 signal3145 1;
BA_ "GenSigAutoGenDsp" SG_ 259 signal3145 1;
BA_ "signal142820" SG_ 259 signal3161 259;
BA_ "signal142827" SG_ 259 signal3161 259;
BA_ "GenSigTimeoutMsg_ecu11765" SG_ 259 signal3161 259;
BA_ "signal131970" SG_ 259 signal3161 259;
BA_ "signal131977" SG_ 259 signal3161 259;
BA_ "GenSigTimeoutMsg_ecu12594" SG_ 259 signal3161 259;
BA_ "NMH-WakeupAllowed" SG_ 259 signal3161 0;
BA_ "NWM-WakeupAllowed" SG_ 259 signal3161 0;
BA_ "GenSigStartValue" SG_ 259 signal3161 4094;
BA_ "GenSigSendType" SG_ 259 signal3161 7;
BA_ "GenSigEnvVarType" SG_ 259 signal3161 1;
BA_ "GenSigAutoGenSnd" SG_ 259 signal3161 1;
BA_ "GenSigAutoGenDsp" SG_ 259 signal3161 1;
BA_ "NMH-WakeupAllowed" SG_ 776 signal3183 0;
BA_ "NWM-WakeupAllowed" SG_ 776 signal3183 0;
BA_ "GenSigStartValue" SG_ 776 signal3183 1;
BA_ "GenSigSendType" SG_ 776 signal3183 7;
BA_ "GenSigEnvVarType" SG_ 776 signal3183 0;
BA_ "GenSigAutoGenSnd" SG_ 776 signal3183 1;
BA_ "GenSigAutoGenDsp" SG_ 776 signal3183 1;
BA_ "NMH-WakeupAllowed" SG_ 776 signal3193 0;
BA_ "NWM-WakeupAllowed" SG_ 776 signal3193 0;
BA_ "GenSigStartValue" SG_ 776 signal3193 1;
BA_ "GenSigSendType" SG_ 776 signal3193 7;
BA_ "GenSigEnvVarType" SG_ 776 signal3193 0;
BA_ "GenSigAutoGenSnd" SG_ 776 signal3193 1;
BA_ "GenSigAutoGenDsp" SG_ 776 signal3193 1;
BA_ "NMH-WakeupAllowed" SG_ 776 signal3203 0;
BA_ "NWM-WakeupAllowed" SG_ 776 signal3203 0;
BA_ "GenSigStartValue" SG_ 776 signal3203 1;
BA_ "GenSigSendType" SG_ 776 signal3203 7;
BA_ "GenSigEnvVarType" SG_ 776 signal3203 0;
BA_ "GenSigAutoGenSnd" SG_ 776 signal3203 1;
BA_ "GenSigAutoGenDsp" SG_ 776 signal3203 1;
BA_ "NMH-WakeupAllowed" SG_ 776 signal3213 0;
BA_ "NWM-WakeupAllowed" SG_ 776 signal3213 0;
BA_ "GenSigSendType" SG_ 776 signal3213 7;
BA_ "GenSigEnvVarType" SG_ 776 signal3213 0;
BA_ "GenSigAutoGenSnd" SG_ 776 signal3213 1;
BA_ "GenSigAutoGenDsp" SG_ 776 signal3213 1;
BA_ "signal142820" SG_ 776 signal3223 776;
BA_ "NMH-WakeupAllowed" SG_ 776 signal3223 0;
BA_ "NWM-WakeupAllowed" SG_ 776 signal3223 0;
BA_ "GenSigSendType" SG_ 776 signal3223 7;
BA_ "GenSigEnvVarType" SG_ 776 signal3223 0;
BA_ "GenSigAutoGenSnd" SG_ 776 signal3223 1;
BA_ "GenSigAutoGenDsp" SG_ 776 signal3223 1;
BA_ "NMH-WakeupAllowed" SG_ 776 signal3234 0;
BA_ "NWM-WakeupAllowed" SG_ 776 signal3234 0;
BA_ "GenSigSendType" SG_ 776 signal3234 7;
BA_ "GenSigEnvVarType" SG_ 776 signal3234 0;
BA_ "GenSigAutoGenSnd" SG_ 776 signal3234 1;
BA_ "GenSigAutoGenDsp" SG_ 776 signal3234 1;
BA_ "NMH-WakeupAllowed" SG_ 776 signal3244 0;
BA_ "NWM-WakeupAllowed" SG_ 776 signal3244 0;
BA_ "GenSigStartValue" SG_ 776 signal3244 32766;
BA_ "GenSigSendType" SG_ 776 signal3244 7;
BA_ "GenSigEnvVarType" SG_ 776 signal3244 1;
BA_ "GenSigAutoGenSnd" SG_ 776 signal3244 1;
BA_ "GenSigAutoGenDsp" SG_ 776 signal3244 1;
BA_ "NMH-WakeupAllowed" SG_ 776 signal3254 0;
BA_ "NWM-WakeupAllowed" SG_ 776 signal3254 0;
BA_ "GenSigSendType" SG_ 776 signal3254 7;
BA_ "GenSigEnvVarType" SG_ 776 signal3254 0;
BA_ "GenSigAutoGenSnd" SG_ 776 signal3254 1;
BA_ "GenSigAutoGenDsp" SG_ 776 signal3254 1;
BA_ "NMH-WakeupAllowed" SG_ 776 signal3264 0;
BA_ "NWM-WakeupAllowed" SG_ 776 signal3264 0;
BA_ "GenSigSendType" SG_ 776 signal3264 7;
BA_ "GenSigEnvVarType" SG_ 776 signal3264 0;
BA_ "GenSigAutoGenSnd" SG_ 776 signal3264 1;
BA_ "GenSigAutoGenDsp" SG_ 776 signal3264 1;
BA_ "NMH-WakeupAllowed" SG_ 776 signal3274 0;
BA_ "NWM-WakeupAllowed" SG_ 776 signal3274 0;
BA_ "GenSigSendType" SG_ 776 signal3274 7;
BA_ "GenSigEnvVarType" SG_ 776 signal3274 0;
BA_ "GenSigAutoGenSnd" SG_ 776 signal3274 1;
BA_ "GenSigAutoGenDsp" SG_ 776 signal3274 1;
BA_ "NMH-WakeupAllowed" SG_ 776 signal3284 0;
BA_ "NWM-WakeupAllowed" SG_ 776 signal3284 0;
BA_ "GenSigStartValue" SG_ 776 signal3284 1;
BA_ "GenSigSendType" SG_ 776 signal3284 7;
BA_ "GenSigEnvVarType" SG_ 776 signal3284 0;
BA_ "GenSigAutoGenSnd" SG_ 776 signal3284 1;
BA_ "GenSigAutoGenDsp" SG_ 776 signal3284 1;
BA_ "NMH-WakeupAllowed" SG_ 776 signal3294 0;
BA_ "NWM-WakeupAllowed" SG_ 776 signal3294 0;
BA_ "GenSigSendType" SG_ 776 signal3294 7;
BA_ "GenSigEnvVarType" SG_ 776 signal3294 0;
BA_ "GenSigAutoGenSnd" SG_ 776 signal3294 1;
BA_ "GenSigAutoGenDsp" SG_ 776 signal3294 1;
BA_ "NMH-WakeupAllowed" SG_ 776 signal3304 0;
BA_ "NWM-WakeupAllowed" SG_ 776 signal3304 0;
BA_ "GenSigStartValue" SG_ 776 signal3304 126;
BA_ "GenSigSendType" SG_ 776 signal3304 7;
BA_ "GenSigEnvVarType" SG_ 776 signal3304 1;
BA_ "GenSigAutoGenSnd" SG_ 776 signal3304 1;
BA_ "GenSigAutoGenDsp" SG_ 776 signal3304 1;
BA_ "NMH-WakeupAllowed" SG_ 776 signal3314 0;
BA_ "NWM-WakeupAllowed" SG_ 776 signal3314 0;
BA_ "GenSigSendType" SG_ 776 signal3314 7;
BA_ "GenSigEnvVarType" SG_ 776 signal3314 0;
BA_ "GenSigAutoGenSnd" SG_ 776 signal3314 1;
BA_ "GenSigAutoGenDsp" SG_ 776 signal3314 1;
BA_ "signal142820" SG_ 262 signal3330 262;
BA_ "signal136198" SG_ 262 signal3330 262;
BA_ "signal133356" SG_ 262 signal3330 262;
BA_ "GenSigTimeoutMsg_ecu13120" SG_ 262 signal3330 262;
BA_ "GenSigTimeoutMsg_ecu11765" SG_ 262 signal3330 262;
BA_ "signal131970" SG_ 262 signal3330 262;
BA_ "signal131977" SG_ 262 signal3330 262;
BA_ "GenSigTimeoutMsg_ecu12594" SG_ 262 signal3330 262;
BA_ "NMH-WakeupAllowed" SG_ 262 signal3330 0;
BA_ "NWM-WakeupAllowed" SG_ 262 signal3330 0;
BA_ "GenSigSendType" SG_ 262 signal3330 7;
BA_ "GenSigEnvVarType" SG_ 262 signal3330 0;
BA_ "GenSigAutoGenSnd" SG_ 262 signal3330 1;
BA_ "GenSigAutoGenDsp" SG_ 262 signal3330 1;
BA_ "signal142820" SG_ 262 signal3348 262;
BA_ "signal136198" SG_ 262 signal3348 262;
BA_ "signal133356" SG_ 262 signal3348 262;
BA_ "GenSigTimeoutMsg_ecu13120" SG_ 262 signal3348 262;
BA_ "GenSigTimeoutMsg_ecu11765" SG_ 262 signal3348 262;
BA_ "signal131970" SG_ 262 signal3348 262;
BA_ "signal131977" SG_ 262 signal3348 262;
BA_ "GenSigTimeoutMsg_ecu12594" SG_ 262 signal3348 262;
BA_ "NMH-WakeupAllowed" SG_ 262 signal3348 0;
BA_ "NWM-WakeupAllowed" SG_ 262 signal3348 0;
BA_ "GenSigSendType" SG_ 262 signal3348 7;
BA_ "GenSigEnvVarType" SG_ 262 signal3348 0;
BA_ "GenSigAutoGenSnd" SG_ 262 signal3348 1;
BA_ "GenSigAutoGenDsp" SG_ 262 signal3348 1;
BA_ "signal136198" SG_ 262 signal3366 262;
BA_ "signal133356" SG_ 262 signal3366 262;
BA_ "GenSigTimeoutMsg_ecu13120" SG_ 262 signal3366 262;
BA_ "signal131970" SG_ 262 signal3366 262;
BA_ "signal131977" SG_ 262 signal3366 262;
BA_ "GenSigTimeoutMsg_ecu12594" SG_ 262 signal3366 262;
BA_ "NMH-WakeupAllowed" SG_ 262 signal3366 0;
BA_ "NWM-WakeupAllowed" SG_ 262 signal3366 0;
BA_ "GenSigStartValue" SG_ 262 signal3366 1;
BA_ "GenSigSendType" SG_ 262 signal3366 7;
BA_ "GenSigEnvVarType" SG_ 262 signal3366 0;
BA_ "GenSigAutoGenSnd" SG_ 262 signal3366 1;
BA_ "GenSigAutoGenDsp" SG_ 262 signal3366 1;
BA_ "signal136198" SG_ 262 signal3382 262;
BA_ "signal133356" SG_ 262 signal3382 262;
BA_ "GenSigTimeoutMsg_ecu13120" SG_ 262 signal3382 262;
BA_ "NMH-WakeupAllowed" SG_ 262 signal3382 0;
BA_ "NWM-WakeupAllowed" SG_ 262 signal3382 0;
BA_ "GenSigStartValue" SG_ 262 signal3382 1;
BA_ "GenSigSendType" SG_ 262 signal3382 7;
BA_ "GenSigEnvVarType" SG_ 262 signal3382 0;
BA_ "GenSigAutoGenSnd" SG_ 262 signal3382 1;
BA_ "GenSigAutoGenDsp" SG_ 262 signal3382 1;
BA_ "NMH-WakeupAllowed" SG_ 262 signal3395 0;
BA_ "NWM-WakeupAllowed" SG_ 262 signal3395 0;
BA_ "GenSigSendType" SG_ 262 signal3395 7;
BA_ "GenSigEnvVarType" SG_ 262 signal3395 0;
BA_ "GenSigAutoGenSnd" SG_ 262 signal3395 1;
BA_ "GenSigAutoGenDsp" SG_ 262 signal3395 1;
BA_ "signal136198" SG_ 262 signal3405 262;
BA_ "signal133356" SG_ 262 signal3405 262;
BA_ "GenSigTimeoutMsg_ecu13120" SG_ 262 signal3405 262;
BA_ "signal131970" SG_ 262 signal3405 262;
BA_ "signal131977" SG_ 262 signal3405 262;
BA_ "GenSigTimeoutMsg_ecu12594" SG_ 262 signal3405 262;
BA_ "NMH-WakeupAllowed" SG_ 262 signal3405 0;
BA_ "NWM-WakeupAllowed" SG_ 262 signal3405 0;
BA_ "GenSigStartValue" SG_ 262 signal3405 100;
BA_ "GenSigSendType" SG_ 262 signal3405 7;
BA_ "GenSigEnvVarType" SG_ 262 signal3405 1;
BA_ "GenSigAutoGenSnd" SG_ 262 signal3405 1;
BA_ "GenSigAutoGenDsp" SG_ 262 signal3405 1;
BA_ "signal136198" SG_ 262 signal3421 262;
BA_ "signal133356" SG_ 262 signal3421 262;
BA_ "GenSigTimeoutMsg_ecu13120" SG_ 262 signal3421 262;
BA_ "NMH-WakeupAllowed" SG_ 262 signal3421 0;
BA_ "NWM-WakeupAllowed" SG_ 262 signal3421 0;
BA_ "GenSigSendType" SG_ 262 signal3421 7;
BA_ "GenSigEnvVarType" SG_ 262 signal3421 0;
BA_ "GenSigAutoGenSnd" SG_ 262 signal3421 1;
BA_ "GenSigAutoGenDsp" SG_ 262 signal3421 1;
BA_ "signal136198" SG_ 262 signal3434 262;
BA_ "signal133356" SG_ 262 signal3434 262;
BA_ "GenSigTimeoutMsg_ecu13120" SG_ 262 signal3434 262;
BA_ "signal131970" SG_ 262 signal3434 262;
BA_ "signal131977" SG_ 262 signal3434 262;
BA_ "NMH-WakeupAllowed" SG_ 262 signal3434 0;
BA_ "NWM-WakeupAllowed" SG_ 262 signal3434 0;
BA_ "GenSigSendType" SG_ 262 signal3434 7;
BA_ "GenSigEnvVarType" SG_ 262 signal3434 0;
BA_ "GenSigAutoGenSnd" SG_ 262 signal3434 1;
BA_ "GenSigAutoGenDsp" SG_ 262 signal3434 1;
BA_ "signal142820" SG_ 262 signal3449 262;
BA_ "NMH-WakeupAllowed" SG_ 262 signal3449 0;
BA_ "NWM-WakeupAllowed" SG_ 262 signal3449 0;
BA_ "GenSigSendType" SG_ 262 signal3449 7;
BA_ "GenSigEnvVarType" SG_ 262 signal3449 0;
BA_ "GenSigAutoGenSnd" SG_ 262 signal3449 1;
BA_ "GenSigAutoGenDsp" SG_ 262 signal3449 1;
BA_ "signal136198" SG_ 262 signal3460 262;
BA_ "signal133356" SG_ 262 signal3460 262;
BA_ "GenSigTimeoutMsg_ecu13120" SG_ 262 signal3460 262;
BA_ "NMH-WakeupAllowed" SG_ 262 signal3460 0;
BA_ "NWM-WakeupAllowed" SG_ 262 signal3460 0;
BA_ "GenSigSendType" SG_ 262 signal3460 7;
BA_ "GenSigEnvVarType" SG_ 262 signal3460 0;
BA_ "GenSigAutoGenSnd" SG_ 262 signal3460 1;
BA_ "GenSigAutoGenDsp" SG_ 262 signal3460 1;
BA_ "NMH-WakeupAllowed" SG_ 262 signal3473 0;
BA_ "NWM-WakeupAllowed" SG_ 262 signal3473 0;
BA_ "GenSigSendType" SG_ 262 signal3473 7;
BA_ "GenSigEnvVarType" SG_ 262 signal3473 0;
BA_ "GenSigAutoGenSnd" SG_ 262 signal3473 1;
BA_ "GenSigAutoGenDsp" SG_ 262 signal3473 1;
BA_ "NMH-WakeupAllowed" SG_ 262 signal3483 0;
BA_ "NWM-WakeupAllowed" SG_ 262 signal3483 0;
BA_ "GenSigSendType" SG_ 262 signal3483 7;
BA_ "GenSigEnvVarType" SG_ 262 signal3483 0;
BA_ "GenSigAutoGenSnd" SG_ 262 signal3483 1;
BA_ "GenSigAutoGenDsp" SG_ 262 signal3483 1;
BA_ "signal136198" SG_ 262 signal3493 262;
BA_ "signal133356" SG_ 262 signal3493 262;
BA_ "GenSigTimeoutMsg_ecu13120" SG_ 262 signal3493 262;
BA_ "NMH-WakeupAllowed" SG_ 262 signal3493 0;
BA_ "NWM-WakeupAllowed" SG_ 262 signal3493 0;
BA_ "GenSigSendType" SG_ 262 signal3493 7;
BA_ "GenSigEnvVarType" SG_ 262 signal3493 0;
BA_ "GenSigAutoGenSnd" SG_ 262 signal3493 1;
BA_ "GenSigAutoGenDsp" SG_ 262 signal3493 1;
BA_ "signal136198" SG_ 262 signal3506 262;
BA_ "signal133356" SG_ 262 signal3506 262;
BA_ "GenSigTimeoutMsg_ecu13120" SG_ 262 signal3506 262;
BA_ "NMH-WakeupAllowed" SG_ 262 signal3506 0;
BA_ "NWM-WakeupAllowed" SG_ 262 signal3506 0;
BA_ "GenSigStartValue" SG_ 262 signal3506 1;
BA_ "GenSigSendType" SG_ 262 signal3506 7;
BA_ "GenSigEnvVarType" SG_ 262 signal3506 0;
BA_ "GenSigAutoGenSnd" SG_ 262 signal3506 1;
BA_ "GenSigAutoGenDsp" SG_ 262 signal3506 1;
BA_ "signal136198" SG_ 262 signal3519 262;
BA_ "signal133356" SG_ 262 signal3519 262;
BA_ "GenSigTimeoutMsg_ecu13120" SG_ 262 signal3519 262;
BA_ "NMH-WakeupAllowed" SG_ 262 signal3519 0;
BA_ "NWM-WakeupAllowed" SG_ 262 signal3519 0;
BA_ "GenSigSendType" SG_ 262 signal3519 7;
BA_ "GenSigEnvVarType" SG_ 262 signal3519 0;
BA_ "GenSigAutoGenSnd" SG_ 262 signal3519 1;
BA_ "GenSigAutoGenDsp" SG_ 262 signal3519 1;
BA_ "GenSigTimeoutMsg_ecu12594" SG_ 262 signal3532 262;
BA_ "NMH-WakeupAllowed" SG_ 262 signal3532 0;
BA_ "NWM-WakeupAllowed" SG_ 262 signal3532 0;
BA_ "GenSigSendType" SG_ 262 signal3532 7;
BA_ "GenSigEnvVarType" SG_ 262 signal3532 0;
BA_ "GenSigAutoGenSnd" SG_ 262 signal3532 1;
BA_ "GenSigAutoGenDsp" SG_ 262 signal3532 1;
BA_ "signal136198" SG_ 262 signal3543 262;
BA_ "signal133356" SG_ 262 signal3543 262;
BA_ "GenSigTimeoutMsg_ecu13120" SG_ 262 signal3543 262;
BA_ "NMH-WakeupAllowed" SG_ 262 signal3543 0;
BA_ "NWM-WakeupAllowed" SG_ 262 signal3543 0;
BA_ "GenSigSendType" SG_ 262 signal3543 7;
BA_ "GenSigEnvVarType" SG_ 262 signal3543 0;
BA_ "GenSigAutoGenSnd" SG_ 262 signal3543 1;
BA_ "GenSigAutoGenDsp" SG_ 262 signal3543 1;
BA_ "NMH-WakeupAllowed" SG_ 262 signal3556 0;
BA_ "NWM-WakeupAllowed" SG_ 262 signal3556 0;
BA_ "GenSigSendType" SG_ 262 signal3556 7;
BA_ "GenSigEnvVarType" SG_ 262 signal3556 0;
BA_ "GenSigAutoGenSnd" SG_ 262 signal3556 1;
BA_ "GenSigAutoGenDsp" SG_ 262 signal3556 1;
BA_ "NMH-WakeupAllowed" SG_ 262 signal3566 0;
BA_ "NWM-WakeupAllowed" SG_ 262 signal3566 0;
BA_ "GenSigSendType" SG_ 262 signal3566 7;
BA_ "GenSigEnvVarType" SG_ 262 signal3566 0;
BA_ "GenSigAutoGenSnd" SG_ 262 signal3566 1;
BA_ "GenSigAutoGenDsp" SG_ 262 signal3566 1;
BA_ "NMH-WakeupAllowed" SG_ 262 signal3576 0;
BA_ "NWM-WakeupAllowed" SG_ 262 signal3576 0;
BA_ "GenSigSendType" SG_ 262 signal3576 7;
BA_ "GenSigEnvVarType" SG_ 262 signal3576 0;
BA_ "GenSigAutoGenSnd" SG_ 262 signal3576 1;
BA_ "GenSigAutoGenDsp" SG_ 262 signal3576 1;
BA_ "NMH-WakeupAllowed" SG_ 262 signal3586 0;
BA_ "NWM-WakeupAllowed" SG_ 262 signal3586 0;
BA_ "GenSigSendType" SG_ 262 signal3586 7;
BA_ "GenSigEnvVarType" SG_ 262 signal3586 0;
BA_ "GenSigAutoGenSnd" SG_ 262 signal3586 1;
BA_ "GenSigAutoGenDsp" SG_ 262 signal3586 1;
BA_ "NMH-WakeupAllowed" SG_ 262 signal3596 0;
BA_ "NWM-WakeupAllowed" SG_ 262 signal3596 0;
BA_ "GenSigSendType" SG_ 262 signal3596 7;
BA_ "GenSigEnvVarType" SG_ 262 signal3596 0;
BA_ "GenSigAutoGenSnd" SG_ 262 signal3596 1;
BA_ "GenSigAutoGenDsp" SG_ 262 signal3596 1;
BA_ "GenSigTimeoutMsg_ecu11765" SG_ 262 signal3606 262;
BA_ "GenSigTimeoutMsg_ecu12594" SG_ 262 signal3606 262;
BA_ "NMH-WakeupAllowed" SG_ 262 signal3606 0;
BA_ "NWM-WakeupAllowed" SG_ 262 signal3606 0;
BA_ "GenSigSendType" SG_ 262 signal3606 7;
BA_ "GenSigEnvVarType" SG_ 262 signal3606 0;
BA_ "GenSigAutoGenSnd" SG_ 262 signal3606 1;
BA_ "GenSigAutoGenDsp" SG_ 262 signal3606 1;
BA_ "GenSigTimeoutMsg_ecu12594" SG_ 262 signal3618 262;
BA_ "NMH-WakeupAllowed" SG_ 262 signal3618 0;
BA_ "NWM-WakeupAllowed" SG_ 262 signal3618 0;
BA_ "GenSigSendType" SG_ 262 signal3618 7;
BA_ "GenSigEnvVarType" SG_ 262 signal3618 0;
BA_ "GenSigAutoGenSnd" SG_ 262 signal3618 1;
BA_ "GenSigAutoGenDsp" SG_ 262 signal3618 1;
BA_ "signal131970" SG_ 262 signal3629 262;
BA_ "signal131977" SG_ 262 signal3629 262;
BA_ "GenSigTimeoutMsg_ecu12594" SG_ 262 signal3629 262;
BA_ "NMH-WakeupAllowed" SG_ 262 signal3629 0;
BA_ "NWM-WakeupAllowed" SG_ 262 signal3629 0;
BA_ "GenSigSendType" SG_ 262 signal3629 7;
BA_ "GenSigEnvVarType" SG_ 262 signal3629 0;
BA_ "GenSigAutoGenSnd" SG_ 262 signal3629 1;
BA_ "GenSigAutoGenDsp" SG_ 262 signal3629 1;
BA_ "signal136198" SG_ 262 signal3642 262;
BA_ "signal133356" SG_ 262 signal3642 262;
BA_ "GenSigTimeoutMsg_ecu13120" SG_ 262 signal3642 262;
BA_ "NMH-WakeupAllowed" SG_ 262 signal3642 0;
BA_ "NWM-WakeupAllowed" SG_ 262 signal3642 0;
BA_ "GenSigSendType" SG_ 262 signal3642 7;
BA_ "GenSigEnvVarType" SG_ 262 signal3642 0;
BA_ "GenSigAutoGenSnd" SG_ 262 signal3642 1;
BA_ "GenSigAutoGenDsp" SG_ 262 signal3642 1;
BA_ "GenSigTimeoutMsg_ecu12594" SG_ 262 signal3655 262;
BA_ "NMH-WakeupAllowed" SG_ 262 signal3655 0;
BA_ "NWM-WakeupAllowed" SG_ 262 signal3655 0;
BA_ "GenSigSendType" SG_ 262 signal3655 7;
BA_ "GenSigEnvVarType" SG_ 262 signal3655 0;
BA_ "GenSigAutoGenSnd" SG_ 262 signal3655 1;
BA_ "GenSigAutoGenDsp" SG_ 262 signal3655 1;
BA_ "signal136198" SG_ 262 signal3666 262;
BA_ "signal133356" SG_ 262 signal3666 262;
BA_ "GenSigTimeoutMsg_ecu13120" SG_ 262 signal3666 262;
BA_ "GenSigTimeoutMsg_ecu12594" SG_ 262 signal3666 262;
BA_ "NMH-WakeupAllowed" SG_ 262 signal3666 0;
BA_ "NWM-WakeupAllowed" SG_ 262 signal3666 0;
BA_ "GenSigSendType" SG_ 262 signal3666 7;
BA_ "GenSigEnvVarType" SG_ 262 signal3666 0;
BA_ "GenSigAutoGenSnd" SG_ 262 signal3666 1;
BA_ "GenSigAutoGenDsp" SG_ 262 signal3666 1;
BA_ "GenSigTimeoutMsg_ecu12594" SG_ 262 signal3680 262;
BA_ "NMH-WakeupAllowed" SG_ 262 signal3680 0;
BA_ "NWM-WakeupAllowed" SG_ 262 signal3680 0;
BA_ "GenSigSendType" SG_ 262 signal3680 7;
BA_ "GenSigEnvVarType" SG_ 262 signal3680 0;
BA_ "GenSigAutoGenSnd" SG_ 262 signal3680 1;
BA_ "GenSigAutoGenDsp" SG_ 262 signal3680 1;
BA_ "signal142820" SG_ 132 signal3692_CHK 132;
BA_ "NMH-WakeupAllowed" SG_ 132 signal3692_CHK 0;
BA_ "NWM-WakeupAllowed" SG_ 132 signal3692_CHK 0;
BA_ "GenSigSendType" SG_ 132 signal3692_CHK 7;
BA_ "GenSigEnvVarType" SG_ 132 signal3692_CHK 0;
BA_ "GenSigAutoGenSnd" SG_ 132 signal3692_CHK 1;
BA_ "GenSigAutoGenDsp" SG_ 132 signal3692_CHK 1;
BA_ "signal142820" SG_ 132 signal3708 132;
BA_ "NMH-WakeupAllowed" SG_ 132 signal3708 0;
BA_ "NWM-WakeupAllowed" SG_ 132 signal3708 0;
BA_ "GenSigSendType" SG_ 132 signal3708 7;
BA_ "GenSigEnvVarType" SG_ 132 signal3708 0;
BA_ "GenSigAutoGenSnd" SG_ 132 signal3708 1;
BA_ "GenSigAutoGenDsp" SG_ 132 signal3708 1;
BA_ "signal142820" SG_ 132 signal3719 132;
BA_ "NMH-WakeupAllowed" SG_ 132 signal3719 0;
BA_ "NWM-WakeupAllowed" SG_ 132 signal3719 0;
BA_ "GenSigSendType" SG_ 132 signal3719 7;
BA_ "GenSigEnvVarType" SG_ 132 signal3719 1;
BA_ "GenSigAutoGenSnd" SG_ 132 signal3719 1;
BA_ "GenSigAutoGenDsp" SG_ 132 signal3719 1;
BA_ "signal142820" SG_ 132 signal3730 132;
BA_ "NMH-WakeupAllowed" SG_ 132 signal3730 0;
BA_ "NWM-WakeupAllowed" SG_ 132 signal3730 0;
BA_ "GenSigSendType" SG_ 132 signal3730 7;
BA_ "GenSigEnvVarType" SG_ 132 signal3730 0;
BA_ "GenSigAutoGenSnd" SG_ 132 signal3730 1;
BA_ "GenSigAutoGenDsp" SG_ 132 signal3730 1;
BA_ "signal142820" SG_ 132 signal3741 132;
BA_ "NMH-WakeupAllowed" SG_ 132 signal3741 0;
BA_ "NWM-WakeupAllowed" SG_ 132 signal3741 0;
BA_ "GenSigSendType" SG_ 132 signal3741 7;
BA_ "GenSigEnvVarType" SG_ 132 signal3741 0;
BA_ "GenSigAutoGenSnd" SG_ 132 signal3741 1;
BA_ "GenSigAutoGenDsp" SG_ 132 signal3741 1;
BA_ "signal142820" SG_ 132 signal3752 132;
BA_ "NMH-WakeupAllowed" SG_ 132 signal3752 0;
BA_ "NWM-WakeupAllowed" SG_ 132 signal3752 0;
BA_ "GenSigStartValue" SG_ 132 signal3752 1;
BA_ "GenSigSendType" SG_ 132 signal3752 7;
BA_ "GenSigEnvVarType" SG_ 132 signal3752 0;
BA_ "GenSigAutoGenSnd" SG_ 132 signal3752 1;
BA_ "GenSigAutoGenDsp" SG_ 132 signal3752 1;
BA_ "signal142820" SG_ 132 signal3763 132;
BA_ "NMH-WakeupAllowed" SG_ 132 signal3763 0;
BA_ "NWM-WakeupAllowed" SG_ 132 signal3763 0;
BA_ "GenSigSendType" SG_ 132 signal3763 7;
BA_ "GenSigEnvVarType" SG_ 132 signal3763 0;
BA_ "GenSigAutoGenSnd" SG_ 132 signal3763 1;
BA_ "GenSigAutoGenDsp" SG_ 132 signal3763 1;
BA_ "signal142820" SG_ 132 signal3774 132;
BA_ "NMH-WakeupAllowed" SG_ 132 signal3774 0;
BA_ "NWM-WakeupAllowed" SG_ 132 signal3774 0;
BA_ "GenSigSendType" SG_ 132 signal3774 7;
BA_ "GenSigEnvVarType" SG_ 132 signal3774 0;
BA_ "GenSigAutoGenSnd" SG_ 132 signal3774 1;
BA_ "GenSigAutoGenDsp" SG_ 132 signal3774 1;
BA_ "signal142820" SG_ 132 signal3785 132;
BA_ "NMH-WakeupAllowed" SG_ 132 signal3785 0;
BA_ "NWM-WakeupAllowed" SG_ 132 signal3785 0;
BA_ "GenSigSendType" SG_ 132 signal3785 7;
BA_ "GenSigEnvVarType" SG_ 132 signal3785 0;
BA_ "GenSigAutoGenSnd" SG_ 132 signal3785 1;
BA_ "GenSigAutoGenDsp" SG_ 132 signal3785 1;
BA_ "signal142820" SG_ 132 signal3796 132;
BA_ "NMH-WakeupAllowed" SG_ 132 signal3796 0;
BA_ "NWM-WakeupAllowed" SG_ 132 signal3796 0;
BA_ "GenSigSendType" SG_ 132 signal3796 7;
BA_ "GenSigEnvVarType" SG_ 132 signal3796 0;
BA_ "GenSigAutoGenSnd" SG_ 132 signal3796 1;
BA_ "GenSigAutoGenDsp" SG_ 132 signal3796 1;
BA_ "signal142827" SG_ 914 signal3813 914;
BA_ "NMH-WakeupAllowed" SG_ 914 signal3813 0;
BA_ "NWM-WakeupAllowed" SG_ 914 signal3813 0;
BA_ "GenSigSendType" SG_ 914 signal3813 7;
BA_ "GenSigEnvVarType" SG_ 914 signal3813 0;
BA_ "GenSigAutoGenSnd" SG_ 914 signal3813 1;
BA_ "GenSigAutoGenDsp" SG_ 914 signal3813 1;
BA_ "signal142827" SG_ 914 signal3824 914;
BA_ "NMH-WakeupAllowed" SG_ 914 signal3824 0;
BA_ "NWM-WakeupAllowed" SG_ 914 signal3824 0;
BA_ "GenSigSendType" SG_ 914 signal3824 7;
BA_ "GenSigEnvVarType" SG_ 914 signal3824 0;
BA_ "GenSigAutoGenSnd" SG_ 914 signal3824 1;
BA_ "GenSigAutoGenDsp" SG_ 914 signal3824 1;
BA_ "NMH-WakeupAllowed" SG_ 914 signal3835 0;
BA_ "NWM-WakeupAllowed" SG_ 914 signal3835 0;
BA_ "GenSigSendType" SG_ 914 signal3835 7;
BA_ "GenSigEnvVarType" SG_ 914 signal3835 0;
BA_ "GenSigAutoGenSnd" SG_ 914 signal3835 1;
BA_ "GenSigAutoGenDsp" SG_ 914 signal3835 1;
BA_ "signal142827" SG_ 914 signal3845 914;
BA_ "NMH-WakeupAllowed" SG_ 914 signal3845 0;
BA_ "NWM-WakeupAllowed" SG_ 914 signal3845 0;
BA_ "GenSigSendType" SG_ 914 signal3845 7;
BA_ "GenSigEnvVarType" SG_ 914 signal3845 0;
BA_ "GenSigAutoGenSnd" SG_ 914 signal3845 1;
BA_ "GenSigAutoGenDsp" SG_ 914 signal3845 1;
BA_ "NMH-WakeupAllowed" SG_ 914 signal3856 0;
BA_ "NWM-WakeupAllowed" SG_ 914 signal3856 0;
BA_ "GenSigStartValue" SG_ 914 signal3856 254;
BA_ "GenSigSendType" SG_ 914 signal3856 7;
BA_ "GenSigEnvVarType" SG_ 914 signal3856 1;
BA_ "GenSigAutoGenSnd" SG_ 914 signal3856 1;
BA_ "GenSigAutoGenDsp" SG_ 914 signal3856 1;
BA_ "NMH-WakeupAllowed" SG_ 914 signal3866 0;
BA_ "NWM-WakeupAllowed" SG_ 914 signal3866 0;
BA_ "GenSigStartValue" SG_ 914 signal3866 254;
BA_ "GenSigSendType" SG_ 914 signal3866 7;
BA_ "GenSigEnvVarType" SG_ 914 signal3866 1;
BA_ "GenSigAutoGenSnd" SG_ 914 signal3866 1;
BA_ "GenSigAutoGenDsp" SG_ 914 signal3866 1;
BA_ "NMH-WakeupAllowed" SG_ 914 signal3876 0;
BA_ "NWM-WakeupAllowed" SG_ 914 signal3876 0;
BA_ "GenSigStartValue" SG_ 914 signal3876 254;
BA_ "GenSigSendType" SG_ 914 signal3876 7;
BA_ "GenSigEnvVarType" SG_ 914 signal3876 1;
BA_ "GenSigAutoGenSnd" SG_ 914 signal3876 1;
BA_ "GenSigAutoGenDsp" SG_ 914 signal3876 1;
BA_ "signal136198" SG_ 924 signal3892 924;
BA_ "signal133356" SG_ 924 signal3892 924;
BA_ "GenSigTimeoutMsg_ecu13120" SG_ 924 signal3892 924;
BA_ "GenSigTimeoutMsg_ecu12594" SG_ 924 signal3892 924;
BA_ "NMH-WakeupAllowed" SG_ 924 signal3892 0;
BA_ "NWM-WakeupAllowed" SG_ 924 signal3892 0;
BA_ "GenSigStartValue" SG_ 924 signal3892 1;
BA_ "GenSigSendType" SG_ 924 signal3892 7;
BA_ "GenSigEnvVarType" SG_ 924 signal3892 0;
BA_ "GenSigAutoGenSnd" SG_ 924 signal3892 1;
BA_ "GenSigAutoGenDsp" SG_ 924 signal3892 1;
BA_ "GenSigTimeoutMsg_ecu13120" SG_ 924 signal3906 924;
BA_ "NMH-WakeupAllowed" SG_ 924 signal3906 0;
BA_ "NWM-WakeupAllowed" SG_ 924 signal3906 0;
BA_ "GenSigStartValue" SG_ 924 signal3906 1;
BA_ "GenSigSendType" SG_ 924 signal3906 7;
BA_ "GenSigEnvVarType" SG_ 924 signal3906 0;
BA_ "GenSigAutoGenSnd" SG_ 924 signal3906 1;
BA_ "GenSigAutoGenDsp" SG_ 924 signal3906 1;
BA_ "GenSigTimeoutMsg_ecu12990" SG_ 924 signal3917 924;
BA_ "NMH-WakeupAllowed" SG_ 924 signal3917 0;
BA_ "NWM-WakeupAllowed" SG_ 924 signal3917 0;
BA_ "GenSigStartValue" SG_ 924 signal3917 1;
BA_ "GenSigSendType" SG_ 924 signal3917 7;
BA_ "GenSigEnvVarType" SG_ 924 signal3917 0;
BA_ "GenSigAutoGenSnd" SG_ 924 signal3917 1;
BA_ "GenSigAutoGenDsp" SG_ 924 signal3917 1;
BA_ "signal136198" SG_ 924 signal3928 924;
BA_ "signal133356" SG_ 924 signal3928 924;
BA_ "GenSigTimeoutMsg_ecu13120" SG_ 924 signal3928 924;
BA_ "GenSigTimeoutMsg_ecu12594" SG_ 924 signal3928 924;
BA_ "NMH-WakeupAllowed" SG_ 924 signal3928 0;
BA_ "NWM-WakeupAllowed" SG_ 924 signal3928 0;
BA_ "GenSigStartValue" SG_ 924 signal3928 1;
BA_ "GenSigSendType" SG_ 924 signal3928 7;
BA_ "GenSigEnvVarType" SG_ 924 signal3928 0;
BA_ "GenSigAutoGenSnd" SG_ 924 signal3928 1;
BA_ "GenSigAutoGenDsp" SG_ 924 signal3928 1;
BA_ "signal136198" SG_ 924 signal3942 924;
BA_ "signal133356" SG_ 924 signal3942 924;
BA_ "GenSigTimeoutMsg_ecu13120" SG_ 924 signal3942 924;
BA_ "NMH-WakeupAllowed" SG_ 924 signal3942 0;
BA_ "NWM-WakeupAllowed" SG_ 924 signal3942 0;
BA_ "GenSigStartValue" SG_ 924 signal3942 1;
BA_ "GenSigSendType" SG_ 924 signal3942 7;
BA_ "GenSigEnvVarType" SG_ 924 signal3942 0;
BA_ "GenSigAutoGenSnd" SG_ 924 signal3942 1;
BA_ "GenSigAutoGenDsp" SG_ 924 signal3942 1;
BA_ "NMH-WakeupAllowed" SG_ 924 signal3955 0;
BA_ "NWM-WakeupAllowed" SG_ 924 signal3955 0;
BA_ "GenSigStartValue" SG_ 924 signal3955 1;
BA_ "GenSigSendType" SG_ 924 signal3955 7;
BA_ "GenSigEnvVarType" SG_ 924 signal3955 0;
BA_ "GenSigAutoGenSnd" SG_ 924 signal3955 1;
BA_ "GenSigAutoGenDsp" SG_ 924 signal3955 1;
BA_ "NMH-WakeupAllowed" SG_ 924 signal3965 0;
BA_ "NWM-WakeupAllowed" SG_ 924 signal3965 0;
BA_ "GenSigStartValue" SG_ 924 signal3965 1;
BA_ "GenSigSendType" SG_ 924 signal3965 7;
BA_ "GenSigEnvVarType" SG_ 924 signal3965 0;
BA_ "GenSigAutoGenSnd" SG_ 924 signal3965 1;
BA_ "GenSigAutoGenDsp" SG_ 924 signal3965 1;
BA_ "NMH-WakeupAllowed" SG_ 924 signal3975 0;
BA_ "NWM-WakeupAllowed" SG_ 924 signal3975 0;
BA_ "GenSigStartValue" SG_ 924 signal3975 1;
BA_ "GenSigSendType" SG_ 924 signal3975 7;
BA_ "GenSigEnvVarType" SG_ 924 signal3975 0;
BA_ "GenSigAutoGenSnd" SG_ 924 signal3975 1;
BA_ "GenSigAutoGenDsp" SG_ 924 signal3975 1;
BA_ "NMH-WakeupAllowed" SG_ 924 signal3985 0;
BA_ "NWM-WakeupAllowed" SG_ 924 signal3985 0;
BA_ "GenSigStartValue" SG_ 924 signal3985 1;
BA_ "GenSigSendType" SG_ 924 signal3985 7;
BA_ "GenSigEnvVarType" SG_ 924 signal3985 0;
BA_ "GenSigAutoGenSnd" SG_ 924 signal3985 1;
BA_ "GenSigAutoGenDsp" SG_ 924 signal3985 1;
BA_ "signal136198" SG_ 924 signal3995 924;
BA_ "signal133356" SG_ 924 signal3995 924;
BA_ "GenSigTimeoutMsg_ecu13120" SG_ 924 signal3995 924;
BA_ "NMH-WakeupAllowed" SG_ 924 signal3995 0;
BA_ "NWM-WakeupAllowed" SG_ 924 signal3995 0;
BA_ "GenSigStartValue" SG_ 924 signal3995 1;
BA_ "GenSigSendType" SG_ 924 signal3995 7;
BA_ "GenSigEnvVarType" SG_ 924 signal3995 0;
BA_ "GenSigAutoGenSnd" SG_ 924 signal3995 1;
BA_ "GenSigAutoGenDsp" SG_ 924 signal3995 1;
BA_ "signal136198" SG_ 924 signal4008 924;
BA_ "signal133356" SG_ 924 signal4008 924;
BA_ "GenSigTimeoutMsg_ecu13120" SG_ 924 signal4008 924;
BA_ "NMH-WakeupAllowed" SG_ 924 signal4008 0;
BA_ "NWM-WakeupAllowed" SG_ 924 signal4008 0;
BA_ "GenSigStartValue" SG_ 924 signal4008 1;
BA_ "GenSigSendType" SG_ 924 signal4008 7;
BA_ "GenSigEnvVarType" SG_ 924 signal4008 0;
BA_ "GenSigAutoGenSnd" SG_ 924 signal4008 1;
BA_ "GenSigAutoGenDsp" SG_ 924 signal4008 1;
BA_ "GenSigTimeoutMsg_ecu12990" SG_ 924 signal7888_alt 924;
BA_ "NMH-WakeupAllowed" SG_ 924 signal7888_alt 0;
BA_ "NWM-WakeupAllowed" SG_ 924 signal7888_alt 0;
BA_ "GenSigStartValue" SG_ 924 signal7888_alt 1;
BA_ "GenSigSendType" SG_ 924 signal7888_alt 7;
BA_ "GenSigEnvVarType" SG_ 924 signal7888_alt 0;
BA_ "GenSigAutoGenSnd" SG_ 924 signal7888_alt 1;
BA_ "GenSigAutoGenDsp" SG_ 924 signal7888_alt 1;
BA_ "NMH-WakeupAllowed" SG_ 924 signal4032 0;
BA_ "NWM-WakeupAllowed" SG_ 924 signal4032 0;
BA_ "GenSigStartValue" SG_ 924 signal4032 1;
BA_ "GenSigSendType" SG_ 924 signal4032 7;
BA_ "GenSigEnvVarType" SG_ 924 signal4032 0;
BA_ "GenSigAutoGenSnd" SG_ 924 signal4032 1;
BA_ "GenSigAutoGenDsp" SG_ 924 signal4032 1;
BA_ "NMH-WakeupAllowed" SG_ 924 signal4042 0;
BA_ "NWM-WakeupAllowed" SG_ 924 signal4042 0;
BA_ "GenSigStartValue" SG_ 924 signal4042 1;
BA_ "GenSigSendType" SG_ 924 signal4042 7;
BA_ "GenSigEnvVarType" SG_ 924 signal4042 0;
BA_ "GenSigAutoGenSnd" SG_ 924 signal4042 1;
BA_ "GenSigAutoGenDsp" SG_ 924 signal4042 1;
BA_ "NMH-WakeupAllowed" SG_ 924 signal4052 0;
BA_ "NWM-WakeupAllowed" SG_ 924 signal4052 0;
BA_ "GenSigStartValue" SG_ 924 signal4052 1;
BA_ "GenSigSendType" SG_ 924 signal4052 7;
BA_ "GenSigEnvVarType" SG_ 924 signal4052 0;
BA_ "GenSigAutoGenSnd" SG_ 924 signal4052 1;
BA_ "GenSigAutoGenDsp" SG_ 924 signal4052 1;
BA_ "NMH-WakeupAllowed" SG_ 924 signal4062 0;
BA_ "NWM-WakeupAllowed" SG_ 924 signal4062 0;
BA_ "GenSigStartValue" SG_ 924 signal4062 1;
BA_ "GenSigSendType" SG_ 924 signal4062 7;
BA_ "GenSigEnvVarType" SG_ 924 signal4062 0;
BA_ "GenSigAutoGenSnd" SG_ 924 signal4062 1;
BA_ "GenSigAutoGenDsp" SG_ 924 signal4062 1;
BA_ "signal136198" SG_ 924 signal4072 924;
BA_ "signal133356" SG_ 924 signal4072 924;
BA_ "GenSigTimeoutMsg_ecu13120" SG_ 924 signal4072 924;
BA_ "NMH-WakeupAllowed" SG_ 924 signal4072 0;
BA_ "NWM-WakeupAllowed" SG_ 924 signal4072 0;
BA_ "GenSigSendType" SG_ 924 signal4072 3;
BA_ "GenSigEnvVarType" SG_ 924 signal4072 0;
BA_ "GenSigAutoGenSnd" SG_ 924 signal4072 1;
BA_ "GenSigAutoGenDsp" SG_ 924 signal4072 1;
BA_ "GenSigTimeoutMsg_ecu13120" SG_ 924 signal4085 924;
BA_ "NMH-WakeupAllowed" SG_ 924 signal4085 0;
BA_ "NWM-WakeupAllowed" SG_ 924 signal4085 0;
BA_ "GenSigSendType" SG_ 924 signal4085 3;
BA_ "GenSigEnvVarType" SG_ 924 signal4085 0;
BA_ "GenSigAutoGenSnd" SG_ 924 signal4085 1;
BA_ "GenSigAutoGenDsp" SG_ 924 signal4085 1;
BA_ "signal136198" SG_ 924 signal4096 924;
BA_ "signal133356" SG_ 924 signal4096 924;
BA_ "GenSigTimeoutMsg_ecu13120" SG_ 924 signal4096 924;
BA_ "GenSigTimeoutMsg_ecu12594" SG_ 924 signal4096 924;
BA_ "NMH-WakeupAllowed" SG_ 924 signal4096 0;
BA_ "NWM-WakeupAllowed" SG_ 924 signal4096 0;
BA_ "GenSigSendType" SG_ 924 signal4096 7;
BA_ "GenSigEnvVarType" SG_ 924 signal4096 0;
BA_ "GenSigAutoGenSnd" SG_ 924 signal4096 1;
BA_ "GenSigAutoGenDsp" SG_ 924 signal4096 1;
BA_ "GenSigTimeoutMsg_ecu12990" SG_ 924 signal4110 924;
BA_ "NMH-WakeupAllowed" SG_ 924 signal4110 0;
BA_ "NWM-WakeupAllowed" SG_ 924 signal4110 0;
BA_ "GenSigSendType" SG_ 924 signal4110 7;
BA_ "GenSigEnvVarType" SG_ 924 signal4110 0;
BA_ "GenSigAutoGenSnd" SG_ 924 signal4110 1;
BA_ "GenSigAutoGenDsp" SG_ 924 signal4110 1;
BA_ "GenSigTimeoutMsg_ecu12594" SG_ 924 signal4121 924;
BA_ "NMH-WakeupAllowed" SG_ 924 signal4121 0;
BA_ "NWM-WakeupAllowed" SG_ 924 signal4121 0;
BA_ "GenSigSendType" SG_ 924 signal4121 7;
BA_ "GenSigEnvVarType" SG_ 924 signal4121 0;
BA_ "GenSigAutoGenSnd" SG_ 924 signal4121 1;
BA_ "GenSigAutoGenDsp" SG_ 924 signal4121 1;
BA_ "signal136198" SG_ 924 signal3845 924;
BA_ "signal133356" SG_ 924 signal3845 924;
BA_ "GenSigTimeoutMsg_ecu13120" SG_ 924 signal3845 924;
BA_ "NMH-WakeupAllowed" SG_ 924 signal3845 0;
BA_ "NWM-WakeupAllowed" SG_ 924 signal3845 0;
BA_ "GenSigSendType" SG_ 924 signal3845 7;
BA_ "GenSigEnvVarType" SG_ 924 signal3845 0;
BA_ "GenSigAutoGenSnd" SG_ 924 signal3845 1;
BA_ "GenSigAutoGenDsp" SG_ 924 signal3845 1;
BA_ "NMH-WakeupAllowed" SG_ 924 signal4145 0;
BA_ "NWM-WakeupAllowed" SG_ 924 signal4145 0;
BA_ "GenSigSendType" SG_ 924 signal4145 7;
BA_ "GenSigEnvVarType" SG_ 924 signal4145 0;
BA_ "GenSigAutoGenSnd" SG_ 924 signal4145 1;
BA_ "GenSigAutoGenDsp" SG_ 924 signal4145 1;
BA_ "signal136198" SG_ 924 signal4155 924;
BA_ "signal133356" SG_ 924 signal4155 924;
BA_ "GenSigTimeoutMsg_ecu13120" SG_ 924 signal4155 924;
BA_ "NMH-WakeupAllowed" SG_ 924 signal4155 0;
BA_ "NWM-WakeupAllowed" SG_ 924 signal4155 0;
BA_ "GenSigSendType" SG_ 924 signal4155 7;
BA_ "GenSigEnvVarType" SG_ 924 signal4155 0;
BA_ "GenSigAutoGenSnd" SG_ 924 signal4155 1;
BA_ "GenSigAutoGenDsp" SG_ 924 signal4155 1;
BA_ "GenSigTimeoutMsg_ecu12990" SG_ 924 signal4168 924;
BA_ "NMH-WakeupAllowed" SG_ 924 signal4168 0;
BA_ "NWM-WakeupAllowed" SG_ 924 signal4168 0;
BA_ "GenSigSendType" SG_ 924 signal4168 7;
BA_ "GenSigEnvVarType" SG_ 924 signal4168 0;
BA_ "GenSigAutoGenSnd" SG_ 924 signal4168 1;
BA_ "GenSigAutoGenDsp" SG_ 924 signal4168 1;
BA_ "NMH-WakeupAllowed" SG_ 924 signal4179 0;
BA_ "NWM-WakeupAllowed" SG_ 924 signal4179 0;
BA_ "GenSigSendType" SG_ 924 signal4179 7;
BA_ "GenSigEnvVarType" SG_ 924 signal4179 0;
BA_ "GenSigAutoGenSnd" SG_ 924 signal4179 1;
BA_ "GenSigAutoGenDsp" SG_ 924 signal4179 1;
BA_ "signal136198" SG_ 924 signal4189 924;
BA_ "signal133356" SG_ 924 signal4189 924;
BA_ "GenSigTimeoutMsg_ecu13120" SG_ 924 signal4189 924;
BA_ "NMH-WakeupAllowed" SG_ 924 signal4189 0;
BA_ "NWM-WakeupAllowed" SG_ 924 signal4189 0;
BA_ "GenSigSendType" SG_ 924 signal4189 7;
BA_ "GenSigEnvVarType" SG_ 924 signal4189 0;
BA_ "GenSigAutoGenSnd" SG_ 924 signal4189 1;
BA_ "GenSigAutoGenDsp" SG_ 924 signal4189 1;
BA_ "signal136198" SG_ 924 signal4202 924;
BA_ "signal133356" SG_ 924 signal4202 924;
BA_ "GenSigTimeoutMsg_ecu13120" SG_ 924 signal4202 924;
BA_ "NMH-WakeupAllowed" SG_ 924 signal4202 0;
BA_ "NWM-WakeupAllowed" SG_ 924 signal4202 0;
BA_ "GenSigStartValue" SG_ 924 signal4202 254;
BA_ "GenSigSendType" SG_ 924 signal4202 7;
BA_ "GenSigEnvVarType" SG_ 924 signal4202 1;
BA_ "GenSigAutoGenSnd" SG_ 924 signal4202 1;
BA_ "GenSigAutoGenDsp" SG_ 924 signal4202 1;
BA_ "signal136198" SG_ 924 signal4215 924;
BA_ "signal133356" SG_ 924 signal4215 924;
BA_ "GenSigTimeoutMsg_ecu13120" SG_ 924 signal4215 924;
BA_ "NMH-WakeupAllowed" SG_ 924 signal4215 0;
BA_ "NWM-WakeupAllowed" SG_ 924 signal4215 0;
BA_ "GenSigSendType" SG_ 924 signal4215 3;
BA_ "GenSigEnvVarType" SG_ 924 signal4215 0;
BA_ "GenSigAutoGenSnd" SG_ 924 signal4215 1;
BA_ "GenSigAutoGenDsp" SG_ 924 signal4215 1;
BA_ "NMH-WakeupAllowed" SG_ 924 signal4228 0;
BA_ "NWM-WakeupAllowed" SG_ 924 signal4228 0;
BA_ "GenSigSendType" SG_ 924 signal4228 3;
BA_ "GenSigEnvVarType" SG_ 924 signal4228 0;
BA_ "GenSigAutoGenSnd" SG_ 924 signal4228 1;
BA_ "GenSigAutoGenDsp" SG_ 924 signal4228 1;
BA_ "NMH-WakeupAllowed" SG_ 924 signal4238 0;
BA_ "NWM-WakeupAllowed" SG_ 924 signal4238 0;
BA_ "GenSigSendType" SG_ 924 signal4238 7;
BA_ "GenSigEnvVarType" SG_ 924 signal4238 0;
BA_ "GenSigAutoGenSnd" SG_ 924 signal4238 1;
BA_ "GenSigAutoGenDsp" SG_ 924 signal4238 1;
BA_ "NMH-WakeupAllowed" SG_ 924 signal4248 0;
BA_ "NWM-WakeupAllowed" SG_ 924 signal4248 0;
BA_ "GenSigSendType" SG_ 924 signal4248 7;
BA_ "GenSigEnvVarType" SG_ 924 signal4248 0;
BA_ "GenSigAutoGenSnd" SG_ 924 signal4248 1;
BA_ "GenSigAutoGenDsp" SG_ 924 signal4248 1;
BA_ "NMH-WakeupAllowed" SG_ 924 signal4258 0;
BA_ "NWM-WakeupAllowed" SG_ 924 signal4258 0;
BA_ "GenSigSendType" SG_ 924 signal4258 7;
BA_ "GenSigEnvVarType" SG_ 924 signal4258 0;
BA_ "GenSigAutoGenSnd" SG_ 924 signal4258 1;
BA_ "GenSigAutoGenDsp" SG_ 924 signal4258 1;
BA_ "NMH-WakeupAllowed" SG_ 1604 signal4274 0;
BA_ "NWM-WakeupAllowed" SG_ 1604 signal4274 0;
BA_ "GenSigStartValue" SG_ 1604 signal4274 1;
BA_ "GenSigSendType" SG_ 1604 signal4274 7;
BA_ "GenSigEnvVarType" SG_ 1604 signal4274 0;
BA_ "GenSigAutoGenSnd" SG_ 1604 signal4274 1;
BA_ "GenSigAutoGenDsp" SG_ 1604 signal4274 1;
BA_ "NMH-WakeupAllowed" SG_ 1604 signal4284 0;
BA_ "NWM-WakeupAllowed" SG_ 1604 signal4284 0;
BA_ "GenSigStartValue" SG_ 1604 signal4284 1;
BA_ "GenSigSendType" SG_ 1604 signal4284 7;
BA_ "GenSigEnvVarType" SG_ 1604 signal4284 0;
BA_ "GenSigAutoGenSnd" SG_ 1604 signal4284 1;
BA_ "GenSigAutoGenDsp" SG_ 1604 signal4284 1;
BA_ "NMH-WakeupAllowed" SG_ 1604 signal3928 0;
BA_ "NWM-WakeupAllowed" SG_ 1604 signal3928 0;
BA_ "GenSigStartValue" SG_ 1604 signal3928 1;
BA_ "GenSigSendType" SG_ 1604 signal3928 7;
BA_ "GenSigEnvVarType" SG_ 1604 signal3928 0;
BA_ "GenSigAutoGenSnd" SG_ 1604 signal3928 1;
BA_ "GenSigAutoGenDsp" SG_ 1604 signal3928 1;
BA_ "NMH-WakeupAllowed" SG_ 1604 signal3892 0;
BA_ "NWM-WakeupAllowed" SG_ 1604 signal3892 0;
BA_ "GenSigStartValue" SG_ 1604 signal3892 1;
BA_ "GenSigSendType" SG_ 1604 signal3892 7;
BA_ "GenSigEnvVarType" SG_ 1604 signal3892 0;
BA_ "GenSigAutoGenSnd" SG_ 1604 signal3892 1;
BA_ "GenSigAutoGenDsp" SG_ 1604 signal3892 1;
BA_ "GenSigTimeoutMsg_ecu11765" SG_ 1604 signal4314 1604;
BA_ "NMH-WakeupAllowed" SG_ 1604 signal4314 0;
BA_ "NWM-WakeupAllowed" SG_ 1604 signal4314 0;
BA_ "GenSigStartValue" SG_ 1604 signal4314 1;
BA_ "GenSigSendType" SG_ 1604 signal4314 7;
BA_ "GenSigEnvVarType" SG_ 1604 signal4314 0;
BA_ "GenSigAutoGenSnd" SG_ 1604 signal4314 1;
BA_ "GenSigAutoGenDsp" SG_ 1604 signal4314 1;
BA_ "NMH-WakeupAllowed" SG_ 1604 signal4325 0;
BA_ "NWM-WakeupAllowed" SG_ 1604 signal4325 0;
BA_ "GenSigStartValue" SG_ 1604 signal4325 1;
BA_ "GenSigSendType" SG_ 1604 signal4325 7;
BA_ "GenSigEnvVarType" SG_ 1604 signal4325 0;
BA_ "GenSigAutoGenSnd" SG_ 1604 signal4325 1;
BA_ "GenSigAutoGenDsp" SG_ 1604 signal4325 1;
BA_ "NMH-WakeupAllowed" SG_ 1604 signal4335 0;
BA_ "NWM-WakeupAllowed" SG_ 1604 signal4335 0;
BA_ "GenSigStartValue" SG_ 1604 signal4335 1;
BA_ "GenSigSendType" SG_ 1604 signal4335 7;
BA_ "GenSigEnvVarType" SG_ 1604 signal4335 0;
BA_ "GenSigAutoGenSnd" SG_ 1604 signal4335 1;
BA_ "GenSigAutoGenDsp" SG_ 1604 signal4335 1;
BA_ "NMH-WakeupAllowed" SG_ 1604 signal4345 0;
BA_ "NWM-WakeupAllowed" SG_ 1604 signal4345 0;
BA_ "GenSigStartValue" SG_ 1604 signal4345 1;
BA_ "GenSigSendType" SG_ 1604 signal4345 7;
BA_ "GenSigEnvVarType" SG_ 1604 signal4345 0;
BA_ "GenSigAutoGenSnd" SG_ 1604 signal4345 1;
BA_ "GenSigAutoGenDsp" SG_ 1604 signal4345 1;
BA_ "NMH-WakeupAllowed" SG_ 1604 signal4355 0;
BA_ "NWM-WakeupAllowed" SG_ 1604 signal4355 0;
BA_ "GenSigStartValue" SG_ 1604 signal4355 1;
BA_ "GenSigSendType" SG_ 1604 signal4355 7;
BA_ "GenSigEnvVarType" SG_ 1604 signal4355 0;
BA_ "GenSigAutoGenSnd" SG_ 1604 signal4355 1;
BA_ "GenSigAutoGenDsp" SG_ 1604 signal4355 1;
BA_ "NMH-WakeupAllowed" SG_ 1604 signal4365 0;
BA_ "NWM-WakeupAllowed" SG_ 1604 signal4365 0;
BA_ "GenSigStartValue" SG_ 1604 signal4365 1;
BA_ "GenSigSendType" SG_ 1604 signal4365 7;
BA_ "GenSigEnvVarType" SG_ 1604 signal4365 0;
BA_ "GenSigAutoGenSnd" SG_ 1604 signal4365 1;
BA_ "GenSigAutoGenDsp" SG_ 1604 signal4365 1;
BA_ "NMH-WakeupAllowed" SG_ 1604 signal4375 0;
BA_ "NWM-WakeupAllowed" SG_ 1604 signal4375 0;
BA_ "GenSigStartValue" SG_ 1604 signal4375 1;
BA_ "GenSigSendType" SG_ 1604 signal4375 7;
BA_ "GenSigEnvVarType" SG_ 1604 signal4375 0;
BA_ "GenSigAutoGenSnd" SG_ 1604 signal4375 1;
BA_ "GenSigAutoGenDsp" SG_ 1604 signal4375 1;
BA_ "NMH-WakeupAllowed" SG_ 1604 signal4385 0;
BA_ "NWM-WakeupAllowed" SG_ 1604 signal4385 0;
BA_ "GenSigStartValue" SG_ 1604 signal4385 1;
BA_ "GenSigSendType" SG_ 1604 signal4385 7;
BA_ "GenSigEnvVarType" SG_ 1604 signal4385 0;
BA_ "GenSigAutoGenSnd" SG_ 1604 signal4385 1;
BA_ "GenSigAutoGenDsp" SG_ 1604 signal4385 1;
BA_ "NMH-WakeupAllowed" SG_ 1604 signal4395 0;
BA_ "NWM-WakeupAllowed" SG_ 1604 signal4395 0;
BA_ "GenSigStartValue" SG_ 1604 signal4395 1;
BA_ "GenSigSendType" SG_ 1604 signal4395 7;
BA_ "GenSigEnvVarType" SG_ 1604 signal4395 0;
BA_ "GenSigAutoGenSnd" SG_ 1604 signal4395 1;
BA_ "GenSigAutoGenDsp" SG_ 1604 signal4395 1;
BA_ "NMH-WakeupAllowed" SG_ 1604 signal4405 0;
BA_ "NWM-WakeupAllowed" SG_ 1604 signal4405 0;
BA_ "GenSigStartValue" SG_ 1604 signal4405 1;
BA_ "GenSigSendType" SG_ 1604 signal4405 7;
BA_ "GenSigEnvVarType" SG_ 1604 signal4405 0;
BA_ "GenSigAutoGenSnd" SG_ 1604 signal4405 1;
BA_ "GenSigAutoGenDsp" SG_ 1604 signal4405 1;
BA_ "NMH-WakeupAllowed" SG_ 1604 signal4415 0;
BA_ "NWM-WakeupAllowed" SG_ 1604 signal4415 0;
BA_ "GenSigStartValue" SG_ 1604 signal4415 1;
BA_ "GenSigSendType" SG_ 1604 signal4415 7;
BA_ "GenSigEnvVarType" SG_ 1604 signal4415 0;
BA_ "GenSigAutoGenSnd" SG_ 1604 signal4415 1;
BA_ "GenSigAutoGenDsp" SG_ 1604 signal4415 1;
BA_ "NMH-WakeupAllowed" SG_ 1604 signal4425 0;
BA_ "NWM-WakeupAllowed" SG_ 1604 signal4425 0;
BA_ "GenSigStartValue" SG_ 1604 signal4425 1;
BA_ "GenSigSendType" SG_ 1604 signal4425 7;
BA_ "GenSigEnvVarType" SG_ 1604 signal4425 0;
BA_ "GenSigAutoGenSnd" SG_ 1604 signal4425 1;
BA_ "GenSigAutoGenDsp" SG_ 1604 signal4425 1;
BA_ "NMH-WakeupAllowed" SG_ 1604 signal4435 0;
BA_ "NWM-WakeupAllowed" SG_ 1604 signal4435 0;
BA_ "GenSigSendType" SG_ 1604 signal4435 7;
BA_ "GenSigEnvVarType" SG_ 1604 signal4435 0;
BA_ "GenSigAutoGenSnd" SG_ 1604 signal4435 1;
BA_ "GenSigAutoGenDsp" SG_ 1604 signal4435 1;
BA_ "NMH-WakeupAllowed" SG_ 1604 signal4445 0;
BA_ "NWM-WakeupAllowed" SG_ 1604 signal4445 0;
BA_ "GenSigSendType" SG_ 1604 signal4445 7;
BA_ "GenSigEnvVarType" SG_ 1604 signal4445 0;
BA_ "GenSigAutoGenSnd" SG_ 1604 signal4445 1;
BA_ "GenSigAutoGenDsp" SG_ 1604 signal4445 1;
BA_ "NMH-WakeupAllowed" SG_ 1604 signal4455 0;
BA_ "NWM-WakeupAllowed" SG_ 1604 signal4455 0;
BA_ "GenSigSendType" SG_ 1604 signal4455 7;
BA_ "GenSigEnvVarType" SG_ 1604 signal4455 0;
BA_ "GenSigAutoGenSnd" SG_ 1604 signal4455 1;
BA_ "GenSigAutoGenDsp" SG_ 1604 signal4455 1;
BA_ "NMH-WakeupAllowed" SG_ 1604 signal4465 0;
BA_ "NWM-WakeupAllowed" SG_ 1604 signal4465 0;
BA_ "GenSigSendType" SG_ 1604 signal4465 7;
BA_ "GenSigEnvVarType" SG_ 1604 signal4465 0;
BA_ "GenSigAutoGenSnd" SG_ 1604 signal4465 1;
BA_ "GenSigAutoGenDsp" SG_ 1604 signal4465 1;
BA_ "NMH-WakeupAllowed" SG_ 1604 signal4475 0;
BA_ "NWM-WakeupAllowed" SG_ 1604 signal4475 0;
BA_ "GenSigSendType" SG_ 1604 signal4475 7;
BA_ "GenSigEnvVarType" SG_ 1604 signal4475 0;
BA_ "GenSigAutoGenSnd" SG_ 1604 signal4475 1;
BA_ "GenSigAutoGenDsp" SG_ 1604 signal4475 1;
BA_ "NMH-WakeupAllowed" SG_ 1604 signal4485 0;
BA_ "NWM-WakeupAllowed" SG_ 1604 signal4485 0;
BA_ "GenSigSendType" SG_ 1604 signal4485 7;
BA_ "GenSigEnvVarType" SG_ 1604 signal4485 0;
BA_ "GenSigAutoGenSnd" SG_ 1604 signal4485 1;
BA_ "GenSigAutoGenDsp" SG_ 1604 signal4485 1;
BA_ "NMH-WakeupAllowed" SG_ 1604 signal4495 0;
BA_ "NWM-WakeupAllowed" SG_ 1604 signal4495 0;
BA_ "GenSigSendType" SG_ 1604 signal4495 3;
BA_ "GenSigEnvVarType" SG_ 1604 signal4495 0;
BA_ "GenSigAutoGenSnd" SG_ 1604 signal4495 1;
BA_ "GenSigAutoGenDsp" SG_ 1604 signal4495 1;
BA_ "GenSigTimeoutMsg_ecu11765" SG_ 1604 signal4505 1604;
BA_ "NMH-WakeupAllowed" SG_ 1604 signal4505 0;
BA_ "NWM-WakeupAllowed" SG_ 1604 signal4505 0;
BA_ "GenSigSendType" SG_ 1604 signal4505 7;
BA_ "GenSigEnvVarType" SG_ 1604 signal4505 0;
BA_ "GenSigAutoGenSnd" SG_ 1604 signal4505 1;
BA_ "GenSigAutoGenDsp" SG_ 1604 signal4505 1;
BA_ "signal136198" SG_ 130 signal4522 130;
BA_ "signal133356" SG_ 130 signal4522 130;
BA_ "GenSigTimeoutMsg_ecu13120" SG_ 130 signal4522 130;
BA_ "GenSigTimeoutMsg_ecu13186" SG_ 130 signal4522 130;
BA_ "GenSigTimeoutMsg_ecu12594" SG_ 130 signal4522 130;
BA_ "NMH-WakeupAllowed" SG_ 130 signal4522 0;
BA_ "NWM-WakeupAllowed" SG_ 130 signal4522 0;
BA_ "GenSigSendType" SG_ 130 signal4522 7;
BA_ "GenSigEnvVarType" SG_ 130 signal4522 0;
BA_ "GenSigAutoGenSnd" SG_ 130 signal4522 1;
BA_ "GenSigAutoGenDsp" SG_ 130 signal4522 1;
BA_ "signal136198" SG_ 130 signal4517_BZ 130;
BA_ "signal133356" SG_ 130 signal4517_BZ 130;
BA_ "GenSigTimeoutMsg_ecu13120" SG_ 130 signal4517_BZ 130;
BA_ "GenSigTimeoutMsg_ecu13186" SG_ 130 signal4517_BZ 130;
BA_ "GenSigTimeoutMsg_ecu12594" SG_ 130 signal4517_BZ 130;
BA_ "NMH-WakeupAllowed" SG_ 130 signal4517_BZ 0;
BA_ "NWM-WakeupAllowed" SG_ 130 signal4517_BZ 0;
BA_ "GenSigSendType" SG_ 130 signal4517_BZ 7;
BA_ "GenSigEnvVarType" SG_ 130 signal4517_BZ 0;
BA_ "GenSigAutoGenSnd" SG_ 130 signal4517_BZ 1;
BA_ "GenSigAutoGenDsp" SG_ 130 signal4517_BZ 1;
BA_ "signal136198" SG_ 130 signal4552 130;
BA_ "signal133356" SG_ 130 signal4552 130;
BA_ "GenSigTimeoutMsg_ecu13120" SG_ 130 signal4552 130;
BA_ "GenSigTimeoutMsg_ecu13186" SG_ 130 signal4552 130;
BA_ "NMH-WakeupAllowed" SG_ 130 signal4552 0;
BA_ "NWM-WakeupAllowed" SG_ 130 signal4552 0;
BA_ "GenSigSendType" SG_ 130 signal4552 7;
BA_ "GenSigEnvVarType" SG_ 130 signal4552 0;
BA_ "GenSigAutoGenSnd" SG_ 130 signal4552 1;
BA_ "GenSigAutoGenDsp" SG_ 130 signal4552 1;
BA_ "signal136198" SG_ 130 signal4566 130;
BA_ "signal133356" SG_ 130 signal4566 130;
BA_ "GenSigTimeoutMsg_ecu13120" SG_ 130 signal4566 130;
BA_ "GenSigTimeoutMsg_ecu13186" SG_ 130 signal4566 130;
BA_ "GenSigTimeoutMsg_ecu12594" SG_ 130 signal4566 130;
BA_ "NMH-WakeupAllowed" SG_ 130 signal4566 0;
BA_ "NWM-WakeupAllowed" SG_ 130 signal4566 0;
BA_ "GenSigSendType" SG_ 130 signal4566 7;
BA_ "GenSigEnvVarType" SG_ 130 signal4566 0;
BA_ "GenSigAutoGenSnd" SG_ 130 signal4566 1;
BA_ "GenSigAutoGenDsp" SG_ 130 signal4566 1;
BA_ "signal136198" SG_ 130 signal4581 130;
BA_ "signal133356" SG_ 130 signal4581 130;
BA_ "GenSigTimeoutMsg_ecu13120" SG_ 130 signal4581 130;
BA_ "GenSigTimeoutMsg_ecu13186" SG_ 130 signal4581 130;
BA_ "NMH-WakeupAllowed" SG_ 130 signal4581 0;
BA_ "NWM-WakeupAllowed" SG_ 130 signal4581 0;
BA_ "GenSigStartValue" SG_ 130 signal4581 1022;
BA_ "GenSigSendType" SG_ 130 signal4581 7;
BA_ "GenSigEnvVarType" SG_ 130 signal4581 0;
BA_ "GenSigAutoGenSnd" SG_ 130 signal4581 1;
BA_ "GenSigAutoGenDsp" SG_ 130 signal4581 1;
BA_ "signal136198" SG_ 130 signal4595 130;
BA_ "signal133356" SG_ 130 signal4595 130;
BA_ "GenSigTimeoutMsg_ecu13120" SG_ 130 signal4595 130;
BA_ "GenSigTimeoutMsg_ecu13186" SG_ 130 signal4595 130;
BA_ "NMH-WakeupAllowed" SG_ 130 signal4595 0;
BA_ "NWM-WakeupAllowed" SG_ 130 signal4595 0;
BA_ "GenSigSendType" SG_ 130 signal4595 7;
BA_ "GenSigEnvVarType" SG_ 130 signal4595 0;
BA_ "GenSigAutoGenSnd" SG_ 130 signal4595 1;
BA_ "GenSigAutoGenDsp" SG_ 130 signal4595 1;
BA_ "GenSigTimeoutMsg_ecu13186" SG_ 130 signal4609 130;
BA_ "NMH-WakeupAllowed" SG_ 130 signal4609 0;
BA_ "NWM-WakeupAllowed" SG_ 130 signal4609 0;
BA_ "GenSigSendType" SG_ 130 signal4609 7;
BA_ "GenSigEnvVarType" SG_ 130 signal4609 0;
BA_ "GenSigAutoGenSnd" SG_ 130 signal4609 1;
BA_ "GenSigAutoGenDsp" SG_ 130 signal4609 1;
BA_ "signal136198" SG_ 130 signal4620 130;
BA_ "signal133356" SG_ 130 signal4620 130;
BA_ "GenSigTimeoutMsg_ecu13120" SG_ 130 signal4620 130;
BA_ "GenSigTimeoutMsg_ecu13186" SG_ 130 signal4620 130;
BA_ "NMH-WakeupAllowed" SG_ 130 signal4620 0;
BA_ "NWM-WakeupAllowed" SG_ 130 signal4620 0;
BA_ "GenSigSendType" SG_ 130 signal4620 7;
BA_ "GenSigEnvVarType" SG_ 130 signal4620 0;
BA_ "GenSigAutoGenSnd" SG_ 130 signal4620 1;
BA_ "GenSigAutoGenDsp" SG_ 130 signal4620 1;
BA_ "signal136198" SG_ 130 signal4634 130;
BA_ "signal133356" SG_ 130 signal4634 130;
BA_ "GenSigTimeoutMsg_ecu13120" SG_ 130 signal4634 130;
BA_ "GenSigTimeoutMsg_ecu13186" SG_ 130 signal4634 130;
BA_ "NMH-WakeupAllowed" SG_ 130 signal4634 0;
BA_ "NWM-WakeupAllowed" SG_ 130 signal4634 0;
BA_ "GenSigSendType" SG_ 130 signal4634 7;
BA_ "GenSigEnvVarType" SG_ 130 signal4634 0;
BA_ "GenSigAutoGenSnd" SG_ 130 signal4634 1;
BA_ "GenSigAutoGenDsp" SG_ 130 signal4634 1;
BA_ "signal136198" SG_ 130 signal4648 130;
BA_ "signal133356" SG_ 130 signal4648 130;
BA_ "GenSigTimeoutMsg_ecu13120" SG_ 130 signal4648 130;
BA_ "GenSigTimeoutMsg_ecu13186" SG_ 130 signal4648 130;
BA_ "NMH-WakeupAllowed" SG_ 130 signal4648 0;
BA_ "NWM-WakeupAllowed" SG_ 130 signal4648 0;
BA_ "GenSigStartValue" SG_ 130 signal4648 1022;
BA_ "GenSigSendType" SG_ 130 signal4648 7;
BA_ "GenSigEnvVarType" SG_ 130 signal4648 0;
BA_ "GenSigAutoGenSnd" SG_ 130 signal4648 1;
BA_ "GenSigAutoGenDsp" SG_ 130 signal4648 1;
BA_ "signal136198" SG_ 130 signal4662 130;
BA_ "signal133356" SG_ 130 signal4662 130;
BA_ "GenSigTimeoutMsg_ecu13120" SG_ 130 signal4662 130;
BA_ "GenSigTimeoutMsg_ecu13186" SG_ 130 signal4662 130;
BA_ "NMH-WakeupAllowed" SG_ 130 signal4662 0;
BA_ "NWM-WakeupAllowed" SG_ 130 signal4662 0;
BA_ "GenSigSendType" SG_ 130 signal4662 7;
BA_ "GenSigEnvVarType" SG_ 130 signal4662 0;
BA_ "GenSigAutoGenSnd" SG_ 130 signal4662 1;
BA_ "GenSigAutoGenDsp" SG_ 130 signal4662 1;
BA_ "signal136198" SG_ 130 signal4676 130;
BA_ "signal133356" SG_ 130 signal4676 130;
BA_ "GenSigTimeoutMsg_ecu13120" SG_ 130 signal4676 130;
BA_ "GenSigTimeoutMsg_ecu13186" SG_ 130 signal4676 130;
BA_ "NMH-WakeupAllowed" SG_ 130 signal4676 0;
BA_ "NWM-WakeupAllowed" SG_ 130 signal4676 0;
BA_ "GenSigSendType" SG_ 130 signal4676 7;
BA_ "GenSigEnvVarType" SG_ 130 signal4676 0;
BA_ "GenSigAutoGenSnd" SG_ 130 signal4676 1;
BA_ "GenSigAutoGenDsp" SG_ 130 signal4676 1;
BA_ "GenSigTimeoutMsg_ecu13186" SG_ 130 signal4690 130;
BA_ "NMH-WakeupAllowed" SG_ 130 signal4690 0;
BA_ "NWM-WakeupAllowed" SG_ 130 signal4690 0;
BA_ "GenSigSendType" SG_ 130 signal4690 7;
BA_ "GenSigEnvVarType" SG_ 130 signal4690 0;
BA_ "GenSigAutoGenSnd" SG_ 130 signal4690 1;
BA_ "GenSigAutoGenDsp" SG_ 130 signal4690 1;
